VERSION ""

NS_ :

BS_:

BU_: HCM IPMA_ADAS PSCM ABS_ESC PCM ECM_HEV VDM CMR_DSMC SOBDMC_HPCM GWM _delete AWD_DLCM GENERIC TSTR

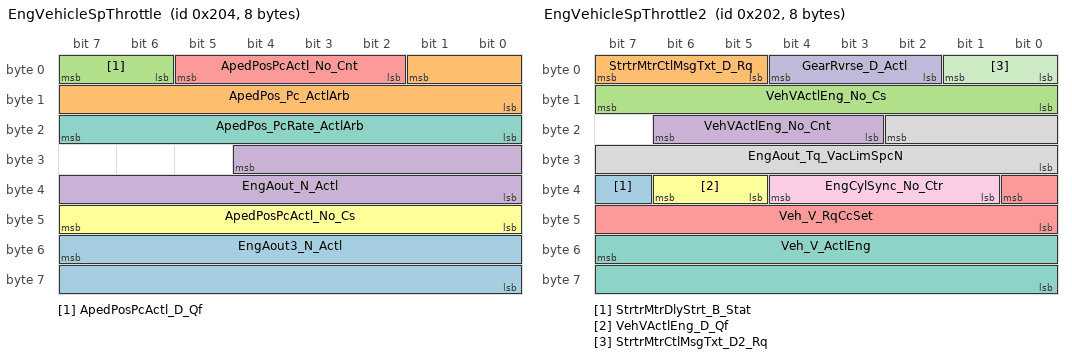
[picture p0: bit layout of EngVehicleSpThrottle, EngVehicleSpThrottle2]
BO_ 516 EngVehicleSpThrottle: 8 ECM_HEV
 SG_ EngAout3_N_Actl : 55|16@0+ (0.25,0) [0|16383.5] "RPM"  SOBDMC_HPCM,GWM
 SG_ ApedPos_Pc_ActlArb : 1|10@0+ (0.1,0) [0|102.3] "%"  CMR_DSMC,VDM,SOBDMC_HPCM,HCM,IPMA_ADAS,ABS_ESC,GWM,AWD_DLCM
 SG_ ApedPosPcActl_D_Qf : 7|2@0+ (1,0) [0|3] "SED"  CMR_DSMC,VDM,SOBDMC_HPCM,HCM,IPMA_ADAS,ABS_ESC,GWM,AWD_DLCM
 SG_ EngAout_N_Actl : 28|13@0+ (2,0) [0|16382] "rpm"  VDM,ABS_ESC,GWM,AWD_DLCM
 SG_ ApedPosPcActl_No_Cnt : 5|4@0+ (1,0) [0|15] "Unitless"  SOBDMC_HPCM,GWM
 SG_ ApedPosPcActl_No_Cs : 47|8@0+ (1,0) [0|255] "Unitless"  SOBDMC_HPCM,GWM
 SG_ ApedPos_PcRate_ActlArb : 23|8@0+ (0.04,-5) [-5|5.12] "%/ms"  SOBDMC_HPCM,AWD_DLCM,GWM

BO_ 514 EngVehicleSpThrottle2: 8 ECM_HEV
 SG_ StrtrMtrDlyStrt_B_Stat : 39|1@0+ (1,0) [0|1] "SED"  GWM
 SG_ StrtrMtrCtlMsgTxt_D_Rq : 7|3@0+ (1,0) [0|7] "SED"  GWM
 SG_ VehVActlEng_No_Cs : 15|8@0+ (1,0) [0|255] "Unitless"  PSCM,GWM
 SG_ VehVActlEng_No_Cnt : 22|4@0+ (1,0) [0|15] "Unitless"  PSCM,GWM
 SG_ Veh_V_RqCcSet : 32|9@0+ (0.5,0) [0|255.5] "kph"  SOBDMC_HPCM,IPMA_ADAS,GWM
 SG_ VehVActlEng_D_Qf : 38|2@0+ (1,0) [0|3] "SED"  HCM,IPMA_ADAS,PSCM,GWM,VDM,AWD_DLCM
 SG_ Veh_V_ActlEng : 55|16@0+ (0.01,0) [0|655.35] "kph"  SOBDMC_HPCM,HCM,IPMA_ADAS,PSCM,VDM,GWM,AWD_DLCM
 SG_ EngAout_Tq_VacLimSpcN : 18|11@0+ (1,-500) [-500|1547] "Nm"  SOBDMC_HPCM,GWM
 SG_ EngCylSync_No_Ctr : 36|4@0+ (1,0) [0|15] "unitless"  SOBDMC_HPCM,GWM
 SG_ GearRvrse_D_Actl : 4|3@0+ (1,0) [0|7] "SED"  IPMA_ADAS,CMR_DSMC,ABS_ESC,PSCM,GWM,HCM
 SG_ StrtrMtrCtlMsgTxt_D2_Rq : 1|2@0+ (1,0) [0|3] "SED"  GWM

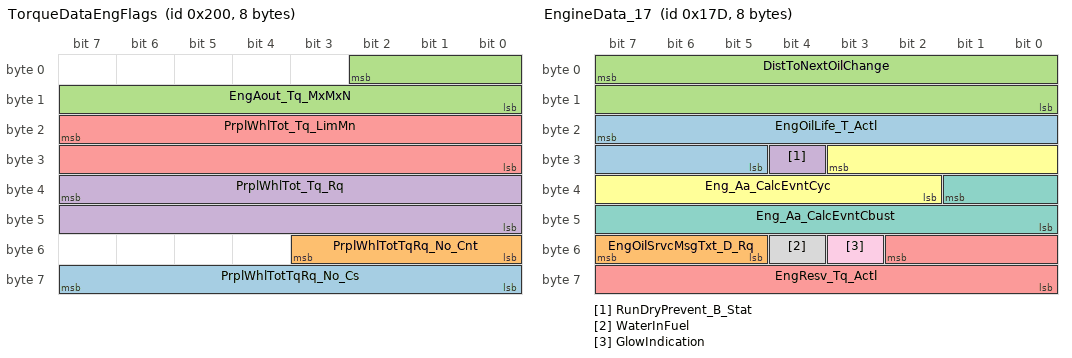
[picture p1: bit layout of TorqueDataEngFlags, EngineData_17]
BO_ 512 TorqueDataEngFlags: 8 ECM_HEV
 SG_ PrplWhlTotTqRq_No_Cs : 63|8@0+ (1,0) [0|255] "Unitless"  SOBDMC_HPCM,GWM
 SG_ PrplWhlTotTqRq_No_Cnt : 51|4@0+ (1,0) [0|15] "Unitless"  SOBDMC_HPCM,GWM
 SG_ EngAout_Tq_MxMxN : 2|11@0+ (1,-500) [-500|1547] "Nm"  SOBDMC_HPCM,GWM
 SG_ PrplWhlTot_Tq_Rq : 39|16@0+ (4,-131072) [-131072|131068] "Nm"  VDM,SOBDMC_HPCM,ABS_ESC,GWM,AWD_DLCM
 SG_ PrplWhlTot_Tq_LimMn : 23|16@0+ (4,-131072) [-131072|131068] "Nm"  GWM

BO_ 381 EngineData_17: 8 PCM
 SG_ EngOilLife_T_Actl : 23|11@0+ (1,0) [0|2047] "days"  GWM
 SG_ EngOilSrvcMsgTxt_D_Rq : 55|3@0+ (1,0) [0|7] "SED"  GWM
 SG_ DistToNextOilChange : 7|16@0+ (1,0) [0|65535] "unitless"  GWM
 SG_ RunDryPrevent_B_Stat : 28|1@0+ (1,0) [0|1] "SED"  GWM
 SG_ EngResv_Tq_Actl : 50|11@0+ (1,-500) [-500|1547] "Nm"  GWM
 SG_ Eng_Aa_CalcEvntCyc : 27|10@0+ (0.05,-25.6) [-25.6|25.55] "rpm/ms"  GWM
 SG_ Eng_Aa_CalcEvntCbust : 33|10@0+ (0.05,-25.6) [-25.6|25.55] "rpm/ms"  GWM
 SG_ WaterInFuel : 52|1@0+ (1,0) [0|1] "SED"  GWM
 SG_ GlowIndication : 51|1@0+ (1,0) [0|1] "SED"  GWM

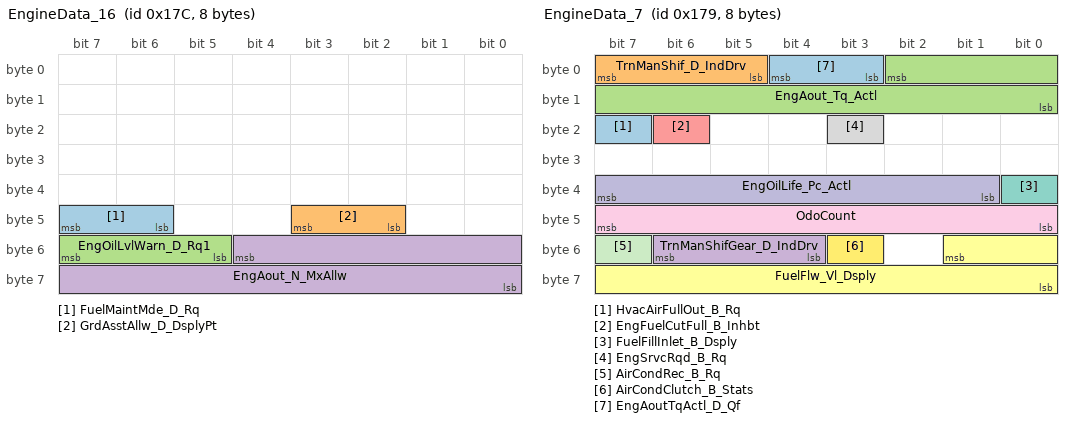
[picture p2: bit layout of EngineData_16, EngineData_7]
BO_ 380 EngineData_16: 8 PCM
 SG_ FuelMaintMde_D_Rq : 47|2@0+ (1,0) [0|3] "SED"  SOBDMC_HPCM,GWM
 SG_ GrdAsstAllw_D_DsplyPt : 43|2@0+ (1,0) [0|3] "SED"  SOBDMC_HPCM,GWM
 SG_ EngOilLvlWarn_D_Rq1 : 55|3@0+ (1,0) [0|7] "SED"  GWM
 SG_ EngAout_N_MxAllw : 52|13@0+ (2,0) [0|16382] "rpm"  SOBDMC_HPCM,GWM

BO_ 377 EngineData_7: 8 ECM_HEV
 SG_ HvacAirFullOut_B_Rq : 23|1@0+ (1,0) [0|1] "SED"  GWM
 SG_ TrnManShif_D_IndDrv : 7|3@0+ (1,0) [0|7] "Unitless"  GWM
 SG_ EngAout_Tq_Actl : 2|11@0+ (1,-500) [-500|1547] "Nm"  SOBDMC_HPCM,GWM
 SG_ TrnManShifGear_D_IndDrv : 54|3@0+ (1,0) [0|7] "SED"  GWM
 SG_ EngFuelCutFull_B_Inhbt : 22|1@0+ (1,0) [0|1] "SED"  SOBDMC_HPCM,GWM
 SG_ FuelFlw_Vl_Dsply : 49|10@0+ (25,0) [0|25575] "Micro_Liter"  SOBDMC_HPCM,GWM
 SG_ FuelFillInlet_B_Dsply : 32|1@0+ (1,0) [0|1] "SED"  GWM
 SG_ EngSrvcRqd_B_Rq : 19|1@0+ (1,0) [0|1] "SED"  GWM
 SG_ OdoCount : 47|8@0+ (0.2,0) [0|50.8] "Meters"  GWM
 SG_ EngOilLife_Pc_Actl : 39|7@0+ (1,0) [0|100] "Percent"  GWM
 SG_ AirCondRec_B_Rq : 55|1@0+ (1,0) [0|1] "SED"  GWM
 SG_ AirCondClutch_B_Stats : 51|1@0+ (1,0) [0|1] "SED"  GWM
 SG_ EngAoutTqActl_D_Qf : 4|2@0+ (1,0) [0|3] "SED"  SOBDMC_HPCM,GWM

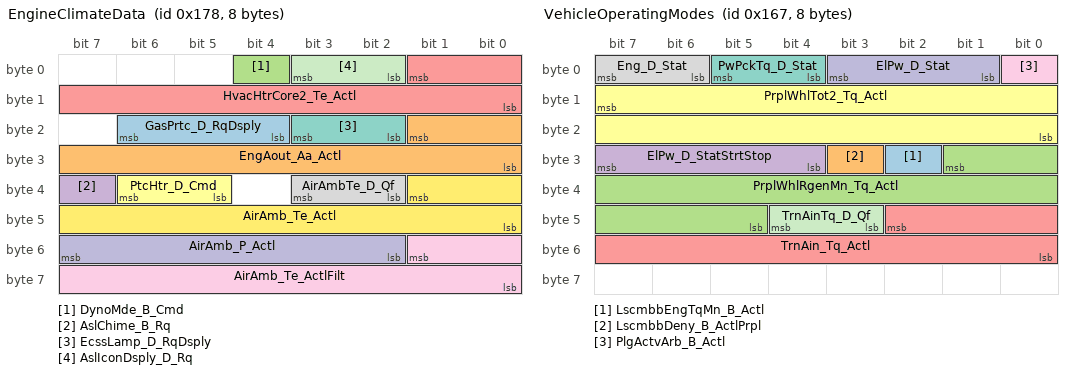
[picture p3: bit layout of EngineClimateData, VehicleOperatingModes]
BO_ 376 EngineClimateData: 8 ECM_HEV
 SG_ GasPrtc_D_RqDsply : 22|3@0+ (1,0) [0|7] "SED"  GWM
 SG_ EngAout_Aa_Actl : 17|10@0+ (0.05,-25.6) [-25.6|25.55] "rpm/ms"  ABS_ESC,GWM
 SG_ DynoMde_B_Cmd : 4|1@0+ (1,0) [0|1] "SED"  SOBDMC_HPCM,ABS_ESC,GWM
 SG_ AslChime_B_Rq : 39|1@0+ (1,0) [0|1] "SED"  GWM
 SG_ HvacHtrCore2_Te_Actl : 1|10@0+ (0.25,-50) [-50|205.5] "degC"  SOBDMC_HPCM,GWM
 SG_ PtcHtr_D_Cmd : 38|2@0+ (1,0) [0|3] "SED"  SOBDMC_HPCM,GWM
 SG_ EcssLamp_D_RqDsply : 19|2@0+ (1,0) [0|3] "SED"  GWM
 SG_ AirAmbTe_D_Qf : 35|2@0+ (1,0) [0|3] "SED"  SOBDMC_HPCM,IPMA_ADAS,ABS_ESC,GWM,AWD_DLCM
 SG_ AirAmb_Te_ActlFilt : 49|10@0+ (0.25,-128) [-128|127.75] "deg C"  SOBDMC_HPCM,IPMA_ADAS,GWM
 SG_ AirAmb_P_Actl : 55|6@0+ (10,500) [500|1110] "mbar"  GWM
 SG_ AslIconDsply_D_Rq : 3|2@0+ (1,0) [0|3] "SED"  GWM
 SG_ AirAmb_Te_Actl : 33|10@0+ (0.25,-128) [-128|127.75] "degC"  AWD_DLCM,ABS_ESC,GWM

BO_ 373 EngineData_11: 8 ECM_HEV
 SG_ EngFuelCutFull_B_Allw : 34|1@0+ (1,0) [0|1] "SED"  SOBDMC_HPCM,GWM
 SG_ EngAout_Tq_MxActlN : 2|11@0+ (1,-500) [-500|1547] "Nm"  GWM,GENERIC

BO_ 359 VehicleOperatingModes: 8 PCM
 SG_ LscmbbEngTqMn_B_Actl : 26|1@0+ (1,0) [0|1] "SED"  GWM
 SG_ LscmbbDeny_B_ActlPrpl : 27|1@0+ (1,0) [0|1] "SED"  GWM
 SG_ PrplWhlRgenMn_Tq_Actl : 25|13@0+ (4,-16380) [-16380|16380] "Nm"  ABS_ESC,GWM
 SG_ ElPw_D_StatStrtStop : 31|4@0+ (1,0) [0|15] "SED"  PSCM,GWM
 SG_ TrnAin_Tq_Actl : 42|11@0+ (1,-500) [-500|1547] "Nm"  GWM,AWD_DLCM
 SG_ PrplWhlTot2_Tq_Actl : 15|16@0+ (4,-131072) [-131072|131060] "Nm"  ABS_ESC,ECM_HEV,PSCM,GWM,AWD_DLCM
 SG_ PwPckTq_D_Stat : 5|2@0+ (1,0) [0|3] "SED"  VDM,HCM,IPMA_ADAS,ABS_ESC,ECM_HEV,PSCM,CMR_DSMC,GWM,AWD_DLCM
 SG_ Eng_D_Stat : 7|2@0+ (1,0) [0|3] "SED"  ABS_ESC,GWM,AWD_DLCM
 SG_ PlgActvArb_B_Actl : 0|1@0+ (1,0) [0|1] "SED"  GWM,ECM_HEV
 SG_ ElPw_D_Stat : 3|3@0+ (1,0) [0|7] "SED"  VDM,HCM,IPMA_ADAS,ABS_ESC,ECM_HEV,PSCM,GWM,CMR_DSMC,AWD_DLCM
 SG_ TrnAinTq_D_Qf : 44|2@0+ (1,0) [0|3] "SED"  GWM,AWD_DLCM

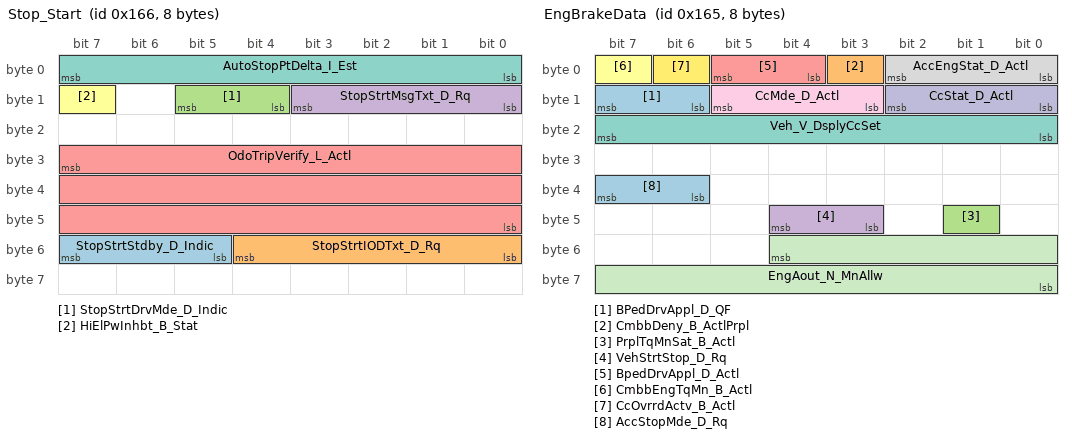
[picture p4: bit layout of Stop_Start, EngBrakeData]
BO_ 358 Stop_Start: 8 ECM_HEV
 SG_ StopStrtStdby_D_Indic : 55|3@0+ (1,0) [0|7] "SED"  GWM
 SG_ StopStrtIODTxt_D_Rq : 52|5@0+ (1,0) [0|31] "SED"  GWM
 SG_ StopStrtDrvMde_D_Indic : 13|2@0+ (1,0) [0|3] "SED"  GWM
 SG_ StopStrtMsgTxt_D_Rq : 11|4@0+ (1,0) [0|15] "SED"  GWM
 SG_ OdoTripVerify_L_Actl : 31|24@0+ (0.1,0) [0|1677721.4] "km"  GWM
 SG_ HiElPwInhbt_B_Stat : 15|1@0+ (1,0) [0|1] "SED"  GWM
 SG_ AutoStopPtDelta_I_Est : 7|8@0+ (1,-127) [-127|127] "Amps"  GWM

BO_ 357 EngBrakeData: 8 ECM_HEV
 SG_ BPedDrvAppl_D_QF : 15|2@0+ (1,0) [0|3] "SED"  SOBDMC_HPCM,IPMA_ADAS,ABS_ESC,GWM,CMR_DSMC,AWD_DLCM
 SG_ CmbbDeny_B_ActlPrpl : 3|1@0+ (1,0) [0|1] "SED"  IPMA_ADAS,GWM
 SG_ PrplTqMnSat_B_Actl : 41|1@0+ (1,0) [0|1] "SED"  IPMA_ADAS,GWM
 SG_ VehStrtStop_D_Rq : 44|2@0+ (1,0) [0|3] "SED"  SOBDMC_HPCM,GWM
 SG_ BpedDrvAppl_D_Actl : 5|2@0+ (1,0) [0|3] "SED"  SOBDMC_HPCM,IPMA_ADAS,ABS_ESC,GWM,CMR_DSMC,AWD_DLCM
 SG_ CmbbEngTqMn_B_Actl : 7|1@0+ (1,0) [0|1] "SED"  IPMA_ADAS,GWM
 SG_ Veh_V_DsplyCcSet : 23|8@0+ (1,0) [0|253] "Unitless"  GWM,IPMA_ADAS
 SG_ AccEngStat_D_Actl : 2|3@0+ (1,0) [0|7] "SED"  IPMA_ADAS,GWM
 SG_ CcMde_D_Actl : 13|3@0+ (1,0) [0|7] "SED"  GWM,VDM
 SG_ CcStat_D_Actl : 10|3@0+ (1,0) [0|7] "SED"  SOBDMC_HPCM,IPMA_ADAS,ABS_ESC,GWM,CMR_DSMC,AWD_DLCM
 SG_ EngAout_N_MnAllw : 52|13@0+ (2,0) [0|16382] "rpm"  SOBDMC_HPCM,GWM
 SG_ CcOvrrdActv_B_Actl : 6|1@0+ (1,0) [0|1] "SED"  IPMA_ADAS,ABS_ESC,GWM,VDM,AWD_DLCM
 SG_ AccStopMde_D_Rq : 39|2@0+ (1,0) [0|3] "SED"  IPMA_ADAS,ABS_ESC,GWM

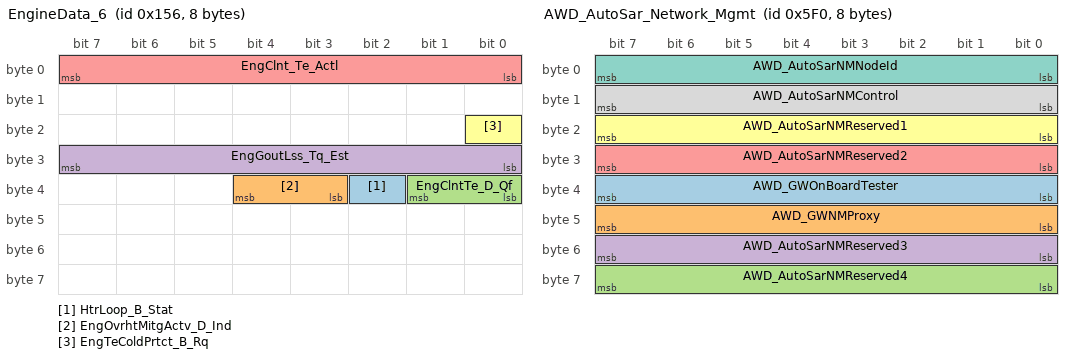
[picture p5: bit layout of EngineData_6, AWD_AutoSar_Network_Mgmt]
BO_ 342 EngineData_6: 8 ECM_HEV
 SG_ HtrLoop_B_Stat : 34|1@0+ (1,0) [0|1] "SED"  SOBDMC_HPCM,GWM
 SG_ EngOvrhtMitgActv_D_Ind : 36|2@0+ (1,0) [0|3] "SED"  GWM
 SG_ EngClntTe_D_Qf : 33|2@0+ (1,0) [0|3] "SED"  VDM,SOBDMC_HPCM,GWM,AWD_DLCM
 SG_ EngGoutLss_Tq_Est : 31|8@0+ (1,0) [0|255] "Nm"  SOBDMC_HPCM,GWM
 SG_ EngClnt_Te_Actl : 7|8@0+ (1,-60) [-60|195] "degC"  VDM,SOBDMC_HPCM,GWM,AWD_DLCM
 SG_ EngTeColdPrtct_B_Rq : 16|1@0+ (1,0) [0|1] "SED"  GWM

BO_ 1520 AWD_AutoSar_Network_Mgmt: 8 AWD_DLCM
 SG_ AWD_GWOnBoardTester : 39|8@0+ (1,0) [0|255] "unitless"  GENERIC
 SG_ AWD_GWNMProxy : 47|8@0+ (1,0) [0|255] "unitless"  GENERIC
 SG_ AWD_AutoSarNMReserved4 : 63|8@0+ (1,0) [0|255] "unitless"  GENERIC
 SG_ AWD_AutoSarNMReserved3 : 55|8@0+ (1,0) [0|255] "unitless"  GENERIC
 SG_ AWD_AutoSarNMReserved2 : 31|8@0+ (1,0) [0|255] "unitless"  GENERIC
 SG_ AWD_AutoSarNMReserved1 : 23|8@0+ (1,0) [0|255] "unitless"  GENERIC
 SG_ AWD_AutoSarNMNodeId : 7|8@0+ (1,0) [0|255] "unitless"  GENERIC
 SG_ AWD_AutoSarNMControl : 15|8@0+ (1,0) [0|255] "unitless"  GENERIC

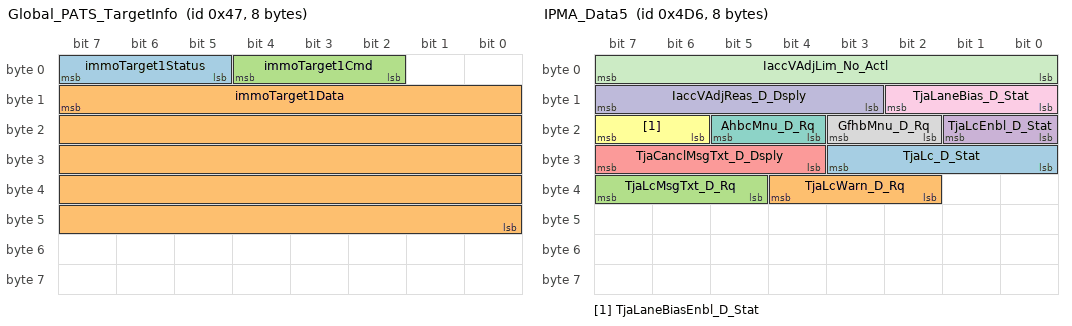
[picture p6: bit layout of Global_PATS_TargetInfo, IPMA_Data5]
BO_ 71 Global_PATS_TargetInfo: 8 SOBDMC_HPCM
 SG_ immoTarget1Status : 7|3@0+ (1,0) [0|7] "SED"  ECM_HEV,ABS_ESC,GWM
 SG_ immoTarget1Data : 15|40@0+ (1,0) [0|1099511627775] "Encrypted"  ABS_ESC,GWM
 SG_ immoTarget1Cmd : 4|3@0+ (1,0) [0|7] "SED"  ABS_ESC,GWM

BO_ 1229 IPMA_Data6: 8 IPMA_ADAS
 SG_ ExitNotClrRight_B_Stat : 6|1@0+ (1,0) [0|1] "SED"  GWM
 SG_ ExitNotClrLeft_B_Stat : 7|1@0+ (1,0) [0|1] "SED"  GWM

BO_ 1238 IPMA_Data5: 8 IPMA_ADAS
 SG_ TjaLc_D_Stat : 27|4@0+ (1,0) [0|15] "SED"  GWM
 SG_ TjaLcWarn_D_Rq : 36|3@0+ (1,0) [0|7] "SED"  GWM
 SG_ TjaLcMsgTxt_D_Rq : 39|3@0+ (1,0) [0|7] "SED"  GWM
 SG_ TjaLcEnbl_D_Stat : 17|2@0+ (1,0) [0|3] "SED"  GWM
 SG_ TjaCanclMsgTxt_D_Dsply : 31|4@0+ (1,0) [0|15] "SED"  GWM
 SG_ TjaLaneBiasEnbl_D_Stat : 23|2@0+ (1,0) [0|3] "SED"  GWM
 SG_ AhbcMnu_D_Rq : 21|2@0+ (1,0) [0|3] "SED"  GWM
 SG_ GfhbMnu_D_Rq : 19|2@0+ (1,0) [0|3] "SED"  GWM
 SG_ TjaLaneBias_D_Stat : 10|3@0+ (1,0) [0|7] "SED"  GWM
 SG_ IaccVAdjReas_D_Dsply : 15|5@0+ (1,0) [0|31] "SED"  GWM
 SG_ IaccVAdjLim_No_Actl : 7|8@0+ (1,0) [0|255] "unitless"  GWM

BO_ 2610126880 OTAPhysVDMtoGWM_ECG: 64 VDM
 SG_ OTAPhysVDMtoGWM_ECG : 7|29@0+ (1,0) [0|536870911] "unitless"  GWM

BO_ 2609938648 OTAPhysGWM_ECGtoVDM: 64 GWM
 SG_ OTAPhysGWM_ECGtoVDM : 7|29@0+ (1,0) [0|536870911] "unitless"  VDM

BO_ 2610987224 PARSEDPhysGWM_ECGtoVDM: 64 GWM
 SG_ PARSEDPhysGWM_ECGtoVDM : 7|29@0+ (1,0) [0|536870911] "unitless"  VDM

BO_ 2611175456 PARSEDPhysVDMtoGWM_ECG: 64 VDM
 SG_ PARSEDPhysVDMtoGWM_ECG : 7|29@0+ (1,0) [0|536870911] "unitless"  GWM

BO_ 2612035800 PARSEDPushFcGWM_ECGtoVDM: 8 GWM
 SG_ PARSEDPushFcGWM_ECGtoVDM : 7|29@0+ (1,0) [0|536870911] "unitless"  VDM

BO_ 2612224032 PARSEDPushVDMtoGWM_ECG: 8 VDM
 SG_ PARSEDPushVDMtoGWM_ECG : 7|29@0+ (1,0) [0|536870911] "unitless"  GWM

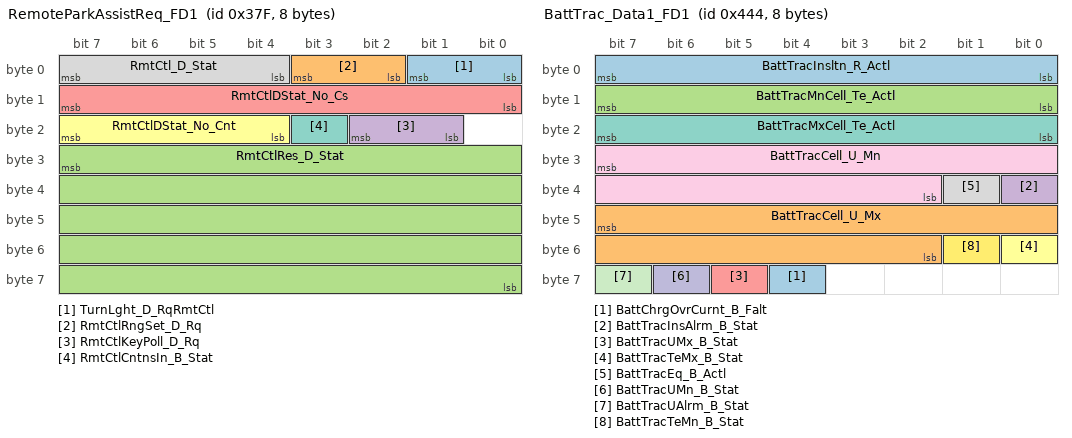
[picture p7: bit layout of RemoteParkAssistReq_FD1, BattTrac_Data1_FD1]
BO_ 895 RemoteParkAssistReq_FD1: 8 GWM
 SG_ TurnLght_D_RqRmtCtl : 1|2@0+ (1,0) [0|3] "SED"  GENERIC
 SG_ RmtCtlRngSet_D_Rq : 3|2@0+ (1,0) [0|3] "SED"  GENERIC
 SG_ RmtCtlRes_D_Stat : 31|40@0+ (1,0) [0|1099511627775] "unitless"  GENERIC
 SG_ RmtCtlKeyPoll_D_Rq : 18|2@0+ (1,0) [0|3] "SED"  GENERIC
 SG_ RmtCtlDStat_No_Cs : 15|8@0+ (1,0) [0|255] "Unitless"  SOBDMC_HPCM,ECM_HEV,ABS_ESC,IPMA_ADAS,PCM
 SG_ RmtCtlDStat_No_Cnt : 23|4@0+ (1,0) [0|15] "Unitless"  SOBDMC_HPCM,ECM_HEV,ABS_ESC,IPMA_ADAS,PCM
 SG_ RmtCtlCntnsIn_B_Stat : 19|1@0+ (1,0) [0|1] "SED"  GENERIC
 SG_ RmtCtl_D_Stat : 7|4@0+ (1,0) [0|15] "SED"  SOBDMC_HPCM,ECM_HEV,ABS_ESC,IPMA_ADAS,PCM

BO_ 1092 BattTrac_Data1_FD1: 8 GWM
 SG_ BattChrgOvrCurnt_B_Falt : 60|1@0+ (1,0) [0|1] "SED"  GENERIC
 SG_ BattTracCell_U_Mx : 47|14@0+ (0.001,0) [0|16.382] "volt" Vector__XXX
 SG_ BattTracMnCell_Te_Actl : 15|8@0+ (1,-40) [-40|213] "degC"  GENERIC
 SG_ BattTracInsAlrm_B_Stat : 32|1@0+ (1,0) [0|1] "SED"  GENERIC
 SG_ BattTracUMx_B_Stat : 61|1@0+ (1,0) [0|1] "SED"  GENERIC
 SG_ BattTracTeMx_B_Stat : 48|1@0+ (1,0) [0|1] "SED"  GENERIC
 SG_ BattTracMxCell_Te_Actl : 23|8@0+ (1,-40) [-40|213] "degC"  GENERIC
 SG_ BattTracEq_B_Actl : 33|1@0+ (1,0) [0|1] "SED"  GENERIC
 SG_ BattTracCell_U_Mn : 31|14@0+ (0.001,0) [0|16.382] "volt"  GENERIC
 SG_ BattTracUMn_B_Stat : 62|1@0+ (1,0) [0|1] "SED"  GENERIC
 SG_ BattTracUAlrm_B_Stat : 63|1@0+ (1,0) [0|1] "SED"  GENERIC
 SG_ BattTracTeMn_B_Stat : 49|1@0+ (1,0) [0|1] "SED"  GENERIC
 SG_ BattTracInsltn_R_Actl : 7|8@0+ (6000,0) [0|1524000] "ohm" Vector__XXX

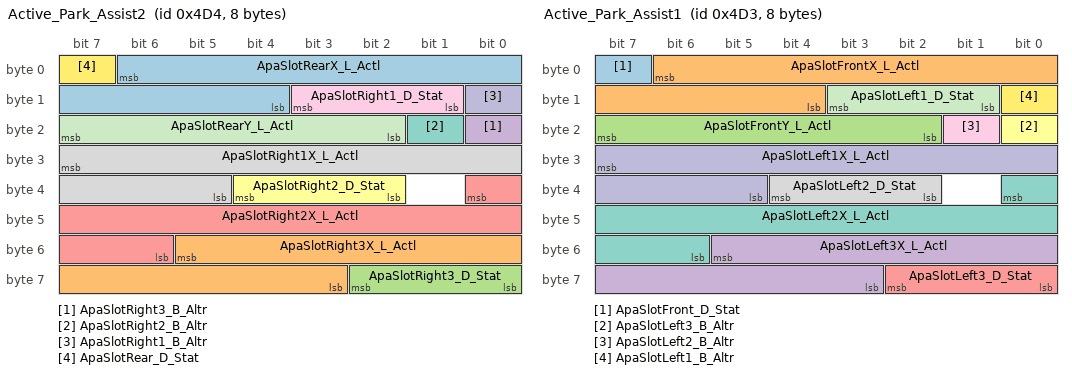
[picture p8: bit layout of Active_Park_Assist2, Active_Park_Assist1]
BO_ 1236 Active_Park_Assist2: 8 IPMA_ADAS
 SG_ ApaSlotRearX_L_Actl : 6|11@0+ (0.02,-20.96) [-20.96|19.98] "meter"  GWM
 SG_ ApaSlotRight3X_L_Actl : 53|11@0+ (0.02,-20.96) [-20.96|19.98] "meter"  GWM
 SG_ ApaSlotRight3_D_Stat : 58|3@0+ (1,0) [0|7] "SED"  GWM
 SG_ ApaSlotRight3_B_Altr : 16|1@0+ (1,0) [0|1] "SED"  GWM
 SG_ ApaSlotRight2X_L_Actl : 32|11@0+ (0.02,-20.96) [-20.96|19.98] "meter"  GWM
 SG_ ApaSlotRight2_D_Stat : 36|3@0+ (1,0) [0|7] "SED"  GWM
 SG_ ApaSlotRight2_B_Altr : 17|1@0+ (1,0) [0|1] "SED"  GWM
 SG_ ApaSlotRight1X_L_Actl : 31|11@0+ (0.02,-20.96) [-20.96|19.98] "meter"  GWM
 SG_ ApaSlotRight1_D_Stat : 11|3@0+ (1,0) [0|7] "SED"  GWM
 SG_ ApaSlotRight1_B_Altr : 8|1@0+ (1,0) [0|1] "SED"  GWM
 SG_ ApaSlotRearY_L_Actl : 23|6@0+ (0.2,-6.4) [-6.4|6.2] "meter"  GWM
 SG_ ApaSlotRear_D_Stat : 7|1@0+ (1,0) [0|1] "SED"  GWM

BO_ 1235 Active_Park_Assist1: 8 IPMA_ADAS
 SG_ ApaSlotFront_D_Stat : 7|1@0+ (1,0) [0|1] "SED"  GWM
 SG_ ApaSlotFrontX_L_Actl : 6|11@0+ (0.02,-20.96) [-20.96|19.98] "meter"  GWM
 SG_ ApaSlotFrontY_L_Actl : 23|6@0+ (0.2,-6.4) [-6.4|6.2] "meter"  GWM
 SG_ ApaSlotLeft3X_L_Actl : 53|11@0+ (0.02,-20.96) [-20.96|19.98] "meter"  GWM
 SG_ ApaSlotLeft3_D_Stat : 58|3@0+ (1,0) [0|7] "SED"  GWM
 SG_ ApaSlotLeft3_B_Altr : 16|1@0+ (1,0) [0|1] "SED"  GWM
 SG_ ApaSlotLeft2X_L_Actl : 32|11@0+ (0.02,-20.96) [-20.96|19.98] "meter"  GWM
 SG_ ApaSlotLeft2_D_Stat : 36|3@0+ (1,0) [0|7] "SED"  GWM
 SG_ ApaSlotLeft2_B_Altr : 17|1@0+ (1,0) [0|1] "SED"  GWM
 SG_ ApaSlotLeft1X_L_Actl : 31|11@0+ (0.02,-20.96) [-20.96|19.98] "meter"  GWM
 SG_ ApaSlotLeft1_D_Stat : 11|3@0+ (1,0) [0|7] "SED"  GWM
 SG_ ApaSlotLeft1_B_Altr : 8|1@0+ (1,0) [0|1] "SED"  GWM

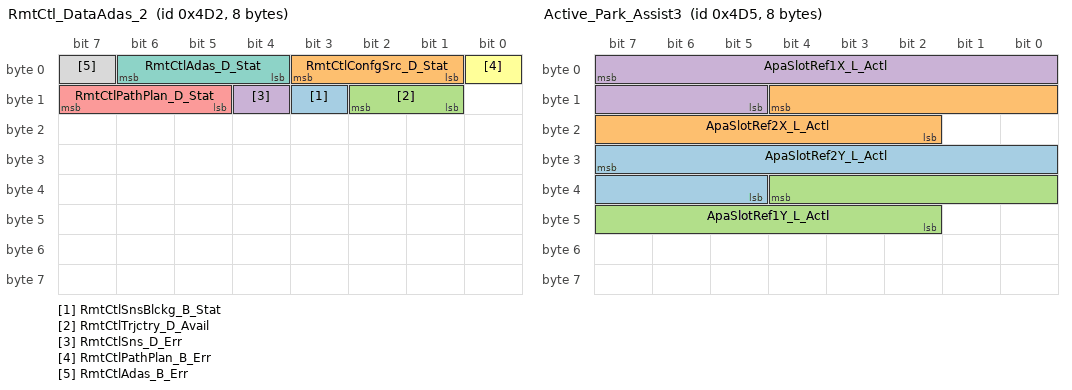
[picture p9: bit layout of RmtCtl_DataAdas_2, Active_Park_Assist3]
BO_ 1234 RmtCtl_DataAdas_2: 8 IPMA_ADAS
 SG_ RmtCtlSnsBlckg_B_Stat : 11|1@0+ (1,0) [0|1] "SED"  GWM
 SG_ RmtCtlConfgSrc_D_Stat : 3|3@0+ (1,0) [0|7] "SED"  GWM
 SG_ RmtCtlTrjctry_D_Avail : 10|2@0+ (1,0) [0|3] "SED"  GWM
 SG_ RmtCtlSns_D_Err : 12|1@0+ (1,0) [0|1] "SED"  GWM
 SG_ RmtCtlPathPlan_D_Stat : 15|3@0+ (1,0) [0|7] "SED"  GWM
 SG_ RmtCtlPathPlan_B_Err : 0|1@0+ (1,0) [0|1] "SED"  GWM
 SG_ RmtCtlAdas_D_Stat : 6|3@0+ (1,0) [0|7] "SED"  GWM
 SG_ RmtCtlAdas_B_Err : 7|1@0+ (1,0) [0|1] "SED"  GWM

BO_ 1233 RmtCtl_DataAdas_1: 8 IPMA_ADAS
 SG_ FreeDrvRear_D_Avail : 27|2@0+ (1,0) [0|3] "SED"  GWM
 SG_ FreeDrvFwd_D_Avail : 7|2@0+ (1,0) [0|3] "SED"  GWM
 SG_ RmtCtlTrgDist_D_Stat : 63|8@0+ (0.1,0) [0|25.5] "meter"  GWM
 SG_ RmtCtlSnsRrCrnr_D_Stat : 55|2@0+ (1,0) [0|3] "SED"  GWM
 SG_ RmtCtlSnsRlCrnr_D_Stat : 49|2@0+ (1,0) [0|3] "SED"  GWM
 SG_ RmtCtlSnsRear_D_Stat : 51|2@0+ (1,0) [0|3] "SED"  GWM
 SG_ RmtCtlSnsFront_D_Stat : 53|2@0+ (1,0) [0|3] "SED"  GWM
 SG_ RmtCtlSnsFrCrnr_D_Stat : 41|2@0+ (1,0) [0|3] "SED"  GWM
 SG_ RmtCtlSnsFlCrnr_D_Stat : 43|2@0+ (1,0) [0|3] "SED"  GWM
 SG_ RmtCtlSideSnsR4_D_Stat : 45|2@0+ (1,0) [0|3] "SED"  GWM
 SG_ RmtCtlSideSnsR3_D_Stat : 47|2@0+ (1,0) [0|3] "SED"  GWM
 SG_ RmtCtlSideSnsR2_D_Stat : 33|2@0+ (1,0) [0|3] "SED"  GWM
 SG_ RmtCtlSideSnsR1_D_Stat : 35|2@0+ (1,0) [0|3] "SED"  GWM
 SG_ RmtCtlSideSnsL4_D_Stat : 37|2@0+ (1,0) [0|3] "SED"  GWM
 SG_ RmtCtlSideSnsL3_D_Stat : 39|2@0+ (1,0) [0|3] "SED"  GWM
 SG_ RmtCtlSideSnsL2_D_Stat : 25|2@0+ (1,0) [0|3] "SED"  GWM
 SG_ RmtCtlSideSnsL1_D_Stat : 17|2@0+ (1,0) [0|3] "SED"  GWM
 SG_ RmtCtlRightOrnt_D_Avail : 20|3@0+ (1,0) [0|7] "SED"  GWM
 SG_ RmtCtlRight_D_Avail : 31|2@0+ (1,0) [0|3] "SED"  GWM
 SG_ RmtCtlRear_D_Avail : 29|2@0+ (1,0) [0|3] "SED"  GWM
 SG_ RmtCtlPrkMde_D_Stat : 9|2@0+ (1,0) [0|3] "SED"  GWM
 SG_ RmtCtlPrkInSlot_D_Stat : 23|3@0+ (1,0) [0|7] "SED"  GWM
 SG_ RmtCtlObstcl_B_Stat : 10|1@0+ (1,0) [0|1] "SED"  GWM
 SG_ RmtCtlNxtMoveDir_D_Stat : 12|2@0+ (1,0) [0|3] "SED"  GWM
 SG_ RmtCtlMoveDir_D_Stat : 1|2@0+ (1,0) [0|3] "SED"  GWM
 SG_ RmtCtlLeftOrnt_D_Avail : 15|3@0+ (1,0) [0|7] "SED"  GWM
 SG_ RmtCtlLeft_D_Avail : 3|2@0+ (1,0) [0|3] "SED"  GWM
 SG_ RmtCtlFront_D_Avail : 5|2@0+ (1,0) [0|3] "SED"  GWM

BO_ 1237 Active_Park_Assist3: 8 IPMA_ADAS
 SG_ ApaSlotRef2Y_L_Actl : 31|11@0+ (0.02,-20.96) [-20.96|19.98] "meter"  GWM
 SG_ ApaSlotRef2X_L_Actl : 12|11@0+ (0.02,-20.96) [-20.96|19.98] "meter"  GWM
 SG_ ApaSlotRef1Y_L_Actl : 36|11@0+ (0.02,-20.96) [-20.96|19.98] "meter"  GWM
 SG_ ApaSlotRef1X_L_Actl : 7|11@0+ (0.02,-20.96) [-20.96|19.98] "meter"  GWM

BO_ 1149 Battery_Traction_10_FD1: 8 GWM
 SG_ BattTracPerf_Pc_Dsply : 15|8@0+ (1,0) [0|253] "percent" Vector__XXX
 SG_ BattTracPerf_Pc_Actl : 7|8@0+ (1,0) [0|253] "percent" Vector__XXX

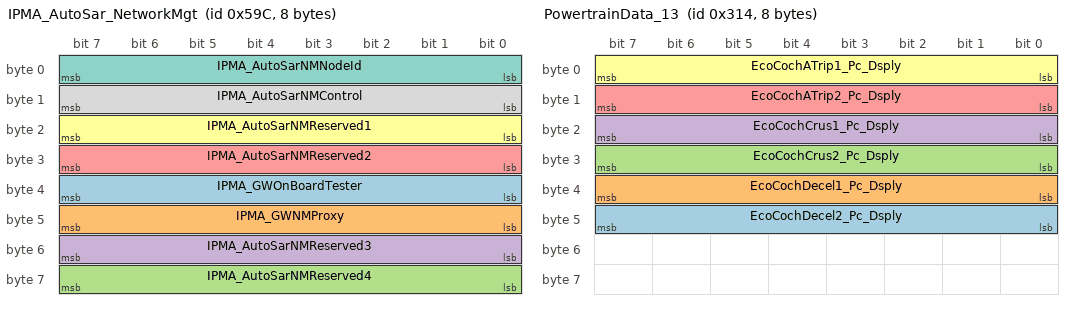
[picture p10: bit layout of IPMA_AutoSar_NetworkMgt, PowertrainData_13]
BO_ 1436 IPMA_AutoSar_NetworkMgt: 8 IPMA_ADAS
 SG_ IPMA_GWOnBoardTester : 39|8@0+ (1,0) [0|255] "unitless"  GWM,GENERIC
 SG_ IPMA_GWNMProxy : 47|8@0+ (1,0) [0|255] "unitless"  GWM,GENERIC
 SG_ IPMA_AutoSarNMReserved4 : 63|8@0+ (1,0) [0|255] "unitless"  GWM,GENERIC
 SG_ IPMA_AutoSarNMReserved3 : 55|8@0+ (1,0) [0|255] "unitless"  GWM,GENERIC
 SG_ IPMA_AutoSarNMReserved2 : 31|8@0+ (1,0) [0|255] "unitless"  GWM,GENERIC
 SG_ IPMA_AutoSarNMReserved1 : 23|8@0+ (1,0) [0|255] "unitless"  GWM,GENERIC
 SG_ IPMA_AutoSarNMNodeId : 7|8@0+ (1,0) [0|255] "unitless"  GWM,GENERIC
 SG_ IPMA_AutoSarNMControl : 15|8@0+ (1,0) [0|255] "unitless"  GWM,GENERIC

BO_ 788 PowertrainData_13: 8 PCM
 SG_ EcoCochDecel2_Pc_Dsply : 47|8@0+ (0.392157,0) [0|100.000035] "percent"  GWM
 SG_ EcoCochDecel1_Pc_Dsply : 39|8@0+ (0.392157,0) [0|100.000035] "percent"  GWM
 SG_ EcoCochCrus2_Pc_Dsply : 31|8@0+ (0.392157,0) [0|100.000035] "percent"  GWM
 SG_ EcoCochCrus1_Pc_Dsply : 23|8@0+ (0.392157,0) [0|100.000035] "percent"  GWM
 SG_ EcoCochATrip2_Pc_Dsply : 15|8@0+ (0.392157,0) [0|100.000035] "percent"  GWM
 SG_ EcoCochATrip1_Pc_Dsply : 7|8@0+ (0.392157,0) [0|100.000035] "percent"  GWM

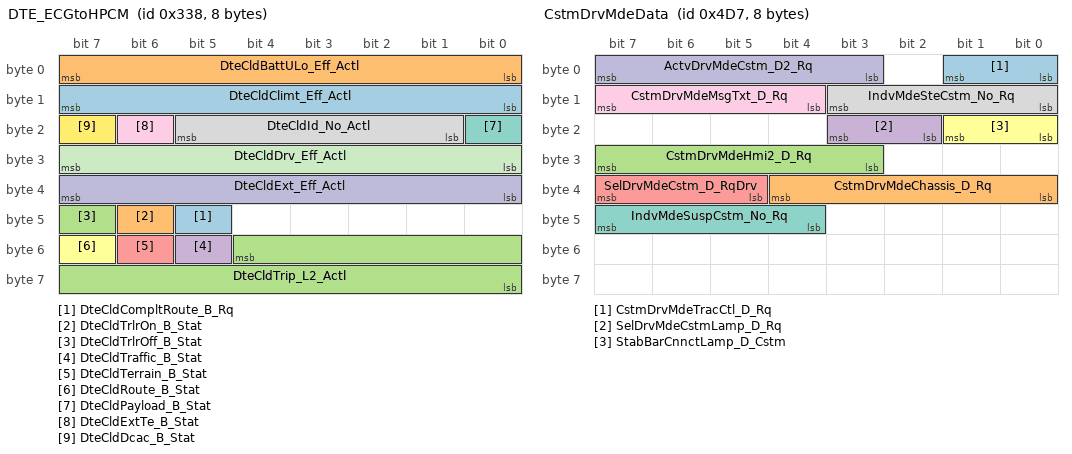
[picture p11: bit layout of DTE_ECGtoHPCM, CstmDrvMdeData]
BO_ 824 DTE_ECGtoHPCM: 8 GWM
 SG_ DteCldCompltRoute_B_Rq : 45|1@0+ (1,0) [0|1] "SED" Vector__XXX
 SG_ DteCldTrlrOn_B_Stat : 46|1@0+ (1,0) [0|1] "SED" Vector__XXX
 SG_ DteCldTrlrOff_B_Stat : 47|1@0+ (1,0) [0|1] "SED" Vector__XXX
 SG_ DteCldTraffic_B_Stat : 53|1@0+ (1,0) [0|1] "SED" Vector__XXX
 SG_ DteCldTerrain_B_Stat : 54|1@0+ (1,0) [0|1] "SED" Vector__XXX
 SG_ DteCldRoute_B_Stat : 55|1@0+ (1,0) [0|1] "SED" Vector__XXX
 SG_ DteCldPayload_B_Stat : 16|1@0+ (1,0) [0|1] "SED" Vector__XXX
 SG_ DteCldId_No_Actl : 21|5@0+ (1,0) [0|31] "unitless" Vector__XXX
 SG_ DteCldExtTe_B_Stat : 22|1@0+ (1,0) [0|1] "SED" Vector__XXX
 SG_ DteCldExt_Eff_Actl : 39|8@0+ (10,-1000) [-1000|1550] "watt*hour/km" Vector__XXX
 SG_ DteCldDrv_Eff_Actl : 31|8@0+ (10,-1000) [-1000|1550] "watt*hour/km" Vector__XXX
 SG_ DteCldDcac_B_Stat : 23|1@0+ (1,0) [0|1] "SED" Vector__XXX
 SG_ DteCldClimt_Eff_Actl : 15|8@0+ (10,-1000) [-1000|1550] "watt*hour/km" Vector__XXX
 SG_ DteCldBattULo_Eff_Actl : 7|8@0+ (10,-1000) [-1000|1550] "watt*hour/km" Vector__XXX
 SG_ DteCldTrip_L2_Actl : 52|13@0+ (0.1,0) [0|818.9] "kilometer" Vector__XXX

BO_ 811 APIM_Data_FD1: 8 GWM
 SG_ SpeedoMajorUnit_D_Confg : 59|2@0+ (1,0) [0|3] "SED"  SOBDMC_HPCM
 SG_ ScMnSoc_Pc_RqMnu : 55|7@0+ (1,0) [0|125] "percent"  SOBDMC_HPCM
 SG_ ScEnbl_D_RqMnu : 57|2@0+ (1,0) [0|3] "SED"  SOBDMC_HPCM
 SG_ OnePdlDrvButtn_B_Falt : 16|1@0+ (1,0) [0|1] "SED" Vector__XXX
 SG_ OnePdlDrvButtn_B_Stat : 48|1@0+ (1,0) [0|1] "SED" Vector__XXX
 SG_ DistToStopover_L_Actl : 31|16@0+ (0.1,0) [0|6553.4] "kilometer"  SOBDMC_HPCM
 SG_ StopoverType_D_Stat : 47|3@0+ (1,0) [0|0] "SED"  SOBDMC_HPCM
 SG_ ExtLghtDsply_D_Stat : 7|3@0+ (1,0) [0|7] "SED"  GENERIC
 SG_ ExtLghtRight_D_RqMnu : 11|3@0+ (1,0) [0|7] "SED"  GENERIC
 SG_ AutoLghtOvrrd_B_RqDrv : 8|1@0+ (1,0) [0|1] "SED"  GENERIC
 SG_ ExtLghtRear_D_RqMnu : 14|3@0+ (1,0) [0|7] "SED"  GENERIC
 SG_ LongTermReset_B_RqMnu : 17|1@0+ (1,0) [0|1] "SED"  SOBDMC_HPCM
 SG_ ExtLghtLeft_D_RqMnu : 1|3@0+ (1,0) [0|7] "SED"  GENERIC
 SG_ ExtLghtFront_D_RqMnu : 4|3@0+ (1,0) [0|7] "SED"  GENERIC
 SG_ GoTEditMnte_T_RqMnu : 63|4@0+ (1,0) [0|15] "SED"  SOBDMC_HPCM
 SG_ GoTEditHr_T_RqMnu : 44|5@0+ (1,0) [0|29] "SED"  SOBDMC_HPCM
 SG_ BecRleas_No_RqMnu : 23|3@0+ (1,0) [0|7] "unitless"  GENERIC
 SG_ TrnkFrontRleas_No_RqMnu : 20|3@0+ (1,0) [0|7] "unitless"  GENERIC

BO_ 942 ParkAid_Data_3: 8 IPMA_ADAS
 SG_ ApaOffOptnSel_B_Avail : 51|1@0+ (1,0) [0|1] "SED"  GWM
 SG_ PrkBrkElRleas_B_RqApa : 50|1@0+ (1,0) [0|1] "SED"  ABS_ESC,GWM
 SG_ ApaDrvRq2MsgTxt_D_Rq : 55|4@0+ (1,0) [0|15] "SED"  GWM
 SG_ ApaDrvRq1MsgTxt_D_Rq : 42|3@0+ (1,0) [0|7] "SED"  GWM
 SG_ ApaSys_D2_Stat : 35|4@0+ (1,0) [0|15] "SED"  GWM
 SG_ ApaSlotTrgt_D_Stat : 39|4@0+ (1,0) [0|15] "SED"  GWM
 SG_ ApaSlotOption_B_Avail : 43|1@0+ (1,0) [0|1] "SED"  GWM
 SG_ ApaSlotAlrtSet_B_Stat : 44|1@0+ (1,0) [0|1] "SED"  GWM
 SG_ ApaSlotAlrt_B_Rq : 45|1@0+ (1,0) [0|1] "SED"  GWM
 SG_ ApaRmtFeatSel_B_Avail : 46|1@0+ (1,0) [0|1] "SED"  GWM
 SG_ ApaParkOutSel_B_Avail : 47|1@0+ (1,0) [0|1] "SED"  GWM
 SG_ ApaParkInSel_B_Avail : 24|1@0+ (1,0) [0|1] "SED"  GWM
 SG_ ApaMsgTxt_D2_Stat : 28|4@0+ (1,0) [0|15] "SED"  GWM
 SG_ ApaDynmcSlot_B_Stat : 29|1@0+ (1,0) [0|1] "SED"  GWM
 SG_ ApaDisplayMode_D_Stat : 31|2@0+ (1,0) [0|3] "SED"  GWM
 SG_ ApaControlMode_D_Stat : 16|1@0+ (1,0) [0|1] "SED"  GWM
 SG_ PrkAidAcsyRear_D_Stat : 18|2@0+ (1,0) [0|3] "SED"  GWM
 SG_ PrkAidAcsyFront_D_Stat : 20|2@0+ (1,0) [0|3] "SED"  GWM
 SG_ PrkAidRdiusRight_L_Dsply : 15|8@0+ (1,0) [0|255] "unitless"  GWM
 SG_ PrkAidRdiusLeft_L_Dsply : 7|8@0+ (1,0) [0|255] "unitless"  GWM
 SG_ PrkAidDrvDir_D_Stat : 23|3@0+ (1,0) [0|7] "SED"  GWM

BO_ 123 Battery_Traction_2_FD1: 8 GWM
 SG_ BattTrac_U2_Actl : 21|12@0+ (0.5,0) [0|2046.5] "volt"  SOBDMC_HPCM,ECM_HEV
 SG_ BattTrac_I2_Actl : 7|18@0+ (0.05,-6553.52) [-6553.52|6553.53] "ampere"  SOBDMC_HPCM,ECM_HEV

BO_ 2612052184 PARSEDPushFcGWM_ECGtoPSCM: 8 GWM
 SG_ PARSEDPushFcGWM_ECGtoPSCM : 7|29@0+ (1,0) [0|536870911] "unitless"  PSCM

BO_ 2612224187 PARSEDPushCMRtoGWM_ECG: 8 CMR_DSMC
 SG_ PARSEDPushCMRtoGWM_ECG : 7|29@0+ (1,0) [0|536870911] "unitless"  GWM

BO_ 1239 CstmDrvMdeData: 8 GWM
 SG_ CstmDrvMdeTracCtl_D_Rq : 1|2@0+ (1,0) [0|3] "SED" Vector__XXX
 SG_ CstmDrvMdeChassis_D_Rq : 36|5@0+ (1,0) [0|31] "SED" Vector__XXX
 SG_ CstmDrvMdeHmi2_D_Rq : 31|5@0+ (1,0) [0|31] "SED" Vector__XXX
 SG_ SelDrvMdeCstmLamp_D_Rq : 19|2@0+ (1,0) [0|3] "SED"  GENERIC
 SG_ SelDrvMdeCstm_D_RqDrv : 39|3@0+ (1,0) [0|7] "SED" Vector__XXX
 SG_ StabBarCnnctLamp_D_Cstm : 17|2@0+ (1,0) [0|3] "SED" Vector__XXX
 SG_ IndvMdeSuspCstm_No_Rq : 47|4@0+ (1,0) [0|15] "unitless" Vector__XXX
 SG_ IndvMdeSteCstm_No_Rq : 11|4@0+ (1,0) [0|15] "unitless" Vector__XXX
 SG_ CstmDrvMdeMsgTxt_D_Rq : 15|4@0+ (1,0) [0|15] "SED"  GENERIC
 SG_ ActvDrvMdeCstm_D2_Rq : 7|5@0+ (1,0) [0|31] "SED" Vector__XXX

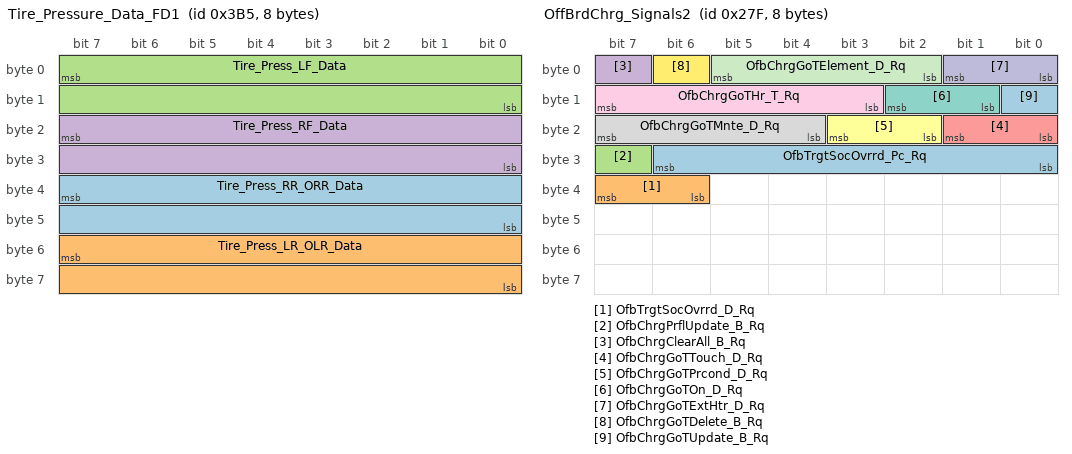
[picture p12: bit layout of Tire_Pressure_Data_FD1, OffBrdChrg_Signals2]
BO_ 949 Tire_Pressure_Data_FD1: 8 GWM
 SG_ Tire_Press_RR_ORR_Data : 39|16@0+ (1,0) [0|65533] "kilopascal"  VDM
 SG_ Tire_Press_LR_OLR_Data : 55|16@0+ (1,0) [0|65533] "kilopascal"  VDM
 SG_ Tire_Press_LF_Data : 7|16@0+ (1,0) [0|65533] "kilopascal"  VDM
 SG_ Tire_Press_RF_Data : 23|16@0+ (1,0) [0|65533] "kilopascal"  VDM

BO_ 2612074712 PARSEDPushFcGWMtoSODCMD: 8 GWM
 SG_ PARSEDPushFcGWMtoSODCMD : 7|29@0+ (1,0) [0|536870911] "unitless"  IPMA_ADAS

BO_ 2612024536 PARSEDPushFcGWM_ECGtoCCM: 8 GWM
 SG_ PARSEDPushFcGWM_ECGtoCCM : 7|29@0+ (1,0) [0|536870911] "unitless"  IPMA_ADAS

BO_ 2612036824 PARSEDPushFcGWM_ECGtoIPMA: 8 GWM
 SG_ PARSEDPushFcGWM_ECGtoIPMA : 7|29@0+ (1,0) [0|536870911] "unitless"  IPMA_ADAS

BO_ 2612103384 PARSEDPushFcGWMtoSODL: 8 GWM
 SG_ PARSEDPushFcGWM_ECGtoSODL : 7|29@0+ (1,0) [0|536870911] "unitless"  IPMA_ADAS

BO_ 639 OffBrdChrg_Signals2: 8 GWM
 SG_ OfbTrgtSocOvrrd_Pc_Rq : 30|7@0+ (1,0) [0|127] "percent"  SOBDMC_HPCM
 SG_ OfbTrgtSocOvrrd_D_Rq : 39|2@0+ (1,0) [0|3] "SED"  SOBDMC_HPCM
 SG_ OfbChrgPrflUpdate_B_Rq : 31|1@0+ (1,0) [0|1] "SED"  SOBDMC_HPCM
 SG_ OfbChrgClearAll_B_Rq : 7|1@0+ (1,0) [0|1] "SED"  SOBDMC_HPCM
 SG_ OfbChrgGoTTouch_D_Rq : 17|2@0+ (1,0) [0|3] "SED"  SOBDMC_HPCM
 SG_ OfbChrgGoTPrcond_D_Rq : 19|2@0+ (1,0) [0|3] "SED"  SOBDMC_HPCM
 SG_ OfbChrgGoTOn_D_Rq : 10|2@0+ (1,0) [0|3] "SED"  SOBDMC_HPCM
 SG_ OfbChrgGoTMnte_D_Rq : 23|4@0+ (1,0) [0|15] "minute"  SOBDMC_HPCM
 SG_ OfbChrgGoTHr_T_Rq : 15|5@0+ (1,0) [0|29] "hour"  SOBDMC_HPCM
 SG_ OfbChrgGoTExtHtr_D_Rq : 1|2@0+ (1,0) [0|3] "SED"  SOBDMC_HPCM
 SG_ OfbChrgGoTElement_D_Rq : 5|4@0+ (1,0) [0|15] "Unitless"  SOBDMC_HPCM
 SG_ OfbChrgGoTDelete_B_Rq : 6|1@0+ (1,0) [0|1] "SED"  SOBDMC_HPCM
 SG_ OfbChrgGoTUpdate_B_Rq : 8|1@0+ (1,0) [0|1] "SED"  SOBDMC_HPCM

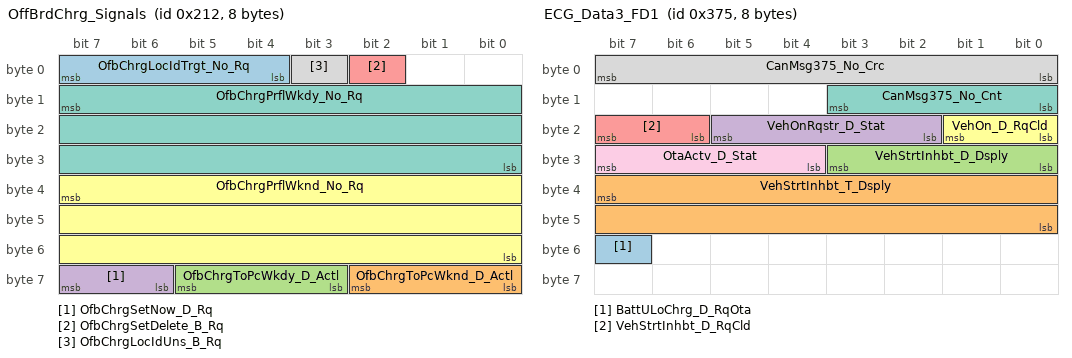
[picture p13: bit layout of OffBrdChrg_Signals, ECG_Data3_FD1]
BO_ 530 OffBrdChrg_Signals: 8 GWM
 SG_ OfbChrgLocIdTrgt_No_Rq : 7|4@0+ (1,0) [0|15] "Unitless"  SOBDMC_HPCM
 SG_ OfbChrgToPcWknd_D_Actl : 58|3@0+ (1,0) [0|7] "percent"  SOBDMC_HPCM
 SG_ OfbChrgToPcWkdy_D_Actl : 61|3@0+ (1,0) [0|7] "percent"  SOBDMC_HPCM
 SG_ OfbChrgSetNow_D_Rq : 63|2@0+ (1,0) [0|3] "SED"  SOBDMC_HPCM
 SG_ OfbChrgSetDelete_B_Rq : 2|1@0+ (1,0) [0|1] "SED"  SOBDMC_HPCM
 SG_ OfbChrgPrflWknd_No_Rq : 39|24@0+ (1,0) [0|16777215] "unitless"  SOBDMC_HPCM
 SG_ OfbChrgPrflWkdy_No_Rq : 15|24@0+ (1,0) [0|16777215] "unitless"  SOBDMC_HPCM
 SG_ OfbChrgLocIdUns_B_Rq : 3|1@0+ (1,0) [0|1] "SED"  SOBDMC_HPCM

BO_ 550 ECG_Data4_FD1: 8 GWM
 SG_ PtWakeupActv1_B_Rq : 7|1@0+ (1,0) [0|1] "SED"  SOBDMC_HPCM

BO_ 2612019416 PARSEDPushFcGWM_ECGtoPCM: 8 GWM
 SG_ PARSEDPushFcGWM_ECGtoPCM : 7|29@0+ (1,0) [0|536870911] "unitless"  ECM_HEV,PCM

BO_ 885 ECG_Data3_FD1: 8 GWM
 SG_ BattULoChrg_D_RqOta : 55|1@0+ (1,0) [0|1] "SED"  GENERIC
 SG_ VehStrtInhbt_T_Dsply : 39|16@0+ (1,0) [0|65535] "second"  GENERIC
 SG_ VehStrtInhbt_D_Dsply : 27|4@0+ (1,0) [0|15] "SED"  GENERIC
 SG_ VehOnRqstr_D_Stat : 21|4@0+ (1,0) [0|15] "SED"  GENERIC
 SG_ VehStrtInhbt_D_RqCld : 23|2@0+ (1,0) [0|3] "SED"  GENERIC
 SG_ VehOn_D_RqCld : 17|2@0+ (1,0) [0|3] "SED"  GENERIC
 SG_ CanMsg375_No_Cnt : 11|4@0+ (1,0) [0|15] "unitless"  GENERIC
 SG_ CanMsg375_No_Crc : 7|8@0+ (1,0) [0|255] "unitless"  GENERIC
 SG_ OtaActv_D_Stat : 31|4@0+ (1,0) [0|15] "SED"  SOBDMC_HPCM

BO_ 2612104408 PARSEDPushFcGWMtoSODR: 8 GWM
 SG_ PARSEDPushFcGWM_ECGtoSODR : 7|29@0+ (1,0) [0|536870911] "unitless"  IPMA_ADAS

BO_ 2612020440 PARSEDPushFcGWMtoSOBDMCFD1: 8 GWM
 SG_ PARSEDPushFcGWMtoSOBDMC : 7|29@0+ (1,0) [0|536870911] "unitless"  SOBDMC_HPCM

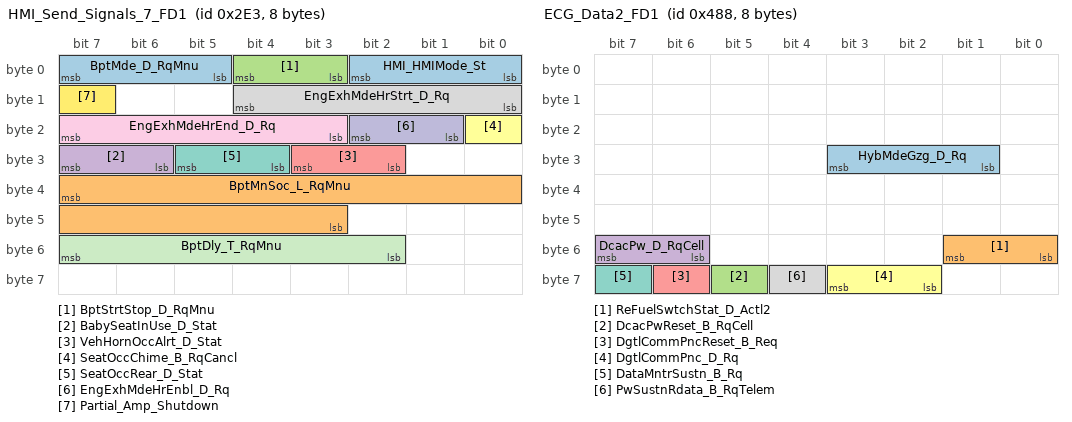
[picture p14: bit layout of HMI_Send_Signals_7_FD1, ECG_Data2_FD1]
BO_ 739 HMI_Send_Signals_7_FD1: 8 GWM
 SG_ BptMde_D_RqMnu : 7|3@0+ (1,0) [0|7] "SED" Vector__XXX
 SG_ BptMnSoc_L_RqMnu : 39|13@0+ (0.1,0) [0|818.9] "kilometer" Vector__XXX
 SG_ BptStrtStop_D_RqMnu : 4|2@0+ (1,0) [0|3] "SED" Vector__XXX
 SG_ BabySeatInUse_D_Stat : 31|2@0+ (1,0) [0|3] "SED"  GENERIC
 SG_ VehHornOccAlrt_D_Stat : 27|2@0+ (1,0) [0|3] "SED"  GENERIC
 SG_ SeatOccChime_B_RqCancl : 16|1@0+ (1,0) [0|1] "SED"  GENERIC
 SG_ SeatOccRear_D_Stat : 29|2@0+ (1,0) [0|3] "SED"  GENERIC
 SG_ EngExhMdeHrStrt_D_Rq : 12|5@0+ (1,0) [0|31] "SED" Vector__XXX
 SG_ EngExhMdeHrEnd_D_Rq : 23|5@0+ (1,0) [0|31] "SED" Vector__XXX
 SG_ EngExhMdeHrEnbl_D_Rq : 18|2@0+ (1,0) [0|3] "SED" Vector__XXX
 SG_ BptDly_T_RqMnu : 55|6@0+ (0.5,0) [0|30.5] "minute" Vector__XXX
 SG_ Partial_Amp_Shutdown : 15|1@0+ (1,0) [0|1] "SED"  GENERIC
 SG_ HMI_HMIMode_St : 2|3@0+ (1,0) [0|7] "SED"  ECM_HEV,PCM

BO_ 1160 ECG_Data2_FD1: 8 GWM
 SG_ HybMdeGzg_D_Rq : 27|3@0+ (1,0) [0|7] "SED"  SOBDMC_HPCM,PCM
 SG_ ReFuelSwtchStat_D_Actl2 : 49|2@0+ (1,0) [0|3] "SED"  ECM_HEV
 SG_ DcacPwReset_B_RqCell : 61|1@0+ (1,0) [0|1] "SED" Vector__XXX
 SG_ DcacPw_D_RqCell : 55|2@0+ (1,0) [0|3] "SED" Vector__XXX
 SG_ DgtlCommPncReset_B_Req : 62|1@0+ (1,0) [0|1] "SED"  GENERIC
 SG_ DgtlCommPnc_D_Rq : 59|2@0+ (1,0) [0|3] "SED"  GENERIC
 SG_ DataMntrSustn_B_Rq : 63|1@0+ (1,0) [0|1] "SED" Vector__XXX
 SG_ PwSustnRdata_B_RqTelem : 60|1@0+ (1,0) [0|1] "SED"  SOBDMC_HPCM,ECM_HEV

BO_ 1825 TesterPhysicalReqVDM_FD1: 64 TSTR
 SG_ TesterPhysicalReqVDM : 7|64@0+ (1,0) [0|1.84467E+019] "unitless"  VDM

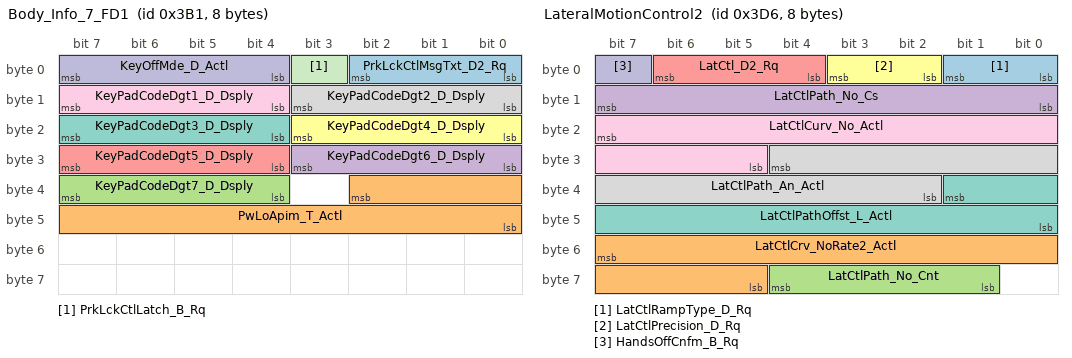
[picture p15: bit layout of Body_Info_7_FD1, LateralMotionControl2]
BO_ 945 Body_Info_7_FD1: 8 GWM
 SG_ PrkLckCtlMsgTxt_D2_Rq : 2|3@0+ (1,0) [0|7] "SED"  GENERIC
 SG_ PwLoApim_T_Actl : 34|11@0+ (1,0) [0|2047] "minute"  GENERIC
 SG_ KeyPadCodeDgt7_D_Dsply : 39|4@0+ (1,0) [0|15] "SED"  GENERIC
 SG_ KeyPadCodeDgt6_D_Dsply : 27|4@0+ (1,0) [0|15] "SED"  GENERIC
 SG_ KeyPadCodeDgt5_D_Dsply : 31|4@0+ (1,0) [0|15] "SED"  GENERIC
 SG_ KeyPadCodeDgt4_D_Dsply : 19|4@0+ (1,0) [0|15] "SED"  GENERIC
 SG_ KeyPadCodeDgt3_D_Dsply : 23|4@0+ (1,0) [0|15] "SED"  GENERIC
 SG_ KeyPadCodeDgt2_D_Dsply : 11|4@0+ (1,0) [0|15] "SED"  GENERIC
 SG_ KeyPadCodeDgt1_D_Dsply : 15|4@0+ (1,0) [0|15] "SED"  GENERIC
 SG_ KeyOffMde_D_Actl : 7|4@0+ (1,0) [0|15] "SED" Vector__XXX
 SG_ PrkLckCtlLatch_B_Rq : 3|1@0+ (1,0) [0|1] "SED"  GENERIC

BO_ 2612073688 PARSEDPushFcGWMtoSODCMC: 8 GWM
 SG_ PARSEDPushFcGWMtoSODCMC : 7|29@0+ (1,0) [0|536870911] "unitless"  IPMA_ADAS

BO_ 1833 TesterPhysicalResVDM: 64 VDM
 SG_ TesterPhysicalResVDM : 7|64@0+ (1,0) [0|1.84467E+019] "unitless"  TSTR

BO_ 395 HeadUpDisplayReq_FD1: 8 GWM
 SG_ SelDrvMdeCnfm_D_Stat : 35|2@0+ (1,0) [0|3] "SED"  AWD_DLCM,ABS_ESC
 SG_ HudShifPoint_N_Rq : 29|6@0+ (100,2000) [2000|8300] "rpm"  GENERIC
 SG_ HudMde_D_Rq : 38|3@0+ (1,0) [0|7] "SED"  GENERIC
 SG_ HudLedMde_D_Rq : 31|2@0+ (1,0) [0|3] "SED"  GENERIC
 SG_ HudLedIntns_Pc_Rq : 22|7@0+ (1,0) [0|127] "percent"  GENERIC
 SG_ HudLed9On_B_Rq : 15|1@0+ (1,0) [0|1] "SED"  GENERIC
 SG_ HudLed8On_B_Rq : 0|1@0+ (1,0) [0|1] "SED"  GENERIC
 SG_ HudLed7On_B_Rq : 1|1@0+ (1,0) [0|1] "SED"  GENERIC
 SG_ HudLed6On_B_Rq : 2|1@0+ (1,0) [0|1] "SED"  GENERIC
 SG_ HudLed5On_B_Rq : 3|1@0+ (1,0) [0|1] "SED"  GENERIC
 SG_ HudLed4On_B_Rq : 4|1@0+ (1,0) [0|1] "SED"  GENERIC
 SG_ HudLed3On_B_Rq : 5|1@0+ (1,0) [0|1] "SED"  GENERIC
 SG_ HudLed2On_B_Rq : 6|1@0+ (1,0) [0|1] "SED"  GENERIC
 SG_ HudLed1On_B_Rq : 7|1@0+ (1,0) [0|1] "SED"  GENERIC
 SG_ HudLed18On_B_Rq : 39|1@0+ (1,0) [0|1] "SED"  GENERIC
 SG_ HudLed17On_B_Rq : 23|1@0+ (1,0) [0|1] "SED"  GENERIC
 SG_ HudLed16On_B_Rq : 8|1@0+ (1,0) [0|1] "SED"  GENERIC
 SG_ HudLed15On_B_Rq : 9|1@0+ (1,0) [0|1] "SED"  GENERIC
 SG_ HudLed14On_B_Rq : 10|1@0+ (1,0) [0|1] "SED"  GENERIC
 SG_ HudLed13On_B_Rq : 11|1@0+ (1,0) [0|1] "SED"  GENERIC
 SG_ HudLed12On_B_Rq : 12|1@0+ (1,0) [0|1] "SED"  GENERIC
 SG_ HudLed11On_B_Rq : 13|1@0+ (1,0) [0|1] "SED"  GENERIC
 SG_ HudLed10On_B_Rq : 14|1@0+ (1,0) [0|1] "SED"  GENERIC

BO_ 542 LocationServices_3_FD1: 8 GWM
 SG_ LocationServices_3 : 7|64@0+ (1,0) [0|1.84467440737096E+019] "unitless"  IPMA_ADAS

BO_ 515 PowertrainData_12: 8 PCM
 SG_ PtIgnSwtch_D_Stat : 7|2@0+ (1,0) [0|3] "SED"  GWM

BO_ 982 LateralMotionControl2: 8 IPMA_ADAS
 SG_ LatCtlRampType_D_Rq : 1|2@0+ (1,0) [0|3] "SED"  PSCM
 SG_ LatCtlCrv_NoRate2_Actl : 55|11@0+ (1E-006,-0.001024) [-0.001024|0.001023] "meter^2"  PSCM
 SG_ LatCtlPath_No_Cnt : 60|4@0+ (1,0) [0|15] "Unitless"  PSCM
 SG_ LatCtlPath_No_Cs : 15|8@0+ (1,0) [0|255] "Unitless"  PSCM
 SG_ LatCtl_D2_Rq : 6|3@0+ (1,0) [0|7] "SED"  PSCM
 SG_ LatCtlPrecision_D_Rq : 3|2@0+ (1,0) [0|3] "SED"  PSCM
 SG_ LatCtlPathOffst_L_Actl : 33|10@0+ (0.01,-5.12) [-5.12|5.11] "meter"  PSCM
 SG_ LatCtlPath_An_Actl : 28|11@0+ (0.0005,-0.5) [-0.5|0.5235] "radians"  PSCM
 SG_ LatCtlCurv_No_Actl : 23|11@0+ (2E-005,-0.02) [-0.02|0.02094] "1/meter"  PSCM
 SG_ HandsOffCnfm_B_Rq : 7|1@0+ (1,0) [0|1] "SED"  PSCM

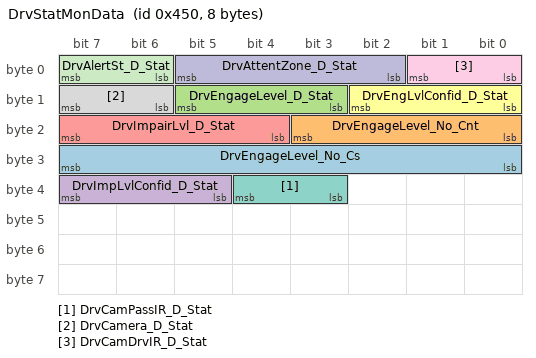
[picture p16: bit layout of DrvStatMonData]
BO_ 1104 DrvStatMonData: 8 CMR_DSMC
 SG_ DrvEngageLevel_No_Cs : 31|8@0+ (1,0) [0|255] "Unitless"  IPMA_ADAS
 SG_ DrvEngageLevel_No_Cnt : 19|4@0+ (1,0) [0|15] "Unitless"  IPMA_ADAS
 SG_ DrvEngageLevel_D_Stat : 13|3@0+ (1,0) [0|7] "SED"  IPMA_ADAS
 SG_ DrvImpLvlConfid_D_Stat : 39|3@0+ (1,0) [0|7] "SED"  IPMA_ADAS
 SG_ DrvImpairLvl_D_Stat : 23|4@0+ (1,0) [0|15] "SED"  IPMA_ADAS
 SG_ DrvEngLvlConfid_D_Stat : 10|3@0+ (1,0) [0|7] "SED"  IPMA_ADAS
 SG_ DrvCamPassIR_D_Stat : 36|2@0+ (1,0) [0|3] "SED"  IPMA_ADAS
 SG_ DrvCamera_D_Stat : 15|2@0+ (1,0) [0|3] "SED"  IPMA_ADAS
 SG_ DrvCamDrvIR_D_Stat : 1|2@0+ (1,0) [0|3] "SED"  IPMA_ADAS
 SG_ DrvAttentZone_D_Stat : 5|4@0+ (1,0) [0|15] "SED"  IPMA_ADAS
 SG_ DrvAlertSt_D_Stat : 7|2@0+ (1,0) [0|3] "SED"  IPMA_ADAS

BO_ 2610021592 OTAPhysGWM_ECGtoHCM: 64 GWM
 SG_ OTAPhysGWM_ECGtoHCM : 7|29@0+ (1,0) [0|536870911] "unitless"  GENERIC

BO_ 2610975960 PARSEDPhysGWM_ECGtoCCM: 64 GWM
 SG_ PARSEDPhysGWM_ECGtoCCM : 7|29@0+ (1,0) [0|536870911] "unitless"  IPMA_ADAS

BO_ 2611175445 PARSEDPhysCCMtoGWM_ECG: 64 IPMA_ADAS
 SG_ PARSEDPhysCCMtoGWM_ECG : 7|29@0+ (1,0) [0|536870911] "unitless"  GWM

BO_ 2612224021 PARSEDPushCCMtoGWM_ECG: 8 IPMA_ADAS
 SG_ PARSEDPushCCMtoGWM_ECG : 7|29@0+ (1,0) [0|536870911] "unitless"  GWM

BO_ 2611025112 PARSEDPhysGWM_ECGtoSODCMC: 64 GWM
 SG_ PARSEDPhysGWM_ECGtoSODCMC : 7|29@0+ (1,0) [0|536870911] "unitless"  IPMA_ADAS

BO_ 2611175493 PARSEDPhysSODCMCtoGWM_ECG: 64 IPMA_ADAS
 SG_ PARSEDPhysSODCMCtoGWM_ECG : 7|29@0+ (1,0) [0|536870911] "unitless"  GWM

BO_ 2612224069 PARSEDPushSODCMCtoGWM: 8 IPMA_ADAS
 SG_ PARSEDPushSODCMCtoGWM : 7|29@0+ (1,0) [0|536870911] "unitless"  GWM

BO_ 1787 TesterPhysicalResSODCMD: 64 IPMA_ADAS
 SG_ TesterPhysicalResSODCMD : 7|64@0+ (1,0) [0|1.84467E+019] "unitless"  TSTR

BO_ 1779 TesterPhysicalReqSODCMD: 64 TSTR
 SG_ TesterPhysicalReqSODCMD : 7|64@0+ (1,0) [0|1.84467E+019] "unitless"  IPMA_ADAS

BO_ 1786 TesterPhysicalResSODCMC: 64 IPMA_ADAS
 SG_ TesterPhysicalResSODCMC : 7|64@0+ (1,0) [0|1.84467E+019] "unitless"  TSTR

BO_TX_BU_ 516 : PCM,ECM_HEV;
BO_TX_BU_ 514 : PCM,ECM_HEV;
BO_TX_BU_ 512 : PCM,ECM_HEV;
BO_TX_BU_ 381 : ECM_HEV,PCM;
BO_TX_BU_ 380 : ECM_HEV,PCM;
BO_TX_BU_ 377 : PCM,ECM_HEV;
BO_TX_BU_ 376 : PCM,ECM_HEV;
BO_TX_BU_ 359 : SOBDMC_HPCM,PCM;
BO_TX_BU_ 358 : PCM,ECM_HEV;
BO_TX_BU_ 357 : PCM,ECM_HEV;
BO_TX_BU_ 342 : PCM,ECM_HEV;
BO_TX_BU_ 71 : PCM,SOBDMC_HPCM;
BO_TX_BU_ 788 : ECM_HEV,PCM;
BO_TX_BU_ 515 : SOBDMC_HPCM,PCM;
CM_ SG_ 516 EngAout3_N_Actl "Signal not transmitted on gas and diesel variants.";
CM_ SG_ 516 ApedPosPcActl_No_Cnt "Signal not transmitted on gas and diesel variants.";
CM_ SG_ 516 ApedPosPcActl_No_Cs "Signal not transmitted on gas and diesel variants.";
CM_ SG_ 514 EngAout_Tq_VacLimSpcN "Signal not transmitted on gas and diesel variances.";
CM_ SG_ 514 EngCylSync_No_Ctr "Signal not transmitted on gas and diesel variances.";
CM_ SG_ 514 GearRvrse_D_Actl "Do not implement GearRvrse_D_Actl  until eTracker 8804151 is approved, 11/24/09";
CM_ SG_ 512 PrplWhlTotTqRq_No_Cs "Signal not transmitted on gas variants.";
CM_ SG_ 512 PrplWhlTotTqRq_No_Cnt "Signal not transmitted on gas variants.";
CM_ SG_ 512 EngAout_Tq_MxMxN "Signal not transmitted on gas variants.";
CM_ SG_ 377 EngFuelCutFull_B_Inhbt "Signal not transmitted on diesel variants.";
CM_ SG_ 377 FuelFlw_Vl_Dsply "Signal not transmitted on diesel variants.";
CM_ SG_ 377 FuelFillInlet_B_Dsply "Signal not transmitted on diesel variants.";
CM_ SG_ 377 OdoCount "Signal not transmitted on diesel variants.";
CM_ SG_ 377 EngOilLife_Pc_Actl "Signal not transmitted on diesel variants.";
CM_ SG_ 377 AirCondRec_B_Rq "Signal not transmitted on diesel variants.";
CM_ SG_ 377 AirCondClutch_B_Stats "Signal not transmitted on diesel variants.";
CM_ SG_ 376 EngAout_Aa_Actl "Signal not transmitted on HEV variants.";
CM_ SG_ 373 EngFuelCutFull_B_Allw "Signal not transmitted on diesel variances.";
CM_ SG_ 373 EngAout_Tq_MxActlN "Signal not transmitted on diesel variances.";
CM_ SG_ 359 TrnAin_Tq_Actl "Signal not transmitted on HEV variances.";
CM_ SG_ 359 PlgActvArb_B_Actl "Only supported on PHEV programs.  PlgActvArb_B_Actl HPCM will Tx on Powersplit PHEV’s,  On MHT PHEVs the PCM_HEV will Tx and HPCM will Rx. 
";
CM_ SG_ 359 TrnAinTq_D_Qf "Signal not transmitted on HEV variances.";
CM_ SG_ 358 HiElPwInhbt_B_Stat "Signal not transmitted on HEV programs";
CM_ SG_ 358 AutoStopPtDelta_I_Est "Signal not transmitted on vehicles that do not have autostop/stop-start feature.";
CM_ SG_ 342 EngOvrhtMitgActv_D_Ind "Signal not transmitted on diesel.";
CM_ SG_ 342 EngGoutLss_Tq_Est "Signal not transmitted on gas and diesel variants.";
CM_ BO_ 71 "Provide target function info. to control function of PATS";
CM_ SG_ 942 PrkAidRdiusRight_L_Dsply "MSGDCR 679, set all signals to OnChange";
CM_ SG_ 942 PrkAidRdiusLeft_L_Dsply "MSGDCR 679, set all signals to OnChange";
CM_ SG_ 942 PrkAidDrvDir_D_Stat "MSGDCR 679, set all signals to OnChange";
CM_ BO_ 949 "For 2010MY and beyond, use for SCT (non-CGEA) and CGEA modules";
CM_ SG_ 550 PtWakeupActv1_B_Rq "ECG Application signal";
CM_ BO_ 885 "NOTE: START BITS 8-11 MUST BE OPEN SPEC REQUIREMENT";
CM_ BO_ 739 "FCDIM Tx";
CM_ SG_ 739 Partial_Amp_Shutdown "Method Partial_Amp_Shutdown";
CM_ SG_ 739 HMI_HMIMode_St "Object ACU System Master.HMIMode
OR
Object NAV System Master.HMIMode

Refer Method HMIAudioMode in the SPSS";
CM_ BO_ 1160 "some signals from HS4 0x22A TCU_EM in CGEA1.3";
CM_ SG_ 542 LocationServices_3 "Tx by HS3 APIM";
CM_ SG_ 982 LatCtlPath_No_Cnt "Signal not transmitted on gas variants.";
CM_ SG_ 982 LatCtlPath_No_Cs "Signal not transmitted on gas variants.";
CM_ SG_ 1104 DrvEngageLevel_No_Cs "Signal not transmitted on gas variants.";
CM_ SG_ 1104 DrvEngageLevel_No_Cnt "Signal not transmitted on gas variants.";
BA_DEF_ SG_  "U_CDX706_MY2023_Tx" ENUM  "No","Yes";
BA_DEF_ SG_  "U_CDX706_MY2023_Rx" ENUM  "No","Yes";
BA_DEF_ BO_  "AuthFreshnessCounterSyncAttempt" INT 0 2;
BA_DEF_ BO_  "VFrameFormat" ENUM  "StandardCAN","ExtendedCAN","reserved","reserved","reserved","reserved","reserved","reserved","reserved","reserved","reserved","reserved","reserved","reserved","StandardCAN_FD","ExtendedCAN_FD";
BA_DEF_ SG_  "GenSigSendType" ENUM  "Cyclic","OnWrite","vector_leerstring","OnChange","vector_leerstring","IfActive","vector_leerstring","NoSigSendType";
BA_DEF_ SG_  "GenSigInactiveValue" INT 0 100000;
BA_DEF_ SG_  "WakeupSignal" ENUM  "No","Yes";
BA_DEF_ SG_  "UsedOnPgmDBC" ENUM  "No","Yes";
BA_DEF_ SG_  "GenSigStartValueInteger" INT 0 1000000000;
BA_DEF_ SG_  "ContentDependant" ENUM  "No","Yes";
BA_DEF_ SG_  "MetaData" ENUM  "No","Yes";
BA_DEF_ SG_  "GenSigStartValue" HEX 0 268435455;
BA_DEF_ SG_  "U_CX727_MY2021_Rx" ENUM  "No","Yes";
BA_DEF_ SG_  "U_P702_MY2021_Rx" ENUM  "No","Yes";
BA_DEF_ SG_  "U_T6_MCA_MY2020_Rx" ENUM  "No","Yes";
BA_DEF_ SG_  "ECGUsedRxSignal" ENUM  "No","Yes";
BA_DEF_ SG_  "U_CD542_MY2021_Rx" ENUM  "No","Yes";
BA_DEF_ SG_  "U_U55X_MY2022_Rx" ENUM  "No","Yes";
BA_DEF_ SG_  "U_CD764_MY2022_Rx" ENUM  "No","Yes";
BA_DEF_ SG_  "U_CX727_MY2021_Tx" ENUM  "No","Yes";
BA_DEF_ SG_  "U_P702_MY2021_Tx" ENUM  "No","Yes";
BA_DEF_ SG_  "U_T6_MCA_MY2020_Tx" ENUM  "No","Yes";
BA_DEF_ SG_  "ECGUsedTxSignal" ENUM  "No","Yes";
BA_DEF_ SG_  "U_CD542_MY2021_Tx" ENUM  "No","Yes";
BA_DEF_ SG_  "U_U55X_MY2022_Tx" ENUM  "No","Yes";
BA_DEF_ SG_  "U_CD764_MY2022_Tx" ENUM  "No","Yes";
BA_DEF_ BO_  "GenMsgILSupport" ENUM  "No","Yes";
BA_DEF_ BO_  "DiagResponse" ENUM  "No","Yes";
BA_DEF_ BO_  "DiagRequest" ENUM  "No","Yes";
BA_DEF_ BO_  "TpTxIndex" INT 0 536870911;
BA_DEF_ BO_  "DiagState" ENUM  "No","Yes";
BA_DEF_ BO_  "TpApplType" STRING ;
BA_DEF_ BO_  "NmAsrMessage" ENUM  "No","Yes";
BA_DEF_ BO_  "SCP_AuthInfoTxLength" INT 0 512;
BA_DEF_ BO_  "SCP_FreshnessValueTxLength" INT 0 512;
BA_DEF_ BO_  "SCP_FreshnessValueLength" INT 0 512;
BA_DEF_ BO_  "OvtpPushApplication" ENUM  "FALSE","TRUE";
BA_DEF_ BO_  "GenMsgSendType" ENUM  "FixedPeriodic","Event","EnabledPeriodic","NotUsed","NotUsed","EventPeriodic","NotUsed","NotUsed","NoMsgSendType";
BA_DEF_ BO_  "GenMsgCycleTime" INT 0 100000;
BA_DEF_ BO_  "GenMsgDelayTime" INT 0 1000;
BA_DEF_ BO_  "GenMsgNrOfRepetition" INT 0 100;
BA_DEF_ BO_  "GenMsgStartDelayTime" INT 0 10000;
BA_DEF_ BO_  "EventRateOfChange" INT 10 10000;
BA_DEF_ BO_  "FrameGatewayId" HEX 0 1407;
BA_DEF_ BO_  "NetworkInitialization" ENUM  "No","Yes";
BA_DEF_ BO_  "FrameGatewayNetwork" STRING ;
BA_DEF_ BO_  "FrameRouting" STRING ;
BA_DEF_DEF_  "U_CDX706_MY2023_Tx" "No";
BA_DEF_DEF_  "U_CDX706_MY2023_Rx" "No";
BA_DEF_DEF_  "AuthFreshnessCounterSyncAttempt" 2;
BA_DEF_DEF_  "VFrameFormat" "ExtendedCAN_FD";
BA_DEF_DEF_  "GenSigSendType" "NoSigSendType";
BA_DEF_DEF_  "GenSigInactiveValue" 0;
BA_DEF_DEF_  "WakeupSignal" "No";
BA_DEF_DEF_  "UsedOnPgmDBC" "Yes";
BA_DEF_DEF_  "GenSigStartValueInteger" 0;
BA_DEF_DEF_  "ContentDependant" "No";
BA_DEF_DEF_  "MetaData" "No";
BA_DEF_DEF_  "GenSigStartValue" 0;
BA_DEF_DEF_  "U_CX727_MY2021_Rx" "No";
BA_DEF_DEF_  "U_P702_MY2021_Rx" "No";
BA_DEF_DEF_  "U_T6_MCA_MY2020_Rx" "No";
BA_DEF_DEF_  "ECGUsedRxSignal" "No";
BA_DEF_DEF_  "U_CD542_MY2021_Rx" "No";
BA_DEF_DEF_  "U_U55X_MY2022_Rx" "No";
BA_DEF_DEF_  "U_CD764_MY2022_Rx" "No";
BA_DEF_DEF_  "U_CX727_MY2021_Tx" "No";
BA_DEF_DEF_  "U_P702_MY2021_Tx" "No";
BA_DEF_DEF_  "U_T6_MCA_MY2020_Tx" "No";
BA_DEF_DEF_  "ECGUsedTxSignal" "No";
BA_DEF_DEF_  "U_CD542_MY2021_Tx" "No";
BA_DEF_DEF_  "U_U55X_MY2022_Tx" "No";
BA_DEF_DEF_  "U_CD764_MY2022_Tx" "No";
BA_DEF_DEF_  "GenMsgILSupport" "Yes";
BA_DEF_DEF_  "DiagResponse" "No";
BA_DEF_DEF_  "DiagRequest" "No";
BA_DEF_DEF_  "TpTxIndex" 0;
BA_DEF_DEF_  "DiagState" "No";
BA_DEF_DEF_  "TpApplType" "";
BA_DEF_DEF_  "NmAsrMessage" "No";
BA_DEF_DEF_  "SCP_AuthInfoTxLength" 53;
BA_DEF_DEF_  "SCP_FreshnessValueTxLength" 11;
BA_DEF_DEF_  "SCP_FreshnessValueLength" 64;
BA_DEF_DEF_  "OvtpPushApplication" "FALSE";
BA_DEF_DEF_  "GenMsgSendType" "NoMsgSendType";
BA_DEF_DEF_  "GenMsgCycleTime" 0;
BA_DEF_DEF_  "GenMsgDelayTime" 20;
BA_DEF_DEF_  "GenMsgNrOfRepetition" 1;
BA_DEF_DEF_  "GenMsgStartDelayTime" 0;
BA_DEF_DEF_  "EventRateOfChange" 10000;
BA_DEF_DEF_  "FrameGatewayId" 0;
BA_DEF_DEF_  "NetworkInitialization" "Yes";
BA_DEF_DEF_  "FrameGatewayNetwork" "NONE";
BA_DEF_DEF_  "FrameRouting" "";
BA_ "GenMsgSendType" BO_ 516 0;
BA_ "GenMsgCycleTime" BO_ 516 10;
BA_ "GenMsgDelayTime" BO_ 516 0;
BA_ "VFrameFormat" BO_ 516 14;
BA_ "GenMsgSendType" BO_ 514 0;
BA_ "GenMsgCycleTime" BO_ 514 20;
BA_ "GenMsgDelayTime" BO_ 514 10;
BA_ "VFrameFormat" BO_ 514 14;
BA_ "GenMsgSendType" BO_ 512 0;
BA_ "GenMsgCycleTime" BO_ 512 20;
BA_ "GenMsgDelayTime" BO_ 512 10;
BA_ "VFrameFormat" BO_ 512 14;
BA_ "GenMsgSendType" BO_ 381 0;
BA_ "GenMsgCycleTime" BO_ 381 100;
BA_ "VFrameFormat" BO_ 381 14;
BA_ "GenMsgSendType" BO_ 380 0;
BA_ "GenMsgCycleTime" BO_ 380 100;
BA_ "VFrameFormat" BO_ 380 14;
BA_ "GenMsgSendType" BO_ 377 0;
BA_ "GenMsgCycleTime" BO_ 377 100;
BA_ "VFrameFormat" BO_ 377 14;
BA_ "GenMsgSendType" BO_ 376 0;
BA_ "GenMsgCycleTime" BO_ 376 100;
BA_ "VFrameFormat" BO_ 376 14;
BA_ "GenMsgSendType" BO_ 373 0;
BA_ "GenMsgCycleTime" BO_ 373 20;
BA_ "GenMsgDelayTime" BO_ 373 10;
BA_ "VFrameFormat" BO_ 373 14;
BA_ "GenMsgSendType" BO_ 359 0;
BA_ "GenMsgCycleTime" BO_ 359 10;
BA_ "GenMsgDelayTime" BO_ 359 0;
BA_ "VFrameFormat" BO_ 359 14;
BA_ "GenMsgSendType" BO_ 358 0;
BA_ "GenMsgCycleTime" BO_ 358 100;
BA_ "VFrameFormat" BO_ 358 14;
BA_ "GenMsgSendType" BO_ 357 0;
BA_ "GenMsgCycleTime" BO_ 357 20;
BA_ "GenMsgDelayTime" BO_ 357 10;
BA_ "VFrameFormat" BO_ 357 14;
BA_ "GenMsgSendType" BO_ 342 0;
BA_ "GenMsgCycleTime" BO_ 342 100;
BA_ "VFrameFormat" BO_ 342 14;
BA_ "GenMsgILSupport" BO_ 1520 0;
BA_ "NmAsrMessage" BO_ 1520 1;
BA_ "GenMsgSendType" BO_ 1520 0;
BA_ "GenMsgCycleTime" BO_ 1520 1000;
BA_ "NetworkInitialization" BO_ 1520 0;
BA_ "VFrameFormat" BO_ 1520 14;
BA_ "GenMsgSendType" BO_ 71 0;
BA_ "GenMsgCycleTime" BO_ 71 20;
BA_ "GenMsgDelayTime" BO_ 71 10;
BA_ "VFrameFormat" BO_ 71 14;
BA_ "GenMsgSendType" BO_ 1229 5;
BA_ "GenMsgCycleTime" BO_ 1229 1000;
BA_ "VFrameFormat" BO_ 1229 14;
BA_ "GenMsgSendType" BO_ 1238 5;
BA_ "GenMsgCycleTime" BO_ 1238 1000;
BA_ "VFrameFormat" BO_ 1238 14;
BA_ "TpTxIndex" BO_ 2610126880 462455000;
BA_ "GenMsgSendType" BO_ 2610126880 1;
BA_ "GenMsgDelayTime" BO_ 2610126880 0;
BA_ "NetworkInitialization" BO_ 2610126880 0;
BA_ "TpTxIndex" BO_ 2609938648 462455000;
BA_ "GenMsgSendType" BO_ 2609938648 1;
BA_ "GenMsgDelayTime" BO_ 2609938648 0;
BA_ "NetworkInitialization" BO_ 2609938648 0;
BA_ "TpTxIndex" BO_ 2610987224 463503576;
BA_ "GenMsgSendType" BO_ 2610987224 1;
BA_ "GenMsgDelayTime" BO_ 2610987224 0;
BA_ "NetworkInitialization" BO_ 2610987224 0;
BA_ "TpTxIndex" BO_ 2611175456 463503576;
BA_ "GenMsgSendType" BO_ 2611175456 1;
BA_ "GenMsgDelayTime" BO_ 2611175456 0;
BA_ "NetworkInitialization" BO_ 2611175456 0;
BA_ "TpTxIndex" BO_ 2612035800 464552152;
BA_ "OvtpPushApplication" BO_ 2612035800 1;
BA_ "GenMsgSendType" BO_ 2612035800 1;
BA_ "GenMsgDelayTime" BO_ 2612035800 0;
BA_ "NetworkInitialization" BO_ 2612035800 0;
BA_ "TpTxIndex" BO_ 2612224032 464552152;
BA_ "OvtpPushApplication" BO_ 2612224032 1;
BA_ "GenMsgSendType" BO_ 2612224032 1;
BA_ "GenMsgDelayTime" BO_ 2612224032 0;
BA_ "NetworkInitialization" BO_ 2612224032 0;
BA_ "FrameGatewayId" BO_ 895 895;
BA_ "FrameGatewayNetwork" BO_ 895 "HS4_CAN";
BA_ "FrameRouting" BO_ 895 "HS4_CAN,0x37F;";
BA_ "VFrameFormat" BO_ 895 14;
BA_ "FrameGatewayId" BO_ 1092 1092;
BA_ "FrameGatewayNetwork" BO_ 1092 "HS5_CAN";
BA_ "FrameRouting" BO_ 1092 "HS5_CAN,0x444;";
BA_ "VFrameFormat" BO_ 1092 14;
BA_ "GenMsgSendType" BO_ 1236 5;
BA_ "GenMsgCycleTime" BO_ 1236 1000;
BA_ "VFrameFormat" BO_ 1236 14;
BA_ "GenMsgSendType" BO_ 1235 5;
BA_ "GenMsgCycleTime" BO_ 1235 1000;
BA_ "VFrameFormat" BO_ 1235 14;
BA_ "GenMsgSendType" BO_ 1234 5;
BA_ "GenMsgCycleTime" BO_ 1234 200;
BA_ "VFrameFormat" BO_ 1234 14;
BA_ "GenMsgSendType" BO_ 1233 5;
BA_ "GenMsgCycleTime" BO_ 1233 200;
BA_ "VFrameFormat" BO_ 1233 14;
BA_ "GenMsgSendType" BO_ 1237 5;
BA_ "GenMsgCycleTime" BO_ 1237 1000;
BA_ "VFrameFormat" BO_ 1237 14;
BA_ "FrameGatewayId" BO_ 1149 1149;
BA_ "FrameGatewayNetwork" BO_ 1149 "HS5_CAN";
BA_ "FrameRouting" BO_ 1149 "HS5_CAN,0x47D;";
BA_ "VFrameFormat" BO_ 1149 14;
BA_ "GenMsgILSupport" BO_ 1436 0;
BA_ "NmAsrMessage" BO_ 1436 1;
BA_ "GenMsgSendType" BO_ 1436 0;
BA_ "GenMsgCycleTime" BO_ 1436 1000;
BA_ "NetworkInitialization" BO_ 1436 0;
BA_ "VFrameFormat" BO_ 1436 14;
BA_ "GenMsgSendType" BO_ 788 0;
BA_ "GenMsgCycleTime" BO_ 788 500;
BA_ "VFrameFormat" BO_ 788 14;
BA_ "GenMsgSendType" BO_ 824 5;
BA_ "GenMsgCycleTime" BO_ 824 1000;
BA_ "VFrameFormat" BO_ 824 14;
BA_ "FrameGatewayId" BO_ 811 811;
BA_ "FrameGatewayNetwork" BO_ 811 "HS3_CAN";
BA_ "FrameRouting" BO_ 811 "HS3_CAN,0x32B;";
BA_ "VFrameFormat" BO_ 811 14;
BA_ "GenMsgSendType" BO_ 942 5;
BA_ "GenMsgCycleTime" BO_ 942 200;
BA_ "VFrameFormat" BO_ 942 14;
BA_ "FrameGatewayId" BO_ 123 123;
BA_ "FrameGatewayNetwork" BO_ 123 "HS5_CAN";
BA_ "FrameRouting" BO_ 123 "HS5_CAN,0x7B;";
BA_ "VFrameFormat" BO_ 123 14;
BA_ "TpTxIndex" BO_ 2612052184 464568536;
BA_ "OvtpPushApplication" BO_ 2612052184 1;
BA_ "GenMsgSendType" BO_ 2612052184 1;
BA_ "GenMsgDelayTime" BO_ 2612052184 0;
BA_ "NetworkInitialization" BO_ 2612052184 0;
BA_ "TpTxIndex" BO_ 2612224187 464710872;
BA_ "OvtpPushApplication" BO_ 2612224187 1;
BA_ "GenMsgSendType" BO_ 2612224187 1;
BA_ "GenMsgDelayTime" BO_ 2612224187 0;
BA_ "NetworkInitialization" BO_ 2612224187 0;
BA_ "GenMsgSendType" BO_ 1239 5;
BA_ "GenMsgCycleTime" BO_ 1239 1000;
BA_ "VFrameFormat" BO_ 1239 14;
BA_ "FrameGatewayId" BO_ 949 949;
BA_ "FrameGatewayNetwork" BO_ 949 "HS1_CAN";
BA_ "FrameRouting" BO_ 949 "HS1_CAN,0x3B5;";
BA_ "VFrameFormat" BO_ 949 14;
BA_ "TpTxIndex" BO_ 2612074712 464591064;
BA_ "OvtpPushApplication" BO_ 2612074712 1;
BA_ "GenMsgSendType" BO_ 2612074712 1;
BA_ "GenMsgDelayTime" BO_ 2612074712 0;
BA_ "NetworkInitialization" BO_ 2612074712 0;
BA_ "TpTxIndex" BO_ 2612024536 464540888;
BA_ "OvtpPushApplication" BO_ 2612024536 1;
BA_ "GenMsgSendType" BO_ 2612024536 1;
BA_ "GenMsgDelayTime" BO_ 2612024536 0;
BA_ "NetworkInitialization" BO_ 2612024536 0;
BA_ "TpTxIndex" BO_ 2612036824 464553176;
BA_ "OvtpPushApplication" BO_ 2612036824 1;
BA_ "GenMsgSendType" BO_ 2612036824 1;
BA_ "GenMsgDelayTime" BO_ 2612036824 0;
BA_ "NetworkInitialization" BO_ 2612036824 0;
BA_ "TpTxIndex" BO_ 2612103384 464619736;
BA_ "OvtpPushApplication" BO_ 2612103384 1;
BA_ "GenMsgSendType" BO_ 2612103384 1;
BA_ "GenMsgDelayTime" BO_ 2612103384 0;
BA_ "NetworkInitialization" BO_ 2612103384 0;
BA_ "GenMsgSendType" BO_ 639 5;
BA_ "GenMsgCycleTime" BO_ 639 1000;
BA_ "VFrameFormat" BO_ 639 14;
BA_ "GenMsgSendType" BO_ 530 5;
BA_ "GenMsgCycleTime" BO_ 530 1000;
BA_ "VFrameFormat" BO_ 530 14;
BA_ "GenMsgSendType" BO_ 550 5;
BA_ "GenMsgCycleTime" BO_ 550 1000;
BA_ "VFrameFormat" BO_ 550 14;
BA_ "TpTxIndex" BO_ 2612019416 464535768;
BA_ "OvtpPushApplication" BO_ 2612019416 1;
BA_ "GenMsgSendType" BO_ 2612019416 1;
BA_ "GenMsgDelayTime" BO_ 2612019416 0;
BA_ "NetworkInitialization" BO_ 2612019416 0;
BA_ "GenMsgSendType" BO_ 885 0;
BA_ "GenMsgCycleTime" BO_ 885 200;
BA_ "VFrameFormat" BO_ 885 14;
BA_ "TpTxIndex" BO_ 2612104408 464620760;
BA_ "OvtpPushApplication" BO_ 2612104408 1;
BA_ "GenMsgSendType" BO_ 2612104408 1;
BA_ "GenMsgDelayTime" BO_ 2612104408 0;
BA_ "NetworkInitialization" BO_ 2612104408 0;
BA_ "TpTxIndex" BO_ 2612020440 464536792;
BA_ "OvtpPushApplication" BO_ 2612020440 1;
BA_ "GenMsgSendType" BO_ 2612020440 1;
BA_ "GenMsgDelayTime" BO_ 2612020440 0;
BA_ "NetworkInitialization" BO_ 2612020440 0;
BA_ "FrameGatewayId" BO_ 739 739;
BA_ "FrameGatewayNetwork" BO_ 739 "HS3_CAN";
BA_ "FrameRouting" BO_ 739 "HS3_CAN,0x2E3;";
BA_ "VFrameFormat" BO_ 739 14;
BA_ "GenMsgSendType" BO_ 1160 5;
BA_ "GenMsgCycleTime" BO_ 1160 1000;
BA_ "VFrameFormat" BO_ 1160 14;
BA_ "GenMsgILSupport" BO_ 1825 0;
BA_ "DiagRequest" BO_ 1825 1;
BA_ "GenMsgSendType" BO_ 1825 1;
BA_ "GenMsgDelayTime" BO_ 1825 0;
BA_ "NetworkInitialization" BO_ 1825 0;
BA_ "VFrameFormat" BO_ 1825 14;
BA_ "FrameGatewayId" BO_ 945 945;
BA_ "FrameGatewayNetwork" BO_ 945 "HS1_CAN";
BA_ "FrameRouting" BO_ 945 "HS1_CAN,0x3B1;";
BA_ "VFrameFormat" BO_ 945 14;
BA_ "TpTxIndex" BO_ 2612073688 464590040;
BA_ "OvtpPushApplication" BO_ 2612073688 1;
BA_ "GenMsgSendType" BO_ 2612073688 1;
BA_ "GenMsgDelayTime" BO_ 2612073688 0;
BA_ "NetworkInitialization" BO_ 2612073688 0;
BA_ "GenMsgILSupport" BO_ 1833 0;
BA_ "DiagResponse" BO_ 1833 1;
BA_ "GenMsgSendType" BO_ 1833 1;
BA_ "GenMsgDelayTime" BO_ 1833 0;
BA_ "NetworkInitialization" BO_ 1833 0;
BA_ "VFrameFormat" BO_ 1833 14;
BA_ "FrameGatewayId" BO_ 395 395;
BA_ "FrameGatewayNetwork" BO_ 395 "HS3_CAN";
BA_ "FrameRouting" BO_ 395 "HS3_CAN,0x18B;";
BA_ "VFrameFormat" BO_ 395 14;
BA_ "FrameGatewayId" BO_ 542 542;
BA_ "FrameGatewayNetwork" BO_ 542 "HS4_CAN";
BA_ "FrameRouting" BO_ 542 "HS4_CAN,0x21E;";
BA_ "VFrameFormat" BO_ 542 14;
BA_ "GenMsgSendType" BO_ 515 5;
BA_ "GenMsgCycleTime" BO_ 515 100;
BA_ "VFrameFormat" BO_ 515 14;
BA_ "GenMsgSendType" BO_ 982 0;
BA_ "GenMsgCycleTime" BO_ 982 50;
BA_ "VFrameFormat" BO_ 982 14;
BA_ "GenMsgSendType" BO_ 1104 0;
BA_ "GenMsgCycleTime" BO_ 1104 200;
BA_ "VFrameFormat" BO_ 1104 14;
BA_ "TpTxIndex" BO_ 2610021592 462537944;
BA_ "GenMsgSendType" BO_ 2610021592 1;
BA_ "GenMsgDelayTime" BO_ 2610021592 0;
BA_ "NetworkInitialization" BO_ 2610021592 0;
BA_ "TpTxIndex" BO_ 2610975960 463492312;
BA_ "GenMsgSendType" BO_ 2610975960 1;
BA_ "GenMsgDelayTime" BO_ 2610975960 0;
BA_ "NetworkInitialization" BO_ 2610975960 0;
BA_ "TpTxIndex" BO_ 2611175445 463492312;
BA_ "GenMsgSendType" BO_ 2611175445 1;
BA_ "GenMsgDelayTime" BO_ 2611175445 0;
BA_ "NetworkInitialization" BO_ 2611175445 0;
BA_ "TpTxIndex" BO_ 2612224021 464540888;
BA_ "OvtpPushApplication" BO_ 2612224021 1;
BA_ "GenMsgSendType" BO_ 2612224021 1;
BA_ "GenMsgDelayTime" BO_ 2612224021 0;
BA_ "NetworkInitialization" BO_ 2612224021 0;
BA_ "TpTxIndex" BO_ 2611025112 463541464;
BA_ "GenMsgSendType" BO_ 2611025112 1;
BA_ "GenMsgDelayTime" BO_ 2611025112 0;
BA_ "NetworkInitialization" BO_ 2611025112 0;
BA_ "TpTxIndex" BO_ 2611175493 463541464;
BA_ "GenMsgSendType" BO_ 2611175493 1;
BA_ "GenMsgDelayTime" BO_ 2611175493 0;
BA_ "NetworkInitialization" BO_ 2611175493 0;
BA_ "TpTxIndex" BO_ 2612224069 464590040;
BA_ "OvtpPushApplication" BO_ 2612224069 1;
BA_ "GenMsgSendType" BO_ 2612224069 1;
BA_ "GenMsgDelayTime" BO_ 2612224069 0;
BA_ "NetworkInitialization" BO_ 2612224069 0;
BA_ "GenMsgILSupport" BO_ 1787 0;
BA_ "DiagResponse" BO_ 1787 1;
BA_ "GenMsgSendType" BO_ 1787 1;
BA_ "GenMsgDelayTime" BO_ 1787 0;
BA_ "NetworkInitialization" BO_ 1787 0;
BA_ "VFrameFormat" BO_ 1787 14;
BA_ "GenMsgILSupport" BO_ 1779 0;
BA_ "DiagRequest" BO_ 1779 1;
BA_ "GenMsgSendType" BO_ 1779 1;
BA_ "GenMsgDelayTime" BO_ 1779 0;
BA_ "NetworkInitialization" BO_ 1779 0;
BA_ "VFrameFormat" BO_ 1779 14;
BA_ "GenMsgILSupport" BO_ 1786 0;
BA_ "DiagResponse" BO_ 1786 1;
BA_ "GenMsgSendType" BO_ 1786 1;
BA_ "GenMsgDelayTime" BO_ 1786 0;
BA_ "NetworkInitialization" BO_ 1786 0;
BA_ "VFrameFormat" BO_ 1786 14;
BA_ "ContentDependant" SG_ 516 EngAout3_N_Actl 1;
BA_ "U_CX727_MY2021_Rx" SG_ 516 EngAout3_N_Actl 1;
BA_ "U_P702_MY2021_Rx" SG_ 516 EngAout3_N_Actl 1;
BA_ "U_CD542_MY2021_Rx" SG_ 516 EngAout3_N_Actl 1;
BA_ "U_P702_MY2021_Tx" SG_ 516 EngAout3_N_Actl 1;
BA_ "U_CD542_MY2021_Tx" SG_ 516 EngAout3_N_Actl 1;
BA_ "U_CX727_MY2021_Rx" SG_ 516 ApedPos_Pc_ActlArb 1;
BA_ "U_P702_MY2021_Rx" SG_ 516 ApedPos_Pc_ActlArb 1;
BA_ "U_T6_MCA_MY2020_Rx" SG_ 516 ApedPos_Pc_ActlArb 1;
BA_ "ECGUsedRxSignal" SG_ 516 ApedPos_Pc_ActlArb 1;
BA_ "U_CD542_MY2021_Rx" SG_ 516 ApedPos_Pc_ActlArb 1;
BA_ "U_U55X_MY2022_Rx" SG_ 516 ApedPos_Pc_ActlArb 1;
BA_ "U_CD764_MY2022_Rx" SG_ 516 ApedPos_Pc_ActlArb 1;
BA_ "U_CX727_MY2021_Tx" SG_ 516 ApedPos_Pc_ActlArb 1;
BA_ "U_P702_MY2021_Tx" SG_ 516 ApedPos_Pc_ActlArb 1;
BA_ "U_T6_MCA_MY2020_Tx" SG_ 516 ApedPos_Pc_ActlArb 1;
BA_ "U_CD542_MY2021_Tx" SG_ 516 ApedPos_Pc_ActlArb 1;
BA_ "U_U55X_MY2022_Tx" SG_ 516 ApedPos_Pc_ActlArb 1;
BA_ "U_CD764_MY2022_Tx" SG_ 516 ApedPos_Pc_ActlArb 1;
BA_ "GenSigStartValueInteger" SG_ 516 ApedPosPcActl_D_Qf 1;
BA_ "MetaData" SG_ 516 ApedPosPcActl_D_Qf 1;
BA_ "GenSigStartValue" SG_ 516 ApedPosPcActl_D_Qf 1;
BA_ "U_CX727_MY2021_Rx" SG_ 516 ApedPosPcActl_D_Qf 1;
BA_ "U_P702_MY2021_Rx" SG_ 516 ApedPosPcActl_D_Qf 1;
BA_ "U_T6_MCA_MY2020_Rx" SG_ 516 ApedPosPcActl_D_Qf 1;
BA_ "U_CD542_MY2021_Rx" SG_ 516 ApedPosPcActl_D_Qf 1;
BA_ "U_U55X_MY2022_Rx" SG_ 516 ApedPosPcActl_D_Qf 1;
BA_ "U_CD764_MY2022_Rx" SG_ 516 ApedPosPcActl_D_Qf 1;
BA_ "U_CX727_MY2021_Tx" SG_ 516 ApedPosPcActl_D_Qf 1;
BA_ "U_P702_MY2021_Tx" SG_ 516 ApedPosPcActl_D_Qf 1;
BA_ "U_T6_MCA_MY2020_Tx" SG_ 516 ApedPosPcActl_D_Qf 1;
BA_ "U_CD542_MY2021_Tx" SG_ 516 ApedPosPcActl_D_Qf 1;
BA_ "U_U55X_MY2022_Tx" SG_ 516 ApedPosPcActl_D_Qf 1;
BA_ "U_CD764_MY2022_Tx" SG_ 516 ApedPosPcActl_D_Qf 1;
BA_ "U_CX727_MY2021_Rx" SG_ 516 EngAout_N_Actl 1;
BA_ "U_P702_MY2021_Rx" SG_ 516 EngAout_N_Actl 1;
BA_ "U_T6_MCA_MY2020_Rx" SG_ 516 EngAout_N_Actl 1;
BA_ "ECGUsedRxSignal" SG_ 516 EngAout_N_Actl 1;
BA_ "U_CD542_MY2021_Rx" SG_ 516 EngAout_N_Actl 1;
BA_ "U_U55X_MY2022_Rx" SG_ 516 EngAout_N_Actl 1;
BA_ "U_CD764_MY2022_Rx" SG_ 516 EngAout_N_Actl 1;
BA_ "U_CX727_MY2021_Tx" SG_ 516 EngAout_N_Actl 1;
BA_ "U_P702_MY2021_Tx" SG_ 516 EngAout_N_Actl 1;
BA_ "U_T6_MCA_MY2020_Tx" SG_ 516 EngAout_N_Actl 1;
BA_ "U_CD542_MY2021_Tx" SG_ 516 EngAout_N_Actl 1;
BA_ "U_U55X_MY2022_Tx" SG_ 516 EngAout_N_Actl 1;
BA_ "U_CD764_MY2022_Tx" SG_ 516 EngAout_N_Actl 1;
BA_ "ContentDependant" SG_ 516 ApedPosPcActl_No_Cnt 1;
BA_ "MetaData" SG_ 516 ApedPosPcActl_No_Cnt 1;
BA_ "U_CX727_MY2021_Rx" SG_ 516 ApedPosPcActl_No_Cnt 1;
BA_ "U_P702_MY2021_Rx" SG_ 516 ApedPosPcActl_No_Cnt 1;
BA_ "U_CD542_MY2021_Rx" SG_ 516 ApedPosPcActl_No_Cnt 1;
BA_ "U_U55X_MY2022_Rx" SG_ 516 ApedPosPcActl_No_Cnt 1;
BA_ "U_CD764_MY2022_Rx" SG_ 516 ApedPosPcActl_No_Cnt 1;
BA_ "U_CX727_MY2021_Tx" SG_ 516 ApedPosPcActl_No_Cnt 1;
BA_ "U_P702_MY2021_Tx" SG_ 516 ApedPosPcActl_No_Cnt 1;
BA_ "U_T6_MCA_MY2020_Tx" SG_ 516 ApedPosPcActl_No_Cnt 1;
BA_ "U_CD542_MY2021_Tx" SG_ 516 ApedPosPcActl_No_Cnt 1;
BA_ "ContentDependant" SG_ 516 ApedPosPcActl_No_Cs 1;
BA_ "MetaData" SG_ 516 ApedPosPcActl_No_Cs 1;
BA_ "U_CX727_MY2021_Rx" SG_ 516 ApedPosPcActl_No_Cs 1;
BA_ "U_P702_MY2021_Rx" SG_ 516 ApedPosPcActl_No_Cs 1;
BA_ "U_CD542_MY2021_Rx" SG_ 516 ApedPosPcActl_No_Cs 1;
BA_ "U_U55X_MY2022_Rx" SG_ 516 ApedPosPcActl_No_Cs 1;
BA_ "U_CD764_MY2022_Rx" SG_ 516 ApedPosPcActl_No_Cs 1;
BA_ "U_CX727_MY2021_Tx" SG_ 516 ApedPosPcActl_No_Cs 1;
BA_ "U_P702_MY2021_Tx" SG_ 516 ApedPosPcActl_No_Cs 1;
BA_ "U_T6_MCA_MY2020_Tx" SG_ 516 ApedPosPcActl_No_Cs 1;
BA_ "U_CD542_MY2021_Tx" SG_ 516 ApedPosPcActl_No_Cs 1;
BA_ "U_P702_MY2021_Rx" SG_ 516 ApedPos_PcRate_ActlArb 1;
BA_ "U_T6_MCA_MY2020_Rx" SG_ 516 ApedPos_PcRate_ActlArb 1;
BA_ "U_CX727_MY2021_Tx" SG_ 516 ApedPos_PcRate_ActlArb 1;
BA_ "U_P702_MY2021_Tx" SG_ 516 ApedPos_PcRate_ActlArb 1;
BA_ "U_T6_MCA_MY2020_Tx" SG_ 516 ApedPos_PcRate_ActlArb 1;
BA_ "U_CD542_MY2021_Tx" SG_ 516 ApedPos_PcRate_ActlArb 1;
BA_ "U_U55X_MY2022_Tx" SG_ 516 ApedPos_PcRate_ActlArb 1;
BA_ "U_CD764_MY2022_Tx" SG_ 516 ApedPos_PcRate_ActlArb 1;
BA_ "U_CX727_MY2021_Tx" SG_ 514 StrtrMtrDlyStrt_B_Stat 1;
BA_ "U_P702_MY2021_Tx" SG_ 514 StrtrMtrDlyStrt_B_Stat 1;
BA_ "U_T6_MCA_MY2020_Tx" SG_ 514 StrtrMtrDlyStrt_B_Stat 1;
BA_ "U_CD542_MY2021_Tx" SG_ 514 StrtrMtrDlyStrt_B_Stat 1;
BA_ "U_U55X_MY2022_Tx" SG_ 514 StrtrMtrDlyStrt_B_Stat 1;
BA_ "U_CD764_MY2022_Tx" SG_ 514 StrtrMtrDlyStrt_B_Stat 1;
BA_ "U_CX727_MY2021_Tx" SG_ 514 StrtrMtrCtlMsgTxt_D_Rq 1;
BA_ "U_P702_MY2021_Tx" SG_ 514 StrtrMtrCtlMsgTxt_D_Rq 1;
BA_ "U_T6_MCA_MY2020_Tx" SG_ 514 StrtrMtrCtlMsgTxt_D_Rq 1;
BA_ "U_CD542_MY2021_Tx" SG_ 514 StrtrMtrCtlMsgTxt_D_Rq 1;
BA_ "U_U55X_MY2022_Tx" SG_ 514 StrtrMtrCtlMsgTxt_D_Rq 1;
BA_ "U_CD764_MY2022_Tx" SG_ 514 StrtrMtrCtlMsgTxt_D_Rq 1;
BA_ "MetaData" SG_ 514 VehVActlEng_No_Cs 1;
BA_ "U_CX727_MY2021_Rx" SG_ 514 VehVActlEng_No_Cs 1;
BA_ "U_P702_MY2021_Rx" SG_ 514 VehVActlEng_No_Cs 1;
BA_ "U_T6_MCA_MY2020_Rx" SG_ 514 VehVActlEng_No_Cs 1;
BA_ "U_CD542_MY2021_Rx" SG_ 514 VehVActlEng_No_Cs 1;
BA_ "U_U55X_MY2022_Rx" SG_ 514 VehVActlEng_No_Cs 1;
BA_ "U_CD764_MY2022_Rx" SG_ 514 VehVActlEng_No_Cs 1;
BA_ "U_CX727_MY2021_Tx" SG_ 514 VehVActlEng_No_Cs 1;
BA_ "U_P702_MY2021_Tx" SG_ 514 VehVActlEng_No_Cs 1;
BA_ "U_T6_MCA_MY2020_Tx" SG_ 514 VehVActlEng_No_Cs 1;
BA_ "U_CD542_MY2021_Tx" SG_ 514 VehVActlEng_No_Cs 1;
BA_ "U_U55X_MY2022_Tx" SG_ 514 VehVActlEng_No_Cs 1;
BA_ "U_CD764_MY2022_Tx" SG_ 514 VehVActlEng_No_Cs 1;
BA_ "MetaData" SG_ 514 VehVActlEng_No_Cnt 1;
BA_ "U_CX727_MY2021_Rx" SG_ 514 VehVActlEng_No_Cnt 1;
BA_ "U_P702_MY2021_Rx" SG_ 514 VehVActlEng_No_Cnt 1;
BA_ "U_T6_MCA_MY2020_Rx" SG_ 514 VehVActlEng_No_Cnt 1;
BA_ "U_CD542_MY2021_Rx" SG_ 514 VehVActlEng_No_Cnt 1;
BA_ "U_U55X_MY2022_Rx" SG_ 514 VehVActlEng_No_Cnt 1;
BA_ "U_CD764_MY2022_Rx" SG_ 514 VehVActlEng_No_Cnt 1;
BA_ "U_CX727_MY2021_Tx" SG_ 514 VehVActlEng_No_Cnt 1;
BA_ "U_P702_MY2021_Tx" SG_ 514 VehVActlEng_No_Cnt 1;
BA_ "U_T6_MCA_MY2020_Tx" SG_ 514 VehVActlEng_No_Cnt 1;
BA_ "U_CD542_MY2021_Tx" SG_ 514 VehVActlEng_No_Cnt 1;
BA_ "U_U55X_MY2022_Tx" SG_ 514 VehVActlEng_No_Cnt 1;
BA_ "U_CD764_MY2022_Tx" SG_ 514 VehVActlEng_No_Cnt 1;
BA_ "U_CX727_MY2021_Rx" SG_ 514 Veh_V_RqCcSet 1;
BA_ "U_P702_MY2021_Rx" SG_ 514 Veh_V_RqCcSet 1;
BA_ "U_T6_MCA_MY2020_Rx" SG_ 514 Veh_V_RqCcSet 1;
BA_ "U_CD542_MY2021_Rx" SG_ 514 Veh_V_RqCcSet 1;
BA_ "U_U55X_MY2022_Rx" SG_ 514 Veh_V_RqCcSet 1;
BA_ "U_CD764_MY2022_Rx" SG_ 514 Veh_V_RqCcSet 1;
BA_ "U_CX727_MY2021_Tx" SG_ 514 Veh_V_RqCcSet 1;
BA_ "U_P702_MY2021_Tx" SG_ 514 Veh_V_RqCcSet 1;
BA_ "U_T6_MCA_MY2020_Tx" SG_ 514 Veh_V_RqCcSet 1;
BA_ "U_CD542_MY2021_Tx" SG_ 514 Veh_V_RqCcSet 1;
BA_ "U_U55X_MY2022_Tx" SG_ 514 Veh_V_RqCcSet 1;
BA_ "U_CD764_MY2022_Tx" SG_ 514 Veh_V_RqCcSet 1;
BA_ "MetaData" SG_ 514 VehVActlEng_D_Qf 1;
BA_ "U_CX727_MY2021_Rx" SG_ 514 VehVActlEng_D_Qf 1;
BA_ "U_P702_MY2021_Rx" SG_ 514 VehVActlEng_D_Qf 1;
BA_ "U_T6_MCA_MY2020_Rx" SG_ 514 VehVActlEng_D_Qf 1;
BA_ "U_CD542_MY2021_Rx" SG_ 514 VehVActlEng_D_Qf 1;
BA_ "U_U55X_MY2022_Rx" SG_ 514 VehVActlEng_D_Qf 1;
BA_ "U_CD764_MY2022_Rx" SG_ 514 VehVActlEng_D_Qf 1;
BA_ "U_CX727_MY2021_Tx" SG_ 514 VehVActlEng_D_Qf 1;
BA_ "U_P702_MY2021_Tx" SG_ 514 VehVActlEng_D_Qf 1;
BA_ "U_T6_MCA_MY2020_Tx" SG_ 514 VehVActlEng_D_Qf 1;
BA_ "U_CD542_MY2021_Tx" SG_ 514 VehVActlEng_D_Qf 1;
BA_ "U_U55X_MY2022_Tx" SG_ 514 VehVActlEng_D_Qf 1;
BA_ "U_CD764_MY2022_Tx" SG_ 514 VehVActlEng_D_Qf 1;
BA_ "U_CX727_MY2021_Rx" SG_ 514 Veh_V_ActlEng 1;
BA_ "U_P702_MY2021_Rx" SG_ 514 Veh_V_ActlEng 1;
BA_ "U_T6_MCA_MY2020_Rx" SG_ 514 Veh_V_ActlEng 1;
BA_ "ECGUsedRxSignal" SG_ 514 Veh_V_ActlEng 1;
BA_ "U_CD542_MY2021_Rx" SG_ 514 Veh_V_ActlEng 1;
BA_ "U_U55X_MY2022_Rx" SG_ 514 Veh_V_ActlEng 1;
BA_ "U_CD764_MY2022_Rx" SG_ 514 Veh_V_ActlEng 1;
BA_ "U_CX727_MY2021_Tx" SG_ 514 Veh_V_ActlEng 1;
BA_ "U_P702_MY2021_Tx" SG_ 514 Veh_V_ActlEng 1;
BA_ "U_T6_MCA_MY2020_Tx" SG_ 514 Veh_V_ActlEng 1;
BA_ "U_CD542_MY2021_Tx" SG_ 514 Veh_V_ActlEng 1;
BA_ "U_U55X_MY2022_Tx" SG_ 514 Veh_V_ActlEng 1;
BA_ "U_CD764_MY2022_Tx" SG_ 514 Veh_V_ActlEng 1;
BA_ "ContentDependant" SG_ 514 EngAout_Tq_VacLimSpcN 1;
BA_ "U_CX727_MY2021_Rx" SG_ 514 EngAout_Tq_VacLimSpcN 1;
BA_ "U_CD542_MY2021_Rx" SG_ 514 EngAout_Tq_VacLimSpcN 1;
BA_ "U_CX727_MY2021_Tx" SG_ 514 EngAout_Tq_VacLimSpcN 1;
BA_ "U_CD542_MY2021_Tx" SG_ 514 EngAout_Tq_VacLimSpcN 1;
BA_ "ContentDependant" SG_ 514 EngCylSync_No_Ctr 1;
BA_ "U_CX727_MY2021_Rx" SG_ 514 EngCylSync_No_Ctr 1;
BA_ "U_CD542_MY2021_Rx" SG_ 514 EngCylSync_No_Ctr 1;
BA_ "U_CX727_MY2021_Tx" SG_ 514 EngCylSync_No_Ctr 1;
BA_ "U_CD542_MY2021_Tx" SG_ 514 EngCylSync_No_Ctr 1;
BA_ "GenSigStartValueInteger" SG_ 514 GearRvrse_D_Actl 7;
BA_ "GenSigStartValue" SG_ 514 GearRvrse_D_Actl 7;
BA_ "U_CX727_MY2021_Rx" SG_ 514 GearRvrse_D_Actl 1;
BA_ "U_P702_MY2021_Rx" SG_ 514 GearRvrse_D_Actl 1;
BA_ "U_T6_MCA_MY2020_Rx" SG_ 514 GearRvrse_D_Actl 1;
BA_ "ECGUsedRxSignal" SG_ 514 GearRvrse_D_Actl 1;
BA_ "U_CD542_MY2021_Rx" SG_ 514 GearRvrse_D_Actl 1;
BA_ "U_U55X_MY2022_Rx" SG_ 514 GearRvrse_D_Actl 1;
BA_ "U_CD764_MY2022_Rx" SG_ 514 GearRvrse_D_Actl 1;
BA_ "U_CX727_MY2021_Tx" SG_ 514 GearRvrse_D_Actl 1;
BA_ "U_P702_MY2021_Tx" SG_ 514 GearRvrse_D_Actl 1;
BA_ "U_T6_MCA_MY2020_Tx" SG_ 514 GearRvrse_D_Actl 1;
BA_ "U_CD542_MY2021_Tx" SG_ 514 GearRvrse_D_Actl 1;
BA_ "U_U55X_MY2022_Tx" SG_ 514 GearRvrse_D_Actl 1;
BA_ "U_CD764_MY2022_Tx" SG_ 514 GearRvrse_D_Actl 1;
BA_ "U_P702_MY2021_Tx" SG_ 514 StrtrMtrCtlMsgTxt_D2_Rq 1;
BA_ "U_T6_MCA_MY2020_Tx" SG_ 514 StrtrMtrCtlMsgTxt_D2_Rq 1;
BA_ "U_CD542_MY2021_Tx" SG_ 514 StrtrMtrCtlMsgTxt_D2_Rq 1;
BA_ "U_U55X_MY2022_Tx" SG_ 514 StrtrMtrCtlMsgTxt_D2_Rq 1;
BA_ "U_CD764_MY2022_Tx" SG_ 514 StrtrMtrCtlMsgTxt_D2_Rq 1;
BA_ "ContentDependant" SG_ 512 PrplWhlTotTqRq_No_Cs 1;
BA_ "MetaData" SG_ 512 PrplWhlTotTqRq_No_Cs 1;
BA_ "U_CX727_MY2021_Rx" SG_ 512 PrplWhlTotTqRq_No_Cs 1;
BA_ "U_P702_MY2021_Rx" SG_ 512 PrplWhlTotTqRq_No_Cs 1;
BA_ "U_CD542_MY2021_Rx" SG_ 512 PrplWhlTotTqRq_No_Cs 1;
BA_ "U_U55X_MY2022_Rx" SG_ 512 PrplWhlTotTqRq_No_Cs 1;
BA_ "U_CD764_MY2022_Rx" SG_ 512 PrplWhlTotTqRq_No_Cs 1;
BA_ "U_CX727_MY2021_Tx" SG_ 512 PrplWhlTotTqRq_No_Cs 1;
BA_ "U_P702_MY2021_Tx" SG_ 512 PrplWhlTotTqRq_No_Cs 1;
BA_ "U_CD542_MY2021_Tx" SG_ 512 PrplWhlTotTqRq_No_Cs 1;
BA_ "ContentDependant" SG_ 512 PrplWhlTotTqRq_No_Cnt 1;
BA_ "MetaData" SG_ 512 PrplWhlTotTqRq_No_Cnt 1;
BA_ "U_CX727_MY2021_Rx" SG_ 512 PrplWhlTotTqRq_No_Cnt 1;
BA_ "U_P702_MY2021_Rx" SG_ 512 PrplWhlTotTqRq_No_Cnt 1;
BA_ "U_CD542_MY2021_Rx" SG_ 512 PrplWhlTotTqRq_No_Cnt 1;
BA_ "U_U55X_MY2022_Rx" SG_ 512 PrplWhlTotTqRq_No_Cnt 1;
BA_ "U_CD764_MY2022_Rx" SG_ 512 PrplWhlTotTqRq_No_Cnt 1;
BA_ "U_CX727_MY2021_Tx" SG_ 512 PrplWhlTotTqRq_No_Cnt 1;
BA_ "U_P702_MY2021_Tx" SG_ 512 PrplWhlTotTqRq_No_Cnt 1;
BA_ "U_CD542_MY2021_Tx" SG_ 512 PrplWhlTotTqRq_No_Cnt 1;
BA_ "ContentDependant" SG_ 512 EngAout_Tq_MxMxN 1;
BA_ "U_CX727_MY2021_Rx" SG_ 512 EngAout_Tq_MxMxN 1;
BA_ "U_CD542_MY2021_Rx" SG_ 512 EngAout_Tq_MxMxN 1;
BA_ "U_CX727_MY2021_Tx" SG_ 512 EngAout_Tq_MxMxN 1;
BA_ "U_CD542_MY2021_Tx" SG_ 512 EngAout_Tq_MxMxN 1;
BA_ "U_CX727_MY2021_Rx" SG_ 512 PrplWhlTot_Tq_Rq 1;
BA_ "U_P702_MY2021_Rx" SG_ 512 PrplWhlTot_Tq_Rq 1;
BA_ "U_T6_MCA_MY2020_Rx" SG_ 512 PrplWhlTot_Tq_Rq 1;
BA_ "U_CD542_MY2021_Rx" SG_ 512 PrplWhlTot_Tq_Rq 1;
BA_ "U_U55X_MY2022_Rx" SG_ 512 PrplWhlTot_Tq_Rq 1;
BA_ "U_CD764_MY2022_Rx" SG_ 512 PrplWhlTot_Tq_Rq 1;
BA_ "U_CX727_MY2021_Tx" SG_ 512 PrplWhlTot_Tq_Rq 1;
BA_ "U_P702_MY2021_Tx" SG_ 512 PrplWhlTot_Tq_Rq 1;
BA_ "U_T6_MCA_MY2020_Tx" SG_ 512 PrplWhlTot_Tq_Rq 1;
BA_ "U_CD542_MY2021_Tx" SG_ 512 PrplWhlTot_Tq_Rq 1;
BA_ "U_U55X_MY2022_Tx" SG_ 512 PrplWhlTot_Tq_Rq 1;
BA_ "U_CD764_MY2022_Tx" SG_ 512 PrplWhlTot_Tq_Rq 1;
BA_ "U_CX727_MY2021_Rx" SG_ 512 PrplWhlTot_Tq_LimMn 1;
BA_ "U_P702_MY2021_Rx" SG_ 512 PrplWhlTot_Tq_LimMn 1;
BA_ "U_T6_MCA_MY2020_Rx" SG_ 512 PrplWhlTot_Tq_LimMn 1;
BA_ "U_CD542_MY2021_Rx" SG_ 512 PrplWhlTot_Tq_LimMn 1;
BA_ "U_U55X_MY2022_Rx" SG_ 512 PrplWhlTot_Tq_LimMn 1;
BA_ "U_CD764_MY2022_Rx" SG_ 512 PrplWhlTot_Tq_LimMn 1;
BA_ "U_CX727_MY2021_Tx" SG_ 512 PrplWhlTot_Tq_LimMn 1;
BA_ "U_P702_MY2021_Tx" SG_ 512 PrplWhlTot_Tq_LimMn 1;
BA_ "U_T6_MCA_MY2020_Tx" SG_ 512 PrplWhlTot_Tq_LimMn 1;
BA_ "U_CD542_MY2021_Tx" SG_ 512 PrplWhlTot_Tq_LimMn 1;
BA_ "U_U55X_MY2022_Tx" SG_ 512 PrplWhlTot_Tq_LimMn 1;
BA_ "U_CD764_MY2022_Tx" SG_ 512 PrplWhlTot_Tq_LimMn 1;
BA_ "U_P702_MY2021_Tx" SG_ 381 EngOilLife_T_Actl 1;
BA_ "U_T6_MCA_MY2020_Tx" SG_ 381 EngOilLife_T_Actl 1;
BA_ "U_T6_MCA_MY2020_Rx" SG_ 381 EngOilSrvcMsgTxt_D_Rq 1;
BA_ "ECGUsedRxSignal" SG_ 381 EngOilSrvcMsgTxt_D_Rq 1;
BA_ "U_CD542_MY2021_Rx" SG_ 381 EngOilSrvcMsgTxt_D_Rq 1;
BA_ "U_U55X_MY2022_Rx" SG_ 381 EngOilSrvcMsgTxt_D_Rq 1;
BA_ "U_CD764_MY2022_Rx" SG_ 381 EngOilSrvcMsgTxt_D_Rq 1;
BA_ "U_P702_MY2021_Tx" SG_ 381 EngOilSrvcMsgTxt_D_Rq 1;
BA_ "U_T6_MCA_MY2020_Tx" SG_ 381 EngOilSrvcMsgTxt_D_Rq 1;
BA_ "U_P702_MY2021_Tx" SG_ 381 DistToNextOilChange 1;
BA_ "U_T6_MCA_MY2020_Tx" SG_ 381 DistToNextOilChange 1;
BA_ "U_P702_MY2021_Tx" SG_ 381 RunDryPrevent_B_Stat 1;
BA_ "U_T6_MCA_MY2020_Tx" SG_ 381 RunDryPrevent_B_Stat 1;
BA_ "U_T6_MCA_MY2020_Rx" SG_ 381 WaterInFuel 1;
BA_ "ECGUsedRxSignal" SG_ 381 WaterInFuel 1;
BA_ "U_CD542_MY2021_Rx" SG_ 381 WaterInFuel 1;
BA_ "U_U55X_MY2022_Rx" SG_ 381 WaterInFuel 1;
BA_ "U_CD764_MY2022_Rx" SG_ 381 WaterInFuel 1;
BA_ "U_P702_MY2021_Tx" SG_ 381 WaterInFuel 1;
BA_ "U_T6_MCA_MY2020_Tx" SG_ 381 WaterInFuel 1;
BA_ "U_P702_MY2021_Tx" SG_ 381 GlowIndication 1;
BA_ "U_T6_MCA_MY2020_Tx" SG_ 381 GlowIndication 1;
BA_ "U_CX727_MY2021_Rx" SG_ 380 FuelMaintMde_D_Rq 1;
BA_ "U_CD542_MY2021_Rx" SG_ 380 FuelMaintMde_D_Rq 1;
BA_ "U_CX727_MY2021_Tx" SG_ 380 FuelMaintMde_D_Rq 1;
BA_ "U_CD542_MY2021_Tx" SG_ 380 FuelMaintMde_D_Rq 1;
BA_ "GenSigStartValueInteger" SG_ 380 GrdAsstAllw_D_DsplyPt 1;
BA_ "GenSigStartValue" SG_ 380 GrdAsstAllw_D_DsplyPt 1;
BA_ "U_CX727_MY2021_Rx" SG_ 380 GrdAsstAllw_D_DsplyPt 1;
BA_ "U_CD542_MY2021_Rx" SG_ 380 GrdAsstAllw_D_DsplyPt 1;
BA_ "U_CX727_MY2021_Tx" SG_ 380 GrdAsstAllw_D_DsplyPt 1;
BA_ "U_CD542_MY2021_Tx" SG_ 380 GrdAsstAllw_D_DsplyPt 1;
BA_ "WakeupSignal" SG_ 380 EngOilLvlWarn_D_Rq1 1;
BA_ "U_CX727_MY2021_Tx" SG_ 380 EngOilLvlWarn_D_Rq1 1;
BA_ "U_P702_MY2021_Tx" SG_ 380 EngOilLvlWarn_D_Rq1 1;
BA_ "U_T6_MCA_MY2020_Tx" SG_ 380 EngOilLvlWarn_D_Rq1 1;
BA_ "U_CD542_MY2021_Tx" SG_ 380 EngOilLvlWarn_D_Rq1 1;
BA_ "U_U55X_MY2022_Tx" SG_ 380 EngOilLvlWarn_D_Rq1 1;
BA_ "U_CD764_MY2022_Tx" SG_ 380 EngOilLvlWarn_D_Rq1 1;
BA_ "U_CX727_MY2021_Rx" SG_ 380 EngAout_N_MxAllw 1;
BA_ "U_P702_MY2021_Rx" SG_ 380 EngAout_N_MxAllw 1;
BA_ "U_CD542_MY2021_Rx" SG_ 380 EngAout_N_MxAllw 1;
BA_ "U_CX727_MY2021_Tx" SG_ 380 EngAout_N_MxAllw 1;
BA_ "U_P702_MY2021_Tx" SG_ 380 EngAout_N_MxAllw 1;
BA_ "U_T6_MCA_MY2020_Tx" SG_ 380 EngAout_N_MxAllw 1;
BA_ "U_CD542_MY2021_Tx" SG_ 380 EngAout_N_MxAllw 1;
BA_ "U_CX727_MY2021_Tx" SG_ 377 HvacAirFullOut_B_Rq 1;
BA_ "U_P702_MY2021_Tx" SG_ 377 HvacAirFullOut_B_Rq 1;
BA_ "U_T6_MCA_MY2020_Tx" SG_ 377 HvacAirFullOut_B_Rq 1;
BA_ "U_CD542_MY2021_Tx" SG_ 377 HvacAirFullOut_B_Rq 1;
BA_ "U_U55X_MY2022_Tx" SG_ 377 HvacAirFullOut_B_Rq 1;
BA_ "U_CD764_MY2022_Tx" SG_ 377 HvacAirFullOut_B_Rq 1;
BA_ "U_CX727_MY2021_Tx" SG_ 377 TrnManShif_D_IndDrv 1;
BA_ "U_T6_MCA_MY2020_Tx" SG_ 377 TrnManShif_D_IndDrv 1;
BA_ "U_CD542_MY2021_Tx" SG_ 377 TrnManShif_D_IndDrv 1;
BA_ "U_CX727_MY2021_Rx" SG_ 377 EngAout_Tq_Actl 1;
BA_ "U_CD542_MY2021_Rx" SG_ 377 EngAout_Tq_Actl 1;
BA_ "U_CX727_MY2021_Tx" SG_ 377 EngAout_Tq_Actl 1;
BA_ "U_CD542_MY2021_Tx" SG_ 377 EngAout_Tq_Actl 1;
BA_ "U_CX727_MY2021_Tx" SG_ 377 TrnManShifGear_D_IndDrv 1;
BA_ "U_T6_MCA_MY2020_Tx" SG_ 377 TrnManShifGear_D_IndDrv 1;
BA_ "U_CD542_MY2021_Tx" SG_ 377 TrnManShifGear_D_IndDrv 1;
BA_ "ContentDependant" SG_ 377 EngFuelCutFull_B_Inhbt 1;
BA_ "U_CX727_MY2021_Rx" SG_ 377 EngFuelCutFull_B_Inhbt 1;
BA_ "U_CD542_MY2021_Rx" SG_ 377 EngFuelCutFull_B_Inhbt 1;
BA_ "U_CX727_MY2021_Tx" SG_ 377 EngFuelCutFull_B_Inhbt 1;
BA_ "U_CD542_MY2021_Tx" SG_ 377 EngFuelCutFull_B_Inhbt 1;
BA_ "ContentDependant" SG_ 377 FuelFlw_Vl_Dsply 1;
BA_ "U_CX727_MY2021_Rx" SG_ 377 FuelFlw_Vl_Dsply 1;
BA_ "U_T6_MCA_MY2020_Rx" SG_ 377 FuelFlw_Vl_Dsply 1;
BA_ "ECGUsedRxSignal" SG_ 377 FuelFlw_Vl_Dsply 1;
BA_ "U_CD542_MY2021_Rx" SG_ 377 FuelFlw_Vl_Dsply 1;
BA_ "U_U55X_MY2022_Rx" SG_ 377 FuelFlw_Vl_Dsply 1;
BA_ "U_CD764_MY2022_Rx" SG_ 377 FuelFlw_Vl_Dsply 1;
BA_ "U_CX727_MY2021_Tx" SG_ 377 FuelFlw_Vl_Dsply 1;
BA_ "U_P702_MY2021_Tx" SG_ 377 FuelFlw_Vl_Dsply 1;
BA_ "U_T6_MCA_MY2020_Tx" SG_ 377 FuelFlw_Vl_Dsply 1;
BA_ "U_CD542_MY2021_Tx" SG_ 377 FuelFlw_Vl_Dsply 1;
BA_ "U_U55X_MY2022_Tx" SG_ 377 FuelFlw_Vl_Dsply 1;
BA_ "U_CD764_MY2022_Tx" SG_ 377 FuelFlw_Vl_Dsply 1;
BA_ "ContentDependant" SG_ 377 FuelFillInlet_B_Dsply 1;
BA_ "U_P702_MY2021_Tx" SG_ 377 FuelFillInlet_B_Dsply 1;
BA_ "U_T6_MCA_MY2020_Tx" SG_ 377 FuelFillInlet_B_Dsply 1;
BA_ "U_CD542_MY2021_Tx" SG_ 377 FuelFillInlet_B_Dsply 1;
BA_ "U_U55X_MY2022_Tx" SG_ 377 FuelFillInlet_B_Dsply 1;
BA_ "U_CD764_MY2022_Tx" SG_ 377 FuelFillInlet_B_Dsply 1;
BA_ "U_T6_MCA_MY2020_Rx" SG_ 377 EngSrvcRqd_B_Rq 1;
BA_ "ECGUsedRxSignal" SG_ 377 EngSrvcRqd_B_Rq 1;
BA_ "U_CD542_MY2021_Rx" SG_ 377 EngSrvcRqd_B_Rq 1;
BA_ "U_U55X_MY2022_Rx" SG_ 377 EngSrvcRqd_B_Rq 1;
BA_ "U_CD764_MY2022_Rx" SG_ 377 EngSrvcRqd_B_Rq 1;
BA_ "U_CX727_MY2021_Tx" SG_ 377 EngSrvcRqd_B_Rq 1;
BA_ "U_P702_MY2021_Tx" SG_ 377 EngSrvcRqd_B_Rq 1;
BA_ "U_T6_MCA_MY2020_Tx" SG_ 377 EngSrvcRqd_B_Rq 1;
BA_ "U_CD542_MY2021_Tx" SG_ 377 EngSrvcRqd_B_Rq 1;
BA_ "U_U55X_MY2022_Tx" SG_ 377 EngSrvcRqd_B_Rq 1;
BA_ "U_CD764_MY2022_Tx" SG_ 377 EngSrvcRqd_B_Rq 1;
BA_ "ContentDependant" SG_ 377 OdoCount 1;
BA_ "U_CX727_MY2021_Tx" SG_ 377 OdoCount 1;
BA_ "U_P702_MY2021_Tx" SG_ 377 OdoCount 1;
BA_ "U_T6_MCA_MY2020_Tx" SG_ 377 OdoCount 1;
BA_ "U_CD542_MY2021_Tx" SG_ 377 OdoCount 1;
BA_ "U_U55X_MY2022_Tx" SG_ 377 OdoCount 1;
BA_ "U_CD764_MY2022_Tx" SG_ 377 OdoCount 1;
BA_ "ContentDependant" SG_ 377 EngOilLife_Pc_Actl 1;
BA_ "U_T6_MCA_MY2020_Rx" SG_ 377 EngOilLife_Pc_Actl 1;
BA_ "ECGUsedRxSignal" SG_ 377 EngOilLife_Pc_Actl 1;
BA_ "U_CD542_MY2021_Rx" SG_ 377 EngOilLife_Pc_Actl 1;
BA_ "U_U55X_MY2022_Rx" SG_ 377 EngOilLife_Pc_Actl 1;
BA_ "U_CD764_MY2022_Rx" SG_ 377 EngOilLife_Pc_Actl 1;
BA_ "U_CX727_MY2021_Tx" SG_ 377 EngOilLife_Pc_Actl 1;
BA_ "U_P702_MY2021_Tx" SG_ 377 EngOilLife_Pc_Actl 1;
BA_ "U_T6_MCA_MY2020_Tx" SG_ 377 EngOilLife_Pc_Actl 1;
BA_ "U_CD542_MY2021_Tx" SG_ 377 EngOilLife_Pc_Actl 1;
BA_ "U_U55X_MY2022_Tx" SG_ 377 EngOilLife_Pc_Actl 1;
BA_ "U_CD764_MY2022_Tx" SG_ 377 EngOilLife_Pc_Actl 1;
BA_ "ContentDependant" SG_ 377 AirCondRec_B_Rq 1;
BA_ "U_CX727_MY2021_Tx" SG_ 377 AirCondRec_B_Rq 1;
BA_ "U_P702_MY2021_Tx" SG_ 377 AirCondRec_B_Rq 1;
BA_ "U_T6_MCA_MY2020_Tx" SG_ 377 AirCondRec_B_Rq 1;
BA_ "U_CD542_MY2021_Tx" SG_ 377 AirCondRec_B_Rq 1;
BA_ "U_U55X_MY2022_Tx" SG_ 377 AirCondRec_B_Rq 1;
BA_ "U_CD764_MY2022_Tx" SG_ 377 AirCondRec_B_Rq 1;
BA_ "ContentDependant" SG_ 377 AirCondClutch_B_Stats 1;
BA_ "U_CX727_MY2021_Tx" SG_ 377 AirCondClutch_B_Stats 1;
BA_ "U_P702_MY2021_Tx" SG_ 377 AirCondClutch_B_Stats 1;
BA_ "U_T6_MCA_MY2020_Tx" SG_ 377 AirCondClutch_B_Stats 1;
BA_ "U_CD542_MY2021_Tx" SG_ 377 AirCondClutch_B_Stats 1;
BA_ "U_U55X_MY2022_Tx" SG_ 377 AirCondClutch_B_Stats 1;
BA_ "U_CD764_MY2022_Tx" SG_ 377 AirCondClutch_B_Stats 1;
BA_ "MetaData" SG_ 377 EngAoutTqActl_D_Qf 1;
BA_ "U_CX727_MY2021_Rx" SG_ 377 EngAoutTqActl_D_Qf 1;
BA_ "U_CD542_MY2021_Rx" SG_ 377 EngAoutTqActl_D_Qf 1;
BA_ "U_CX727_MY2021_Tx" SG_ 377 EngAoutTqActl_D_Qf 1;
BA_ "U_CD542_MY2021_Tx" SG_ 377 EngAoutTqActl_D_Qf 1;
BA_ "U_CX727_MY2021_Tx" SG_ 376 GasPrtc_D_RqDsply 1;
BA_ "U_P702_MY2021_Tx" SG_ 376 GasPrtc_D_RqDsply 1;
BA_ "U_T6_MCA_MY2020_Tx" SG_ 376 GasPrtc_D_RqDsply 1;
BA_ "U_CD542_MY2021_Tx" SG_ 376 GasPrtc_D_RqDsply 1;
BA_ "U_U55X_MY2022_Tx" SG_ 376 GasPrtc_D_RqDsply 1;
BA_ "U_CD764_MY2022_Tx" SG_ 376 GasPrtc_D_RqDsply 1;
BA_ "ContentDependant" SG_ 376 EngAout_Aa_Actl 1;
BA_ "U_CX727_MY2021_Rx" SG_ 376 EngAout_Aa_Actl 1;
BA_ "U_P702_MY2021_Rx" SG_ 376 EngAout_Aa_Actl 1;
BA_ "U_T6_MCA_MY2020_Rx" SG_ 376 EngAout_Aa_Actl 1;
BA_ "U_CD542_MY2021_Rx" SG_ 376 EngAout_Aa_Actl 1;
BA_ "U_U55X_MY2022_Rx" SG_ 376 EngAout_Aa_Actl 1;
BA_ "U_CD764_MY2022_Rx" SG_ 376 EngAout_Aa_Actl 1;
BA_ "U_CX727_MY2021_Tx" SG_ 376 EngAout_Aa_Actl 1;
BA_ "U_P702_MY2021_Tx" SG_ 376 EngAout_Aa_Actl 1;
BA_ "U_T6_MCA_MY2020_Tx" SG_ 376 EngAout_Aa_Actl 1;
BA_ "U_CD542_MY2021_Tx" SG_ 376 EngAout_Aa_Actl 1;
BA_ "U_U55X_MY2022_Tx" SG_ 376 EngAout_Aa_Actl 1;
BA_ "U_CD764_MY2022_Tx" SG_ 376 EngAout_Aa_Actl 1;
BA_ "U_CX727_MY2021_Rx" SG_ 376 DynoMde_B_Cmd 1;
BA_ "U_P702_MY2021_Rx" SG_ 376 DynoMde_B_Cmd 1;
BA_ "U_T6_MCA_MY2020_Rx" SG_ 376 DynoMde_B_Cmd 1;
BA_ "U_CD542_MY2021_Rx" SG_ 376 DynoMde_B_Cmd 1;
BA_ "U_U55X_MY2022_Rx" SG_ 376 DynoMde_B_Cmd 1;
BA_ "U_CD764_MY2022_Rx" SG_ 376 DynoMde_B_Cmd 1;
BA_ "U_CX727_MY2021_Tx" SG_ 376 DynoMde_B_Cmd 1;
BA_ "U_P702_MY2021_Tx" SG_ 376 DynoMde_B_Cmd 1;
BA_ "U_T6_MCA_MY2020_Tx" SG_ 376 DynoMde_B_Cmd 1;
BA_ "U_CD542_MY2021_Tx" SG_ 376 DynoMde_B_Cmd 1;
BA_ "U_U55X_MY2022_Tx" SG_ 376 DynoMde_B_Cmd 1;
BA_ "U_CD764_MY2022_Tx" SG_ 376 DynoMde_B_Cmd 1;
BA_ "U_CX727_MY2021_Tx" SG_ 376 AslChime_B_Rq 1;
BA_ "U_P702_MY2021_Tx" SG_ 376 AslChime_B_Rq 1;
BA_ "U_T6_MCA_MY2020_Tx" SG_ 376 AslChime_B_Rq 1;
BA_ "U_CD542_MY2021_Tx" SG_ 376 AslChime_B_Rq 1;
BA_ "U_CD764_MY2022_Tx" SG_ 376 AslChime_B_Rq 1;
BA_ "GenSigStartValueInteger" SG_ 376 HvacHtrCore2_Te_Actl 200;
BA_ "U_CX727_MY2021_Rx" SG_ 376 HvacHtrCore2_Te_Actl 1;
BA_ "U_P702_MY2021_Rx" SG_ 376 HvacHtrCore2_Te_Actl 1;
BA_ "U_CD542_MY2021_Rx" SG_ 376 HvacHtrCore2_Te_Actl 1;
BA_ "U_CX727_MY2021_Tx" SG_ 376 HvacHtrCore2_Te_Actl 1;
BA_ "U_P702_MY2021_Tx" SG_ 376 HvacHtrCore2_Te_Actl 1;
BA_ "U_CD542_MY2021_Tx" SG_ 376 HvacHtrCore2_Te_Actl 1;
BA_ "U_CX727_MY2021_Rx" SG_ 376 PtcHtr_D_Cmd 1;
BA_ "U_CD542_MY2021_Rx" SG_ 376 PtcHtr_D_Cmd 1;
BA_ "U_CX727_MY2021_Tx" SG_ 376 PtcHtr_D_Cmd 1;
BA_ "U_CD542_MY2021_Tx" SG_ 376 PtcHtr_D_Cmd 1;
BA_ "U_P702_MY2021_Tx" SG_ 376 EcssLamp_D_RqDsply 1;
BA_ "U_T6_MCA_MY2020_Tx" SG_ 376 EcssLamp_D_RqDsply 1;
BA_ "GenSigStartValueInteger" SG_ 376 AirAmbTe_D_Qf 1;
BA_ "MetaData" SG_ 376 AirAmbTe_D_Qf 1;
BA_ "GenSigStartValue" SG_ 376 AirAmbTe_D_Qf 1;
BA_ "U_CX727_MY2021_Rx" SG_ 376 AirAmbTe_D_Qf 1;
BA_ "U_P702_MY2021_Rx" SG_ 376 AirAmbTe_D_Qf 1;
BA_ "U_T6_MCA_MY2020_Rx" SG_ 376 AirAmbTe_D_Qf 1;
BA_ "U_CD542_MY2021_Rx" SG_ 376 AirAmbTe_D_Qf 1;
BA_ "U_U55X_MY2022_Rx" SG_ 376 AirAmbTe_D_Qf 1;
BA_ "U_CD764_MY2022_Rx" SG_ 376 AirAmbTe_D_Qf 1;
BA_ "U_CX727_MY2021_Tx" SG_ 376 AirAmbTe_D_Qf 1;
BA_ "U_P702_MY2021_Tx" SG_ 376 AirAmbTe_D_Qf 1;
BA_ "U_T6_MCA_MY2020_Tx" SG_ 376 AirAmbTe_D_Qf 1;
BA_ "U_CD542_MY2021_Tx" SG_ 376 AirAmbTe_D_Qf 1;
BA_ "U_U55X_MY2022_Tx" SG_ 376 AirAmbTe_D_Qf 1;
BA_ "U_CD764_MY2022_Tx" SG_ 376 AirAmbTe_D_Qf 1;
BA_ "GenSigStartValueInteger" SG_ 376 AirAmb_Te_ActlFilt 512;
BA_ "U_CX727_MY2021_Rx" SG_ 376 AirAmb_Te_ActlFilt 1;
BA_ "U_P702_MY2021_Rx" SG_ 376 AirAmb_Te_ActlFilt 1;
BA_ "U_T6_MCA_MY2020_Rx" SG_ 376 AirAmb_Te_ActlFilt 1;
BA_ "ECGUsedRxSignal" SG_ 376 AirAmb_Te_ActlFilt 1;
BA_ "U_CD542_MY2021_Rx" SG_ 376 AirAmb_Te_ActlFilt 1;
BA_ "U_U55X_MY2022_Rx" SG_ 376 AirAmb_Te_ActlFilt 1;
BA_ "U_CD764_MY2022_Rx" SG_ 376 AirAmb_Te_ActlFilt 1;
BA_ "U_CX727_MY2021_Tx" SG_ 376 AirAmb_Te_ActlFilt 1;
BA_ "U_P702_MY2021_Tx" SG_ 376 AirAmb_Te_ActlFilt 1;
BA_ "U_T6_MCA_MY2020_Tx" SG_ 376 AirAmb_Te_ActlFilt 1;
BA_ "U_CD542_MY2021_Tx" SG_ 376 AirAmb_Te_ActlFilt 1;
BA_ "U_U55X_MY2022_Tx" SG_ 376 AirAmb_Te_ActlFilt 1;
BA_ "U_CD764_MY2022_Tx" SG_ 376 AirAmb_Te_ActlFilt 1;
BA_ "U_CX727_MY2021_Rx" SG_ 376 AirAmb_P_Actl 1;
BA_ "U_P702_MY2021_Rx" SG_ 376 AirAmb_P_Actl 1;
BA_ "U_T6_MCA_MY2020_Rx" SG_ 376 AirAmb_P_Actl 1;
BA_ "U_CD542_MY2021_Rx" SG_ 376 AirAmb_P_Actl 1;
BA_ "U_U55X_MY2022_Rx" SG_ 376 AirAmb_P_Actl 1;
BA_ "U_CD764_MY2022_Rx" SG_ 376 AirAmb_P_Actl 1;
BA_ "U_CX727_MY2021_Tx" SG_ 376 AirAmb_P_Actl 1;
BA_ "U_P702_MY2021_Tx" SG_ 376 AirAmb_P_Actl 1;
BA_ "U_T6_MCA_MY2020_Tx" SG_ 376 AirAmb_P_Actl 1;
BA_ "U_CD542_MY2021_Tx" SG_ 376 AirAmb_P_Actl 1;
BA_ "U_U55X_MY2022_Tx" SG_ 376 AirAmb_P_Actl 1;
BA_ "U_CD764_MY2022_Tx" SG_ 376 AirAmb_P_Actl 1;
BA_ "U_CX727_MY2021_Tx" SG_ 376 AslIconDsply_D_Rq 1;
BA_ "U_P702_MY2021_Tx" SG_ 376 AslIconDsply_D_Rq 1;
BA_ "U_T6_MCA_MY2020_Tx" SG_ 376 AslIconDsply_D_Rq 1;
BA_ "U_CD542_MY2021_Tx" SG_ 376 AslIconDsply_D_Rq 1;
BA_ "U_CD764_MY2022_Tx" SG_ 376 AslIconDsply_D_Rq 1;
BA_ "GenSigStartValueInteger" SG_ 376 AirAmb_Te_Actl 512;
BA_ "U_CX727_MY2021_Rx" SG_ 376 AirAmb_Te_Actl 1;
BA_ "U_P702_MY2021_Rx" SG_ 376 AirAmb_Te_Actl 1;
BA_ "U_T6_MCA_MY2020_Rx" SG_ 376 AirAmb_Te_Actl 1;
BA_ "U_CD542_MY2021_Rx" SG_ 376 AirAmb_Te_Actl 1;
BA_ "U_U55X_MY2022_Rx" SG_ 376 AirAmb_Te_Actl 1;
BA_ "U_CD764_MY2022_Rx" SG_ 376 AirAmb_Te_Actl 1;
BA_ "U_CX727_MY2021_Tx" SG_ 376 AirAmb_Te_Actl 1;
BA_ "U_P702_MY2021_Tx" SG_ 376 AirAmb_Te_Actl 1;
BA_ "U_T6_MCA_MY2020_Tx" SG_ 376 AirAmb_Te_Actl 1;
BA_ "U_CD542_MY2021_Tx" SG_ 376 AirAmb_Te_Actl 1;
BA_ "U_U55X_MY2022_Tx" SG_ 376 AirAmb_Te_Actl 1;
BA_ "U_CD764_MY2022_Tx" SG_ 376 AirAmb_Te_Actl 1;
BA_ "ContentDependant" SG_ 373 EngFuelCutFull_B_Allw 1;
BA_ "U_CX727_MY2021_Rx" SG_ 373 EngFuelCutFull_B_Allw 1;
BA_ "U_CD542_MY2021_Rx" SG_ 373 EngFuelCutFull_B_Allw 1;
BA_ "U_CX727_MY2021_Tx" SG_ 373 EngFuelCutFull_B_Allw 1;
BA_ "U_CD542_MY2021_Tx" SG_ 373 EngFuelCutFull_B_Allw 1;
BA_ "ContentDependant" SG_ 373 EngAout_Tq_MxActlN 1;
BA_ "U_CD542_MY2021_Tx" SG_ 373 EngAout_Tq_MxActlN 1;
BA_ "U_CX727_MY2021_Tx" SG_ 359 LscmbbEngTqMn_B_Actl 1;
BA_ "U_CD542_MY2021_Tx" SG_ 359 LscmbbEngTqMn_B_Actl 1;
BA_ "U_CX727_MY2021_Tx" SG_ 359 LscmbbDeny_B_ActlPrpl 1;
BA_ "U_CD542_MY2021_Tx" SG_ 359 LscmbbDeny_B_ActlPrpl 1;
BA_ "GenSigStartValueInteger" SG_ 359 PrplWhlRgenMn_Tq_Actl 4095;
BA_ "U_CX727_MY2021_Rx" SG_ 359 PrplWhlRgenMn_Tq_Actl 1;
BA_ "U_P702_MY2021_Rx" SG_ 359 PrplWhlRgenMn_Tq_Actl 1;
BA_ "U_CD542_MY2021_Rx" SG_ 359 PrplWhlRgenMn_Tq_Actl 1;
BA_ "U_CD764_MY2022_Rx" SG_ 359 PrplWhlRgenMn_Tq_Actl 1;
BA_ "U_CX727_MY2021_Tx" SG_ 359 PrplWhlRgenMn_Tq_Actl 1;
BA_ "U_P702_MY2021_Tx" SG_ 359 PrplWhlRgenMn_Tq_Actl 1;
BA_ "U_CD542_MY2021_Tx" SG_ 359 PrplWhlRgenMn_Tq_Actl 1;
BA_ "U_P702_MY2021_Rx" SG_ 359 ElPw_D_StatStrtStop 1;
BA_ "U_T6_MCA_MY2020_Rx" SG_ 359 ElPw_D_StatStrtStop 1;
BA_ "U_CD542_MY2021_Rx" SG_ 359 ElPw_D_StatStrtStop 1;
BA_ "U_U55X_MY2022_Rx" SG_ 359 ElPw_D_StatStrtStop 1;
BA_ "U_CD764_MY2022_Rx" SG_ 359 ElPw_D_StatStrtStop 1;
BA_ "U_CX727_MY2021_Tx" SG_ 359 ElPw_D_StatStrtStop 1;
BA_ "U_P702_MY2021_Tx" SG_ 359 ElPw_D_StatStrtStop 1;
BA_ "U_T6_MCA_MY2020_Tx" SG_ 359 ElPw_D_StatStrtStop 1;
BA_ "U_CD542_MY2021_Tx" SG_ 359 ElPw_D_StatStrtStop 1;
BA_ "U_U55X_MY2022_Tx" SG_ 359 ElPw_D_StatStrtStop 1;
BA_ "U_CD764_MY2022_Tx" SG_ 359 ElPw_D_StatStrtStop 1;
BA_ "ContentDependant" SG_ 359 TrnAin_Tq_Actl 1;
BA_ "U_CX727_MY2021_Rx" SG_ 359 TrnAin_Tq_Actl 1;
BA_ "U_P702_MY2021_Rx" SG_ 359 TrnAin_Tq_Actl 1;
BA_ "U_T6_MCA_MY2020_Rx" SG_ 359 TrnAin_Tq_Actl 1;
BA_ "U_CD542_MY2021_Rx" SG_ 359 TrnAin_Tq_Actl 1;
BA_ "U_U55X_MY2022_Rx" SG_ 359 TrnAin_Tq_Actl 1;
BA_ "U_CD764_MY2022_Rx" SG_ 359 TrnAin_Tq_Actl 1;
BA_ "U_CX727_MY2021_Tx" SG_ 359 TrnAin_Tq_Actl 1;
BA_ "U_P702_MY2021_Tx" SG_ 359 TrnAin_Tq_Actl 1;
BA_ "U_T6_MCA_MY2020_Tx" SG_ 359 TrnAin_Tq_Actl 1;
BA_ "U_CD542_MY2021_Tx" SG_ 359 TrnAin_Tq_Actl 1;
BA_ "U_U55X_MY2022_Tx" SG_ 359 TrnAin_Tq_Actl 1;
BA_ "U_CD764_MY2022_Tx" SG_ 359 TrnAin_Tq_Actl 1;
BA_ "U_CX727_MY2021_Rx" SG_ 359 PrplWhlTot2_Tq_Actl 1;
BA_ "U_P702_MY2021_Rx" SG_ 359 PrplWhlTot2_Tq_Actl 1;
BA_ "U_T6_MCA_MY2020_Rx" SG_ 359 PrplWhlTot2_Tq_Actl 1;
BA_ "ECGUsedRxSignal" SG_ 359 PrplWhlTot2_Tq_Actl 1;
BA_ "U_CD542_MY2021_Rx" SG_ 359 PrplWhlTot2_Tq_Actl 1;
BA_ "U_U55X_MY2022_Rx" SG_ 359 PrplWhlTot2_Tq_Actl 1;
BA_ "U_CD764_MY2022_Rx" SG_ 359 PrplWhlTot2_Tq_Actl 1;
BA_ "U_CX727_MY2021_Tx" SG_ 359 PrplWhlTot2_Tq_Actl 1;
BA_ "U_P702_MY2021_Tx" SG_ 359 PrplWhlTot2_Tq_Actl 1;
BA_ "U_T6_MCA_MY2020_Tx" SG_ 359 PrplWhlTot2_Tq_Actl 1;
BA_ "U_CD542_MY2021_Tx" SG_ 359 PrplWhlTot2_Tq_Actl 1;
BA_ "U_U55X_MY2022_Tx" SG_ 359 PrplWhlTot2_Tq_Actl 1;
BA_ "U_CD764_MY2022_Tx" SG_ 359 PrplWhlTot2_Tq_Actl 1;
BA_ "U_CX727_MY2021_Rx" SG_ 359 PwPckTq_D_Stat 1;
BA_ "U_P702_MY2021_Rx" SG_ 359 PwPckTq_D_Stat 1;
BA_ "U_T6_MCA_MY2020_Rx" SG_ 359 PwPckTq_D_Stat 1;
BA_ "ECGUsedRxSignal" SG_ 359 PwPckTq_D_Stat 1;
BA_ "U_CD542_MY2021_Rx" SG_ 359 PwPckTq_D_Stat 1;
BA_ "U_U55X_MY2022_Rx" SG_ 359 PwPckTq_D_Stat 1;
BA_ "U_CD764_MY2022_Rx" SG_ 359 PwPckTq_D_Stat 1;
BA_ "U_CX727_MY2021_Tx" SG_ 359 PwPckTq_D_Stat 1;
BA_ "U_P702_MY2021_Tx" SG_ 359 PwPckTq_D_Stat 1;
BA_ "U_T6_MCA_MY2020_Tx" SG_ 359 PwPckTq_D_Stat 1;
BA_ "U_CD542_MY2021_Tx" SG_ 359 PwPckTq_D_Stat 1;
BA_ "U_U55X_MY2022_Tx" SG_ 359 PwPckTq_D_Stat 1;
BA_ "U_CD764_MY2022_Tx" SG_ 359 PwPckTq_D_Stat 1;
BA_ "U_CX727_MY2021_Rx" SG_ 359 Eng_D_Stat 1;
BA_ "U_P702_MY2021_Rx" SG_ 359 Eng_D_Stat 1;
BA_ "U_T6_MCA_MY2020_Rx" SG_ 359 Eng_D_Stat 1;
BA_ "ECGUsedRxSignal" SG_ 359 Eng_D_Stat 1;
BA_ "U_CD542_MY2021_Rx" SG_ 359 Eng_D_Stat 1;
BA_ "U_U55X_MY2022_Rx" SG_ 359 Eng_D_Stat 1;
BA_ "U_CD764_MY2022_Rx" SG_ 359 Eng_D_Stat 1;
BA_ "U_CX727_MY2021_Tx" SG_ 359 Eng_D_Stat 1;
BA_ "U_P702_MY2021_Tx" SG_ 359 Eng_D_Stat 1;
BA_ "U_T6_MCA_MY2020_Tx" SG_ 359 Eng_D_Stat 1;
BA_ "U_CD542_MY2021_Tx" SG_ 359 Eng_D_Stat 1;
BA_ "U_U55X_MY2022_Tx" SG_ 359 Eng_D_Stat 1;
BA_ "U_CD764_MY2022_Tx" SG_ 359 Eng_D_Stat 1;
BA_ "GenSigStartValueInteger" SG_ 359 PlgActvArb_B_Actl 1;
BA_ "ContentDependant" SG_ 359 PlgActvArb_B_Actl 1;
BA_ "GenSigStartValue" SG_ 359 PlgActvArb_B_Actl 1;
BA_ "ECGUsedRxSignal" SG_ 359 PlgActvArb_B_Actl 1;
BA_ "U_CD542_MY2021_Rx" SG_ 359 PlgActvArb_B_Actl 1;
BA_ "U_U55X_MY2022_Rx" SG_ 359 PlgActvArb_B_Actl 1;
BA_ "U_CD764_MY2022_Rx" SG_ 359 PlgActvArb_B_Actl 1;
BA_ "U_CX727_MY2021_Tx" SG_ 359 PlgActvArb_B_Actl 1;
BA_ "U_CD542_MY2021_Tx" SG_ 359 PlgActvArb_B_Actl 1;
BA_ "U_CX727_MY2021_Rx" SG_ 359 ElPw_D_Stat 1;
BA_ "U_P702_MY2021_Rx" SG_ 359 ElPw_D_Stat 1;
BA_ "U_T6_MCA_MY2020_Rx" SG_ 359 ElPw_D_Stat 1;
BA_ "U_CD542_MY2021_Rx" SG_ 359 ElPw_D_Stat 1;
BA_ "U_U55X_MY2022_Rx" SG_ 359 ElPw_D_Stat 1;
BA_ "U_CD764_MY2022_Rx" SG_ 359 ElPw_D_Stat 1;
BA_ "U_CX727_MY2021_Tx" SG_ 359 ElPw_D_Stat 1;
BA_ "U_P702_MY2021_Tx" SG_ 359 ElPw_D_Stat 1;
BA_ "U_T6_MCA_MY2020_Tx" SG_ 359 ElPw_D_Stat 1;
BA_ "U_CD542_MY2021_Tx" SG_ 359 ElPw_D_Stat 1;
BA_ "U_U55X_MY2022_Tx" SG_ 359 ElPw_D_Stat 1;
BA_ "U_CD764_MY2022_Tx" SG_ 359 ElPw_D_Stat 1;
BA_ "ContentDependant" SG_ 359 TrnAinTq_D_Qf 1;
BA_ "MetaData" SG_ 359 TrnAinTq_D_Qf 1;
BA_ "U_CX727_MY2021_Rx" SG_ 359 TrnAinTq_D_Qf 1;
BA_ "U_P702_MY2021_Rx" SG_ 359 TrnAinTq_D_Qf 1;
BA_ "U_T6_MCA_MY2020_Rx" SG_ 359 TrnAinTq_D_Qf 1;
BA_ "U_CD542_MY2021_Rx" SG_ 359 TrnAinTq_D_Qf 1;
BA_ "U_U55X_MY2022_Rx" SG_ 359 TrnAinTq_D_Qf 1;
BA_ "U_CD764_MY2022_Rx" SG_ 359 TrnAinTq_D_Qf 1;
BA_ "U_CX727_MY2021_Tx" SG_ 359 TrnAinTq_D_Qf 1;
BA_ "U_P702_MY2021_Tx" SG_ 359 TrnAinTq_D_Qf 1;
BA_ "U_T6_MCA_MY2020_Tx" SG_ 359 TrnAinTq_D_Qf 1;
BA_ "U_CD542_MY2021_Tx" SG_ 359 TrnAinTq_D_Qf 1;
BA_ "U_U55X_MY2022_Tx" SG_ 359 TrnAinTq_D_Qf 1;
BA_ "U_CD764_MY2022_Tx" SG_ 359 TrnAinTq_D_Qf 1;
BA_ "U_P702_MY2021_Tx" SG_ 358 StopStrtStdby_D_Indic 1;
BA_ "U_T6_MCA_MY2020_Tx" SG_ 358 StopStrtStdby_D_Indic 1;
BA_ "U_CD542_MY2021_Tx" SG_ 358 StopStrtStdby_D_Indic 1;
BA_ "U_U55X_MY2022_Tx" SG_ 358 StopStrtStdby_D_Indic 1;
BA_ "U_CD764_MY2022_Tx" SG_ 358 StopStrtStdby_D_Indic 1;
BA_ "U_P702_MY2021_Tx" SG_ 358 StopStrtIODTxt_D_Rq 1;
BA_ "U_T6_MCA_MY2020_Tx" SG_ 358 StopStrtIODTxt_D_Rq 1;
BA_ "U_CD542_MY2021_Tx" SG_ 358 StopStrtIODTxt_D_Rq 1;
BA_ "U_U55X_MY2022_Tx" SG_ 358 StopStrtIODTxt_D_Rq 1;
BA_ "U_CD764_MY2022_Tx" SG_ 358 StopStrtIODTxt_D_Rq 1;
BA_ "U_P702_MY2021_Tx" SG_ 358 StopStrtDrvMde_D_Indic 1;
BA_ "U_T6_MCA_MY2020_Tx" SG_ 358 StopStrtDrvMde_D_Indic 1;
BA_ "U_CD542_MY2021_Tx" SG_ 358 StopStrtDrvMde_D_Indic 1;
BA_ "U_U55X_MY2022_Tx" SG_ 358 StopStrtDrvMde_D_Indic 1;
BA_ "U_CD764_MY2022_Tx" SG_ 358 StopStrtDrvMde_D_Indic 1;
BA_ "U_P702_MY2021_Tx" SG_ 358 StopStrtMsgTxt_D_Rq 1;
BA_ "U_T6_MCA_MY2020_Tx" SG_ 358 StopStrtMsgTxt_D_Rq 1;
BA_ "U_CD542_MY2021_Tx" SG_ 358 StopStrtMsgTxt_D_Rq 1;
BA_ "U_U55X_MY2022_Tx" SG_ 358 StopStrtMsgTxt_D_Rq 1;
BA_ "U_CD764_MY2022_Tx" SG_ 358 StopStrtMsgTxt_D_Rq 1;
BA_ "U_CX727_MY2021_Tx" SG_ 358 OdoTripVerify_L_Actl 1;
BA_ "U_P702_MY2021_Tx" SG_ 358 OdoTripVerify_L_Actl 1;
BA_ "U_T6_MCA_MY2020_Tx" SG_ 358 OdoTripVerify_L_Actl 1;
BA_ "U_CD542_MY2021_Tx" SG_ 358 OdoTripVerify_L_Actl 1;
BA_ "U_U55X_MY2022_Tx" SG_ 358 OdoTripVerify_L_Actl 1;
BA_ "U_CD764_MY2022_Tx" SG_ 358 OdoTripVerify_L_Actl 1;
BA_ "ContentDependant" SG_ 358 HiElPwInhbt_B_Stat 1;
BA_ "U_P702_MY2021_Tx" SG_ 358 HiElPwInhbt_B_Stat 1;
BA_ "U_T6_MCA_MY2020_Tx" SG_ 358 HiElPwInhbt_B_Stat 1;
BA_ "U_CD542_MY2021_Tx" SG_ 358 HiElPwInhbt_B_Stat 1;
BA_ "U_U55X_MY2022_Tx" SG_ 358 HiElPwInhbt_B_Stat 1;
BA_ "U_CD764_MY2022_Tx" SG_ 358 HiElPwInhbt_B_Stat 1;
BA_ "GenSigStartValueInteger" SG_ 358 AutoStopPtDelta_I_Est 127;
BA_ "ContentDependant" SG_ 358 AutoStopPtDelta_I_Est 1;
BA_ "U_P702_MY2021_Tx" SG_ 358 AutoStopPtDelta_I_Est 1;
BA_ "U_T6_MCA_MY2020_Tx" SG_ 358 AutoStopPtDelta_I_Est 1;
BA_ "U_CD542_MY2021_Tx" SG_ 358 AutoStopPtDelta_I_Est 1;
BA_ "U_U55X_MY2022_Tx" SG_ 358 AutoStopPtDelta_I_Est 1;
BA_ "U_CD764_MY2022_Tx" SG_ 358 AutoStopPtDelta_I_Est 1;
BA_ "GenSigStartValueInteger" SG_ 357 BPedDrvAppl_D_QF 1;
BA_ "MetaData" SG_ 357 BPedDrvAppl_D_QF 1;
BA_ "GenSigStartValue" SG_ 357 BPedDrvAppl_D_QF 1;
BA_ "U_CX727_MY2021_Rx" SG_ 357 BPedDrvAppl_D_QF 1;
BA_ "U_P702_MY2021_Rx" SG_ 357 BPedDrvAppl_D_QF 1;
BA_ "U_T6_MCA_MY2020_Rx" SG_ 357 BPedDrvAppl_D_QF 1;
BA_ "U_CD542_MY2021_Rx" SG_ 357 BPedDrvAppl_D_QF 1;
BA_ "U_U55X_MY2022_Rx" SG_ 357 BPedDrvAppl_D_QF 1;
BA_ "U_CD764_MY2022_Rx" SG_ 357 BPedDrvAppl_D_QF 1;
BA_ "U_CX727_MY2021_Tx" SG_ 357 BPedDrvAppl_D_QF 1;
BA_ "U_P702_MY2021_Tx" SG_ 357 BPedDrvAppl_D_QF 1;
BA_ "U_T6_MCA_MY2020_Tx" SG_ 357 BPedDrvAppl_D_QF 1;
BA_ "U_CD542_MY2021_Tx" SG_ 357 BPedDrvAppl_D_QF 1;
BA_ "U_U55X_MY2022_Tx" SG_ 357 BPedDrvAppl_D_QF 1;
BA_ "U_CD764_MY2022_Tx" SG_ 357 BPedDrvAppl_D_QF 1;
BA_ "U_T6_MCA_MY2020_Rx" SG_ 357 CmbbDeny_B_ActlPrpl 1;
BA_ "U_CD542_MY2021_Rx" SG_ 357 CmbbDeny_B_ActlPrpl 1;
BA_ "U_U55X_MY2022_Rx" SG_ 357 CmbbDeny_B_ActlPrpl 1;
BA_ "U_CD764_MY2022_Rx" SG_ 357 CmbbDeny_B_ActlPrpl 1;
BA_ "U_CX727_MY2021_Tx" SG_ 357 CmbbDeny_B_ActlPrpl 1;
BA_ "U_P702_MY2021_Tx" SG_ 357 CmbbDeny_B_ActlPrpl 1;
BA_ "U_T6_MCA_MY2020_Tx" SG_ 357 CmbbDeny_B_ActlPrpl 1;
BA_ "U_CD542_MY2021_Tx" SG_ 357 CmbbDeny_B_ActlPrpl 1;
BA_ "U_U55X_MY2022_Tx" SG_ 357 CmbbDeny_B_ActlPrpl 1;
BA_ "U_CD764_MY2022_Tx" SG_ 357 CmbbDeny_B_ActlPrpl 1;
BA_ "U_T6_MCA_MY2020_Rx" SG_ 357 PrplTqMnSat_B_Actl 1;
BA_ "U_CD542_MY2021_Rx" SG_ 357 PrplTqMnSat_B_Actl 1;
BA_ "U_U55X_MY2022_Rx" SG_ 357 PrplTqMnSat_B_Actl 1;
BA_ "U_CD764_MY2022_Rx" SG_ 357 PrplTqMnSat_B_Actl 1;
BA_ "U_CX727_MY2021_Tx" SG_ 357 PrplTqMnSat_B_Actl 1;
BA_ "U_P702_MY2021_Tx" SG_ 357 PrplTqMnSat_B_Actl 1;
BA_ "U_T6_MCA_MY2020_Tx" SG_ 357 PrplTqMnSat_B_Actl 1;
BA_ "U_CD542_MY2021_Tx" SG_ 357 PrplTqMnSat_B_Actl 1;
BA_ "U_U55X_MY2022_Tx" SG_ 357 PrplTqMnSat_B_Actl 1;
BA_ "U_CD764_MY2022_Tx" SG_ 357 PrplTqMnSat_B_Actl 1;
BA_ "U_CX727_MY2021_Rx" SG_ 357 VehStrtStop_D_Rq 1;
BA_ "U_CD542_MY2021_Rx" SG_ 357 VehStrtStop_D_Rq 1;
BA_ "U_CX727_MY2021_Tx" SG_ 357 VehStrtStop_D_Rq 1;
BA_ "U_CD542_MY2021_Tx" SG_ 357 VehStrtStop_D_Rq 1;
BA_ "GenSigStartValueInteger" SG_ 357 BpedDrvAppl_D_Actl 1;
BA_ "GenSigStartValue" SG_ 357 BpedDrvAppl_D_Actl 1;
BA_ "U_CX727_MY2021_Rx" SG_ 357 BpedDrvAppl_D_Actl 1;
BA_ "U_P702_MY2021_Rx" SG_ 357 BpedDrvAppl_D_Actl 1;
BA_ "U_T6_MCA_MY2020_Rx" SG_ 357 BpedDrvAppl_D_Actl 1;
BA_ "ECGUsedRxSignal" SG_ 357 BpedDrvAppl_D_Actl 1;
BA_ "U_CD542_MY2021_Rx" SG_ 357 BpedDrvAppl_D_Actl 1;
BA_ "U_U55X_MY2022_Rx" SG_ 357 BpedDrvAppl_D_Actl 1;
BA_ "U_CD764_MY2022_Rx" SG_ 357 BpedDrvAppl_D_Actl 1;
BA_ "U_CX727_MY2021_Tx" SG_ 357 BpedDrvAppl_D_Actl 1;
BA_ "U_P702_MY2021_Tx" SG_ 357 BpedDrvAppl_D_Actl 1;
BA_ "U_T6_MCA_MY2020_Tx" SG_ 357 BpedDrvAppl_D_Actl 1;
BA_ "U_CD542_MY2021_Tx" SG_ 357 BpedDrvAppl_D_Actl 1;
BA_ "U_U55X_MY2022_Tx" SG_ 357 BpedDrvAppl_D_Actl 1;
BA_ "U_CD764_MY2022_Tx" SG_ 357 BpedDrvAppl_D_Actl 1;
BA_ "U_T6_MCA_MY2020_Rx" SG_ 357 CmbbEngTqMn_B_Actl 1;
BA_ "U_CD542_MY2021_Rx" SG_ 357 CmbbEngTqMn_B_Actl 1;
BA_ "U_U55X_MY2022_Rx" SG_ 357 CmbbEngTqMn_B_Actl 1;
BA_ "U_CD764_MY2022_Rx" SG_ 357 CmbbEngTqMn_B_Actl 1;
BA_ "U_CX727_MY2021_Tx" SG_ 357 CmbbEngTqMn_B_Actl 1;
BA_ "U_P702_MY2021_Tx" SG_ 357 CmbbEngTqMn_B_Actl 1;
BA_ "U_T6_MCA_MY2020_Tx" SG_ 357 CmbbEngTqMn_B_Actl 1;
BA_ "U_CD542_MY2021_Tx" SG_ 357 CmbbEngTqMn_B_Actl 1;
BA_ "U_U55X_MY2022_Tx" SG_ 357 CmbbEngTqMn_B_Actl 1;
BA_ "U_CD764_MY2022_Tx" SG_ 357 CmbbEngTqMn_B_Actl 1;
BA_ "U_T6_MCA_MY2020_Rx" SG_ 357 Veh_V_DsplyCcSet 1;
BA_ "U_CD542_MY2021_Rx" SG_ 357 Veh_V_DsplyCcSet 1;
BA_ "U_U55X_MY2022_Rx" SG_ 357 Veh_V_DsplyCcSet 1;
BA_ "U_CD764_MY2022_Rx" SG_ 357 Veh_V_DsplyCcSet 1;
BA_ "U_CX727_MY2021_Tx" SG_ 357 Veh_V_DsplyCcSet 1;
BA_ "U_P702_MY2021_Tx" SG_ 357 Veh_V_DsplyCcSet 1;
BA_ "U_T6_MCA_MY2020_Tx" SG_ 357 Veh_V_DsplyCcSet 1;
BA_ "U_CD542_MY2021_Tx" SG_ 357 Veh_V_DsplyCcSet 1;
BA_ "U_U55X_MY2022_Tx" SG_ 357 Veh_V_DsplyCcSet 1;
BA_ "U_CD764_MY2022_Tx" SG_ 357 Veh_V_DsplyCcSet 1;
BA_ "U_T6_MCA_MY2020_Rx" SG_ 357 AccEngStat_D_Actl 1;
BA_ "U_CD542_MY2021_Rx" SG_ 357 AccEngStat_D_Actl 1;
BA_ "U_U55X_MY2022_Rx" SG_ 357 AccEngStat_D_Actl 1;
BA_ "U_CD764_MY2022_Rx" SG_ 357 AccEngStat_D_Actl 1;
BA_ "U_CX727_MY2021_Tx" SG_ 357 AccEngStat_D_Actl 1;
BA_ "U_P702_MY2021_Tx" SG_ 357 AccEngStat_D_Actl 1;
BA_ "U_T6_MCA_MY2020_Tx" SG_ 357 AccEngStat_D_Actl 1;
BA_ "U_CD542_MY2021_Tx" SG_ 357 AccEngStat_D_Actl 1;
BA_ "U_U55X_MY2022_Tx" SG_ 357 AccEngStat_D_Actl 1;
BA_ "U_CD764_MY2022_Tx" SG_ 357 AccEngStat_D_Actl 1;
BA_ "U_CX727_MY2021_Rx" SG_ 357 CcMde_D_Actl 1;
BA_ "U_P702_MY2021_Rx" SG_ 357 CcMde_D_Actl 1;
BA_ "U_T6_MCA_MY2020_Rx" SG_ 357 CcMde_D_Actl 1;
BA_ "U_U55X_MY2022_Rx" SG_ 357 CcMde_D_Actl 1;
BA_ "U_CX727_MY2021_Tx" SG_ 357 CcMde_D_Actl 1;
BA_ "U_P702_MY2021_Tx" SG_ 357 CcMde_D_Actl 1;
BA_ "U_T6_MCA_MY2020_Tx" SG_ 357 CcMde_D_Actl 1;
BA_ "U_CD542_MY2021_Tx" SG_ 357 CcMde_D_Actl 1;
BA_ "U_U55X_MY2022_Tx" SG_ 357 CcMde_D_Actl 1;
BA_ "U_CD764_MY2022_Tx" SG_ 357 CcMde_D_Actl 1;
BA_ "U_CX727_MY2021_Rx" SG_ 357 CcStat_D_Actl 1;
BA_ "U_P702_MY2021_Rx" SG_ 357 CcStat_D_Actl 1;
BA_ "U_T6_MCA_MY2020_Rx" SG_ 357 CcStat_D_Actl 1;
BA_ "U_CD542_MY2021_Rx" SG_ 357 CcStat_D_Actl 1;
BA_ "U_U55X_MY2022_Rx" SG_ 357 CcStat_D_Actl 1;
BA_ "U_CD764_MY2022_Rx" SG_ 357 CcStat_D_Actl 1;
BA_ "U_CX727_MY2021_Tx" SG_ 357 CcStat_D_Actl 1;
BA_ "U_P702_MY2021_Tx" SG_ 357 CcStat_D_Actl 1;
BA_ "U_T6_MCA_MY2020_Tx" SG_ 357 CcStat_D_Actl 1;
BA_ "U_CD542_MY2021_Tx" SG_ 357 CcStat_D_Actl 1;
BA_ "U_U55X_MY2022_Tx" SG_ 357 CcStat_D_Actl 1;
BA_ "U_CD764_MY2022_Tx" SG_ 357 CcStat_D_Actl 1;
BA_ "U_CX727_MY2021_Rx" SG_ 357 EngAout_N_MnAllw 1;
BA_ "U_P702_MY2021_Rx" SG_ 357 EngAout_N_MnAllw 1;
BA_ "U_CD542_MY2021_Rx" SG_ 357 EngAout_N_MnAllw 1;
BA_ "U_CX727_MY2021_Tx" SG_ 357 EngAout_N_MnAllw 1;
BA_ "U_P702_MY2021_Tx" SG_ 357 EngAout_N_MnAllw 1;
BA_ "U_CD542_MY2021_Tx" SG_ 357 EngAout_N_MnAllw 1;
BA_ "U_CX727_MY2021_Rx" SG_ 357 CcOvrrdActv_B_Actl 1;
BA_ "U_P702_MY2021_Rx" SG_ 357 CcOvrrdActv_B_Actl 1;
BA_ "U_T6_MCA_MY2020_Rx" SG_ 357 CcOvrrdActv_B_Actl 1;
BA_ "U_CD542_MY2021_Rx" SG_ 357 CcOvrrdActv_B_Actl 1;
BA_ "U_U55X_MY2022_Rx" SG_ 357 CcOvrrdActv_B_Actl 1;
BA_ "U_CD764_MY2022_Rx" SG_ 357 CcOvrrdActv_B_Actl 1;
BA_ "U_CX727_MY2021_Tx" SG_ 357 CcOvrrdActv_B_Actl 1;
BA_ "U_P702_MY2021_Tx" SG_ 357 CcOvrrdActv_B_Actl 1;
BA_ "U_T6_MCA_MY2020_Tx" SG_ 357 CcOvrrdActv_B_Actl 1;
BA_ "U_CD542_MY2021_Tx" SG_ 357 CcOvrrdActv_B_Actl 1;
BA_ "U_U55X_MY2022_Tx" SG_ 357 CcOvrrdActv_B_Actl 1;
BA_ "U_CD764_MY2022_Tx" SG_ 357 CcOvrrdActv_B_Actl 1;
BA_ "U_CX727_MY2021_Rx" SG_ 357 AccStopMde_D_Rq 1;
BA_ "U_P702_MY2021_Rx" SG_ 357 AccStopMde_D_Rq 1;
BA_ "U_T6_MCA_MY2020_Rx" SG_ 357 AccStopMde_D_Rq 1;
BA_ "U_CD542_MY2021_Rx" SG_ 357 AccStopMde_D_Rq 1;
BA_ "U_U55X_MY2022_Rx" SG_ 357 AccStopMde_D_Rq 1;
BA_ "U_CD764_MY2022_Rx" SG_ 357 AccStopMde_D_Rq 1;
BA_ "U_CX727_MY2021_Tx" SG_ 357 AccStopMde_D_Rq 1;
BA_ "U_P702_MY2021_Tx" SG_ 357 AccStopMde_D_Rq 1;
BA_ "U_T6_MCA_MY2020_Tx" SG_ 357 AccStopMde_D_Rq 1;
BA_ "U_CD542_MY2021_Tx" SG_ 357 AccStopMde_D_Rq 1;
BA_ "U_U55X_MY2022_Tx" SG_ 357 AccStopMde_D_Rq 1;
BA_ "U_CD764_MY2022_Tx" SG_ 357 AccStopMde_D_Rq 1;
BA_ "U_CX727_MY2021_Rx" SG_ 342 HtrLoop_B_Stat 1;
BA_ "U_CD542_MY2021_Rx" SG_ 342 HtrLoop_B_Stat 1;
BA_ "U_CX727_MY2021_Tx" SG_ 342 HtrLoop_B_Stat 1;
BA_ "U_CD542_MY2021_Tx" SG_ 342 HtrLoop_B_Stat 1;
BA_ "ContentDependant" SG_ 342 EngOvrhtMitgActv_D_Ind 1;
BA_ "U_CX727_MY2021_Tx" SG_ 342 EngOvrhtMitgActv_D_Ind 1;
BA_ "U_P702_MY2021_Tx" SG_ 342 EngOvrhtMitgActv_D_Ind 1;
BA_ "U_T6_MCA_MY2020_Tx" SG_ 342 EngOvrhtMitgActv_D_Ind 1;
BA_ "U_CD542_MY2021_Tx" SG_ 342 EngOvrhtMitgActv_D_Ind 1;
BA_ "U_U55X_MY2022_Tx" SG_ 342 EngOvrhtMitgActv_D_Ind 1;
BA_ "U_CD764_MY2022_Tx" SG_ 342 EngOvrhtMitgActv_D_Ind 1;
BA_ "MetaData" SG_ 342 EngClntTe_D_Qf 1;
BA_ "U_CX727_MY2021_Rx" SG_ 342 EngClntTe_D_Qf 1;
BA_ "U_P702_MY2021_Rx" SG_ 342 EngClntTe_D_Qf 1;
BA_ "U_T6_MCA_MY2020_Rx" SG_ 342 EngClntTe_D_Qf 1;
BA_ "U_CD542_MY2021_Rx" SG_ 342 EngClntTe_D_Qf 1;
BA_ "U_U55X_MY2022_Rx" SG_ 342 EngClntTe_D_Qf 1;
BA_ "U_CX727_MY2021_Tx" SG_ 342 EngClntTe_D_Qf 1;
BA_ "U_P702_MY2021_Tx" SG_ 342 EngClntTe_D_Qf 1;
BA_ "U_T6_MCA_MY2020_Tx" SG_ 342 EngClntTe_D_Qf 1;
BA_ "U_CD542_MY2021_Tx" SG_ 342 EngClntTe_D_Qf 1;
BA_ "U_U55X_MY2022_Tx" SG_ 342 EngClntTe_D_Qf 1;
BA_ "U_CD764_MY2022_Tx" SG_ 342 EngClntTe_D_Qf 1;
BA_ "ContentDependant" SG_ 342 EngGoutLss_Tq_Est 1;
BA_ "U_CX727_MY2021_Rx" SG_ 342 EngGoutLss_Tq_Est 1;
BA_ "U_P702_MY2021_Rx" SG_ 342 EngGoutLss_Tq_Est 1;
BA_ "U_CD542_MY2021_Rx" SG_ 342 EngGoutLss_Tq_Est 1;
BA_ "U_CX727_MY2021_Tx" SG_ 342 EngGoutLss_Tq_Est 1;
BA_ "U_P702_MY2021_Tx" SG_ 342 EngGoutLss_Tq_Est 1;
BA_ "U_CD542_MY2021_Tx" SG_ 342 EngGoutLss_Tq_Est 1;
BA_ "U_CX727_MY2021_Rx" SG_ 342 EngClnt_Te_Actl 1;
BA_ "U_P702_MY2021_Rx" SG_ 342 EngClnt_Te_Actl 1;
BA_ "U_T6_MCA_MY2020_Rx" SG_ 342 EngClnt_Te_Actl 1;
BA_ "ECGUsedRxSignal" SG_ 342 EngClnt_Te_Actl 1;
BA_ "U_CD542_MY2021_Rx" SG_ 342 EngClnt_Te_Actl 1;
BA_ "U_U55X_MY2022_Rx" SG_ 342 EngClnt_Te_Actl 1;
BA_ "U_CD764_MY2022_Rx" SG_ 342 EngClnt_Te_Actl 1;
BA_ "U_CX727_MY2021_Tx" SG_ 342 EngClnt_Te_Actl 1;
BA_ "U_P702_MY2021_Tx" SG_ 342 EngClnt_Te_Actl 1;
BA_ "U_T6_MCA_MY2020_Tx" SG_ 342 EngClnt_Te_Actl 1;
BA_ "U_CD542_MY2021_Tx" SG_ 342 EngClnt_Te_Actl 1;
BA_ "U_U55X_MY2022_Tx" SG_ 342 EngClnt_Te_Actl 1;
BA_ "U_CD764_MY2022_Tx" SG_ 342 EngClnt_Te_Actl 1;
BA_ "GenSigStartValueInteger" SG_ 1520 AWD_GWOnBoardTester 255;
BA_ "ContentDependant" SG_ 1520 AWD_GWOnBoardTester 1;
BA_ "GenSigStartValue" SG_ 1520 AWD_GWOnBoardTester 255;
BA_ "U_T6_MCA_MY2020_Tx" SG_ 1520 AWD_GWOnBoardTester 1;
BA_ "GenSigStartValueInteger" SG_ 1520 AWD_GWNMProxy 255;
BA_ "ContentDependant" SG_ 1520 AWD_GWNMProxy 1;
BA_ "GenSigStartValue" SG_ 1520 AWD_GWNMProxy 255;
BA_ "U_T6_MCA_MY2020_Tx" SG_ 1520 AWD_GWNMProxy 1;
BA_ "GenSigStartValueInteger" SG_ 1520 AWD_AutoSarNMReserved4 255;
BA_ "ContentDependant" SG_ 1520 AWD_AutoSarNMReserved4 1;
BA_ "GenSigStartValue" SG_ 1520 AWD_AutoSarNMReserved4 255;
BA_ "U_T6_MCA_MY2020_Tx" SG_ 1520 AWD_AutoSarNMReserved4 1;
BA_ "GenSigStartValueInteger" SG_ 1520 AWD_AutoSarNMReserved3 255;
BA_ "ContentDependant" SG_ 1520 AWD_AutoSarNMReserved3 1;
BA_ "GenSigStartValue" SG_ 1520 AWD_AutoSarNMReserved3 255;
BA_ "U_T6_MCA_MY2020_Tx" SG_ 1520 AWD_AutoSarNMReserved3 1;
BA_ "GenSigStartValueInteger" SG_ 1520 AWD_AutoSarNMReserved2 255;
BA_ "ContentDependant" SG_ 1520 AWD_AutoSarNMReserved2 1;
BA_ "GenSigStartValue" SG_ 1520 AWD_AutoSarNMReserved2 255;
BA_ "U_T6_MCA_MY2020_Tx" SG_ 1520 AWD_AutoSarNMReserved2 1;
BA_ "GenSigStartValueInteger" SG_ 1520 AWD_AutoSarNMReserved1 255;
BA_ "ContentDependant" SG_ 1520 AWD_AutoSarNMReserved1 1;
BA_ "GenSigStartValue" SG_ 1520 AWD_AutoSarNMReserved1 255;
BA_ "U_T6_MCA_MY2020_Tx" SG_ 1520 AWD_AutoSarNMReserved1 1;
BA_ "GenSigStartValueInteger" SG_ 1520 AWD_AutoSarNMNodeId 240;
BA_ "ContentDependant" SG_ 1520 AWD_AutoSarNMNodeId 1;
BA_ "GenSigStartValue" SG_ 1520 AWD_AutoSarNMNodeId 240;
BA_ "U_T6_MCA_MY2020_Tx" SG_ 1520 AWD_AutoSarNMNodeId 1;
BA_ "ContentDependant" SG_ 1520 AWD_AutoSarNMControl 1;
BA_ "U_T6_MCA_MY2020_Tx" SG_ 1520 AWD_AutoSarNMControl 1;
BA_ "U_CX727_MY2021_Rx" SG_ 71 immoTarget1Status 1;
BA_ "U_P702_MY2021_Rx" SG_ 71 immoTarget1Status 1;
BA_ "U_T6_MCA_MY2020_Rx" SG_ 71 immoTarget1Status 1;
BA_ "U_CD542_MY2021_Rx" SG_ 71 immoTarget1Status 1;
BA_ "U_U55X_MY2022_Rx" SG_ 71 immoTarget1Status 1;
BA_ "U_CD764_MY2022_Rx" SG_ 71 immoTarget1Status 1;
BA_ "U_CX727_MY2021_Tx" SG_ 71 immoTarget1Status 1;
BA_ "U_P702_MY2021_Tx" SG_ 71 immoTarget1Status 1;
BA_ "U_T6_MCA_MY2020_Tx" SG_ 71 immoTarget1Status 1;
BA_ "U_CD542_MY2021_Tx" SG_ 71 immoTarget1Status 1;
BA_ "U_U55X_MY2022_Tx" SG_ 71 immoTarget1Status 1;
BA_ "U_CD764_MY2022_Tx" SG_ 71 immoTarget1Status 1;
BA_ "U_CX727_MY2021_Rx" SG_ 71 immoTarget1Data 1;
BA_ "U_P702_MY2021_Rx" SG_ 71 immoTarget1Data 1;
BA_ "U_T6_MCA_MY2020_Rx" SG_ 71 immoTarget1Data 1;
BA_ "U_CD542_MY2021_Rx" SG_ 71 immoTarget1Data 1;
BA_ "U_U55X_MY2022_Rx" SG_ 71 immoTarget1Data 1;
BA_ "U_CD764_MY2022_Rx" SG_ 71 immoTarget1Data 1;
BA_ "U_CX727_MY2021_Tx" SG_ 71 immoTarget1Data 1;
BA_ "U_P702_MY2021_Tx" SG_ 71 immoTarget1Data 1;
BA_ "U_T6_MCA_MY2020_Tx" SG_ 71 immoTarget1Data 1;
BA_ "U_CD542_MY2021_Tx" SG_ 71 immoTarget1Data 1;
BA_ "U_U55X_MY2022_Tx" SG_ 71 immoTarget1Data 1;
BA_ "U_CD764_MY2022_Tx" SG_ 71 immoTarget1Data 1;
BA_ "U_CX727_MY2021_Rx" SG_ 71 immoTarget1Cmd 1;
BA_ "U_P702_MY2021_Rx" SG_ 71 immoTarget1Cmd 1;
BA_ "U_T6_MCA_MY2020_Rx" SG_ 71 immoTarget1Cmd 1;
BA_ "U_CD542_MY2021_Rx" SG_ 71 immoTarget1Cmd 1;
BA_ "U_U55X_MY2022_Rx" SG_ 71 immoTarget1Cmd 1;
BA_ "U_CD764_MY2022_Rx" SG_ 71 immoTarget1Cmd 1;
BA_ "U_CX727_MY2021_Tx" SG_ 71 immoTarget1Cmd 1;
BA_ "U_P702_MY2021_Tx" SG_ 71 immoTarget1Cmd 1;
BA_ "U_T6_MCA_MY2020_Tx" SG_ 71 immoTarget1Cmd 1;
BA_ "U_CD542_MY2021_Tx" SG_ 71 immoTarget1Cmd 1;
BA_ "U_U55X_MY2022_Tx" SG_ 71 immoTarget1Cmd 1;
BA_ "U_CD764_MY2022_Tx" SG_ 71 immoTarget1Cmd 1;
BA_ "GenSigSendType" SG_ 1229 ExitNotClrRight_B_Stat 3;
BA_ "U_U55X_MY2022_Tx" SG_ 1229 ExitNotClrRight_B_Stat 1;
BA_ "U_CD764_MY2022_Tx" SG_ 1229 ExitNotClrRight_B_Stat 1;
BA_ "GenSigSendType" SG_ 1229 ExitNotClrLeft_B_Stat 3;
BA_ "U_U55X_MY2022_Tx" SG_ 1229 ExitNotClrLeft_B_Stat 1;
BA_ "U_CD764_MY2022_Tx" SG_ 1229 ExitNotClrLeft_B_Stat 1;
BA_ "GenSigSendType" SG_ 1238 TjaLc_D_Stat 3;
BA_ "GenSigSendType" SG_ 1238 TjaLcWarn_D_Rq 3;
BA_ "GenSigSendType" SG_ 1238 TjaLcMsgTxt_D_Rq 3;
BA_ "GenSigSendType" SG_ 1238 TjaLcEnbl_D_Stat 3;
BA_ "GenSigSendType" SG_ 1238 TjaCanclMsgTxt_D_Dsply 3;
BA_ "ECGUsedRxSignal" SG_ 1238 TjaCanclMsgTxt_D_Dsply 1;
BA_ "GenSigSendType" SG_ 1238 TjaLaneBiasEnbl_D_Stat 3;
BA_ "GenSigSendType" SG_ 1238 AhbcMnu_D_Rq 3;
BA_ "GenSigSendType" SG_ 1238 GfhbMnu_D_Rq 3;
BA_ "GenSigSendType" SG_ 1238 TjaLaneBias_D_Stat 3;
BA_ "U_U55X_MY2022_Tx" SG_ 1238 TjaLaneBias_D_Stat 1;
BA_ "U_U55X_MY2022_Tx" SG_ 1238 IaccVAdjReas_D_Dsply 1;
BA_ "GenSigSendType" SG_ 1238 IaccVAdjLim_No_Actl 3;
BA_ "U_U55X_MY2022_Tx" SG_ 1238 IaccVAdjLim_No_Actl 1;
BA_ "GenSigSendType" SG_ 2610126880 OTAPhysVDMtoGWM_ECG 3;
BA_ "ECGUsedRxSignal" SG_ 2610126880 OTAPhysVDMtoGWM_ECG 1;
BA_ "U_CD542_MY2021_Rx" SG_ 2610126880 OTAPhysVDMtoGWM_ECG 1;
BA_ "U_T6_MCA_MY2020_Tx" SG_ 2610126880 OTAPhysVDMtoGWM_ECG 1;
BA_ "GenSigSendType" SG_ 2609938648 OTAPhysGWM_ECGtoVDM 3;
BA_ "U_T6_MCA_MY2020_Rx" SG_ 2609938648 OTAPhysGWM_ECGtoVDM 1;
BA_ "ECGUsedTxSignal" SG_ 2609938648 OTAPhysGWM_ECGtoVDM 1;
BA_ "U_CD542_MY2021_Tx" SG_ 2609938648 OTAPhysGWM_ECGtoVDM 1;
BA_ "GenSigSendType" SG_ 2610987224 PARSEDPhysGWM_ECGtoVDM 3;
BA_ "U_T6_MCA_MY2020_Rx" SG_ 2610987224 PARSEDPhysGWM_ECGtoVDM 1;
BA_ "ECGUsedTxSignal" SG_ 2610987224 PARSEDPhysGWM_ECGtoVDM 1;
BA_ "U_CD542_MY2021_Tx" SG_ 2610987224 PARSEDPhysGWM_ECGtoVDM 1;
BA_ "GenSigSendType" SG_ 2611175456 PARSEDPhysVDMtoGWM_ECG 3;
BA_ "ECGUsedRxSignal" SG_ 2611175456 PARSEDPhysVDMtoGWM_ECG 1;
BA_ "U_CD542_MY2021_Rx" SG_ 2611175456 PARSEDPhysVDMtoGWM_ECG 1;
BA_ "U_T6_MCA_MY2020_Tx" SG_ 2611175456 PARSEDPhysVDMtoGWM_ECG 1;
BA_ "GenSigSendType" SG_ 2612035800 PARSEDPushFcGWM_ECGtoVDM 3;
BA_ "U_T6_MCA_MY2020_Rx" SG_ 2612035800 PARSEDPushFcGWM_ECGtoVDM 1;
BA_ "ECGUsedTxSignal" SG_ 2612035800 PARSEDPushFcGWM_ECGtoVDM 1;
BA_ "U_CD542_MY2021_Tx" SG_ 2612035800 PARSEDPushFcGWM_ECGtoVDM 1;
BA_ "GenSigSendType" SG_ 2612224032 PARSEDPushVDMtoGWM_ECG 3;
BA_ "ECGUsedRxSignal" SG_ 2612224032 PARSEDPushVDMtoGWM_ECG 1;
BA_ "U_CD542_MY2021_Rx" SG_ 2612224032 PARSEDPushVDMtoGWM_ECG 1;
BA_ "U_T6_MCA_MY2020_Tx" SG_ 2612224032 PARSEDPushVDMtoGWM_ECG 1;
BA_ "MetaData" SG_ 895 RmtCtlDStat_No_Cs 1;
BA_ "U_U55X_MY2022_Rx" SG_ 895 RmtCtlDStat_No_Cs 1;
BA_ "MetaData" SG_ 895 RmtCtlDStat_No_Cnt 1;
BA_ "U_U55X_MY2022_Rx" SG_ 895 RmtCtlDStat_No_Cnt 1;
BA_ "WakeupSignal" SG_ 895 RmtCtl_D_Stat 1;
BA_ "U_U55X_MY2022_Rx" SG_ 895 RmtCtl_D_Stat 1;
BA_ "GenSigStartValueInteger" SG_ 1092 BattTracMnCell_Te_Actl 254;
BA_ "GenSigStartValue" SG_ 1092 BattTracMnCell_Te_Actl 254;
BA_ "GenSigStartValueInteger" SG_ 1092 BattTracMxCell_Te_Actl 254;
BA_ "GenSigStartValue" SG_ 1092 BattTracMxCell_Te_Actl 254;
BA_ "GenSigStartValueInteger" SG_ 1092 BattTracInsltn_R_Actl 255;
BA_ "GenSigStartValue" SG_ 1092 BattTracInsltn_R_Actl 255;
BA_ "GenSigStartValue" SG_ 1236 ApaSlotRearX_L_Actl 1048;
BA_ "U_U55X_MY2022_Tx" SG_ 1236 ApaSlotRearX_L_Actl 1;
BA_ "GenSigSendType" SG_ 1236 ApaSlotRight3X_L_Actl 3;
BA_ "GenSigStartValue" SG_ 1236 ApaSlotRight3X_L_Actl 1048;
BA_ "U_U55X_MY2022_Tx" SG_ 1236 ApaSlotRight3X_L_Actl 1;
BA_ "GenSigSendType" SG_ 1236 ApaSlotRight3_D_Stat 3;
BA_ "U_U55X_MY2022_Tx" SG_ 1236 ApaSlotRight3_D_Stat 1;
BA_ "GenSigSendType" SG_ 1236 ApaSlotRight3_B_Altr 3;
BA_ "U_U55X_MY2022_Tx" SG_ 1236 ApaSlotRight3_B_Altr 1;
BA_ "GenSigSendType" SG_ 1236 ApaSlotRight2X_L_Actl 3;
BA_ "GenSigStartValue" SG_ 1236 ApaSlotRight2X_L_Actl 1048;
BA_ "U_U55X_MY2022_Tx" SG_ 1236 ApaSlotRight2X_L_Actl 1;
BA_ "GenSigSendType" SG_ 1236 ApaSlotRight2_D_Stat 3;
BA_ "U_U55X_MY2022_Tx" SG_ 1236 ApaSlotRight2_D_Stat 1;
BA_ "GenSigSendType" SG_ 1236 ApaSlotRight2_B_Altr 3;
BA_ "U_U55X_MY2022_Tx" SG_ 1236 ApaSlotRight2_B_Altr 1;
BA_ "GenSigSendType" SG_ 1236 ApaSlotRight1X_L_Actl 3;
BA_ "GenSigStartValue" SG_ 1236 ApaSlotRight1X_L_Actl 1048;
BA_ "U_U55X_MY2022_Tx" SG_ 1236 ApaSlotRight1X_L_Actl 1;
BA_ "GenSigSendType" SG_ 1236 ApaSlotRight1_D_Stat 3;
BA_ "U_U55X_MY2022_Tx" SG_ 1236 ApaSlotRight1_D_Stat 1;
BA_ "GenSigSendType" SG_ 1236 ApaSlotRight1_B_Altr 3;
BA_ "U_U55X_MY2022_Tx" SG_ 1236 ApaSlotRight1_B_Altr 1;
BA_ "GenSigStartValue" SG_ 1236 ApaSlotRearY_L_Actl 32;
BA_ "U_U55X_MY2022_Tx" SG_ 1236 ApaSlotRearY_L_Actl 1;
BA_ "U_U55X_MY2022_Tx" SG_ 1236 ApaSlotRear_D_Stat 1;
BA_ "GenSigSendType" SG_ 1235 ApaSlotFront_D_Stat 3;
BA_ "U_U55X_MY2022_Tx" SG_ 1235 ApaSlotFront_D_Stat 1;
BA_ "GenSigStartValue" SG_ 1235 ApaSlotFrontX_L_Actl 1048;
BA_ "U_U55X_MY2022_Tx" SG_ 1235 ApaSlotFrontX_L_Actl 1;
BA_ "GenSigStartValue" SG_ 1235 ApaSlotFrontY_L_Actl 32;
BA_ "U_U55X_MY2022_Tx" SG_ 1235 ApaSlotFrontY_L_Actl 1;
BA_ "GenSigSendType" SG_ 1235 ApaSlotLeft3X_L_Actl 3;
BA_ "GenSigStartValue" SG_ 1235 ApaSlotLeft3X_L_Actl 1048;
BA_ "U_U55X_MY2022_Tx" SG_ 1235 ApaSlotLeft3X_L_Actl 1;
BA_ "GenSigSendType" SG_ 1235 ApaSlotLeft3_D_Stat 3;
BA_ "U_U55X_MY2022_Tx" SG_ 1235 ApaSlotLeft3_D_Stat 1;
BA_ "GenSigSendType" SG_ 1235 ApaSlotLeft3_B_Altr 3;
BA_ "U_U55X_MY2022_Tx" SG_ 1235 ApaSlotLeft3_B_Altr 1;
BA_ "GenSigSendType" SG_ 1235 ApaSlotLeft2X_L_Actl 3;
BA_ "GenSigStartValue" SG_ 1235 ApaSlotLeft2X_L_Actl 1048;
BA_ "U_U55X_MY2022_Tx" SG_ 1235 ApaSlotLeft2X_L_Actl 1;
BA_ "GenSigSendType" SG_ 1235 ApaSlotLeft2_D_Stat 3;
BA_ "U_U55X_MY2022_Tx" SG_ 1235 ApaSlotLeft2_D_Stat 1;
BA_ "GenSigSendType" SG_ 1235 ApaSlotLeft2_B_Altr 3;
BA_ "U_U55X_MY2022_Tx" SG_ 1235 ApaSlotLeft2_B_Altr 1;
BA_ "GenSigSendType" SG_ 1235 ApaSlotLeft1X_L_Actl 3;
BA_ "GenSigStartValue" SG_ 1235 ApaSlotLeft1X_L_Actl 1048;
BA_ "U_U55X_MY2022_Tx" SG_ 1235 ApaSlotLeft1X_L_Actl 1;
BA_ "GenSigSendType" SG_ 1235 ApaSlotLeft1_D_Stat 3;
BA_ "U_U55X_MY2022_Tx" SG_ 1235 ApaSlotLeft1_D_Stat 1;
BA_ "GenSigSendType" SG_ 1235 ApaSlotLeft1_B_Altr 3;
BA_ "U_U55X_MY2022_Tx" SG_ 1235 ApaSlotLeft1_B_Altr 1;
BA_ "GenSigSendType" SG_ 1234 RmtCtlSnsBlckg_B_Stat 3;
BA_ "U_U55X_MY2022_Tx" SG_ 1234 RmtCtlSnsBlckg_B_Stat 1;
BA_ "GenSigSendType" SG_ 1234 RmtCtlConfgSrc_D_Stat 3;
BA_ "GenSigStartValue" SG_ 1234 RmtCtlConfgSrc_D_Stat 1;
BA_ "U_U55X_MY2022_Tx" SG_ 1234 RmtCtlConfgSrc_D_Stat 1;
BA_ "GenSigSendType" SG_ 1234 RmtCtlTrjctry_D_Avail 3;
BA_ "U_U55X_MY2022_Tx" SG_ 1234 RmtCtlTrjctry_D_Avail 1;
BA_ "GenSigSendType" SG_ 1234 RmtCtlSns_D_Err 3;
BA_ "U_U55X_MY2022_Tx" SG_ 1234 RmtCtlSns_D_Err 1;
BA_ "GenSigSendType" SG_ 1234 RmtCtlPathPlan_D_Stat 3;
BA_ "U_U55X_MY2022_Tx" SG_ 1234 RmtCtlPathPlan_D_Stat 1;
BA_ "GenSigSendType" SG_ 1234 RmtCtlPathPlan_B_Err 3;
BA_ "U_U55X_MY2022_Tx" SG_ 1234 RmtCtlPathPlan_B_Err 1;
BA_ "GenSigSendType" SG_ 1234 RmtCtlAdas_D_Stat 3;
BA_ "U_U55X_MY2022_Tx" SG_ 1234 RmtCtlAdas_D_Stat 1;
BA_ "GenSigSendType" SG_ 1234 RmtCtlAdas_B_Err 3;
BA_ "U_U55X_MY2022_Tx" SG_ 1234 RmtCtlAdas_B_Err 1;
BA_ "GenSigSendType" SG_ 1233 FreeDrvRear_D_Avail 3;
BA_ "U_U55X_MY2022_Tx" SG_ 1233 FreeDrvRear_D_Avail 1;
BA_ "GenSigSendType" SG_ 1233 FreeDrvFwd_D_Avail 3;
BA_ "U_U55X_MY2022_Tx" SG_ 1233 FreeDrvFwd_D_Avail 1;
BA_ "GenSigSendType" SG_ 1233 RmtCtlTrgDist_D_Stat 3;
BA_ "U_U55X_MY2022_Tx" SG_ 1233 RmtCtlTrgDist_D_Stat 1;
BA_ "GenSigSendType" SG_ 1233 RmtCtlSnsRrCrnr_D_Stat 3;
BA_ "U_U55X_MY2022_Tx" SG_ 1233 RmtCtlSnsRrCrnr_D_Stat 1;
BA_ "GenSigSendType" SG_ 1233 RmtCtlSnsRlCrnr_D_Stat 3;
BA_ "U_U55X_MY2022_Tx" SG_ 1233 RmtCtlSnsRlCrnr_D_Stat 1;
BA_ "GenSigSendType" SG_ 1233 RmtCtlSnsRear_D_Stat 3;
BA_ "U_U55X_MY2022_Tx" SG_ 1233 RmtCtlSnsRear_D_Stat 1;
BA_ "GenSigSendType" SG_ 1233 RmtCtlSnsFront_D_Stat 3;
BA_ "U_U55X_MY2022_Tx" SG_ 1233 RmtCtlSnsFront_D_Stat 1;
BA_ "GenSigSendType" SG_ 1233 RmtCtlSnsFrCrnr_D_Stat 3;
BA_ "U_U55X_MY2022_Tx" SG_ 1233 RmtCtlSnsFrCrnr_D_Stat 1;
BA_ "GenSigSendType" SG_ 1233 RmtCtlSnsFlCrnr_D_Stat 3;
BA_ "U_U55X_MY2022_Tx" SG_ 1233 RmtCtlSnsFlCrnr_D_Stat 1;
BA_ "GenSigSendType" SG_ 1233 RmtCtlSideSnsR4_D_Stat 3;
BA_ "U_U55X_MY2022_Tx" SG_ 1233 RmtCtlSideSnsR4_D_Stat 1;
BA_ "GenSigSendType" SG_ 1233 RmtCtlSideSnsR3_D_Stat 3;
BA_ "U_U55X_MY2022_Tx" SG_ 1233 RmtCtlSideSnsR3_D_Stat 1;
BA_ "GenSigSendType" SG_ 1233 RmtCtlSideSnsR2_D_Stat 3;
BA_ "U_U55X_MY2022_Tx" SG_ 1233 RmtCtlSideSnsR2_D_Stat 1;
BA_ "GenSigSendType" SG_ 1233 RmtCtlSideSnsR1_D_Stat 3;
BA_ "U_U55X_MY2022_Tx" SG_ 1233 RmtCtlSideSnsR1_D_Stat 1;
BA_ "GenSigSendType" SG_ 1233 RmtCtlSideSnsL4_D_Stat 3;
BA_ "U_U55X_MY2022_Tx" SG_ 1233 RmtCtlSideSnsL4_D_Stat 1;
BA_ "GenSigSendType" SG_ 1233 RmtCtlSideSnsL3_D_Stat 3;
BA_ "U_U55X_MY2022_Tx" SG_ 1233 RmtCtlSideSnsL3_D_Stat 1;
BA_ "GenSigSendType" SG_ 1233 RmtCtlSideSnsL2_D_Stat 3;
BA_ "U_U55X_MY2022_Tx" SG_ 1233 RmtCtlSideSnsL2_D_Stat 1;
BA_ "GenSigSendType" SG_ 1233 RmtCtlSideSnsL1_D_Stat 3;
BA_ "U_U55X_MY2022_Tx" SG_ 1233 RmtCtlSideSnsL1_D_Stat 1;
BA_ "GenSigSendType" SG_ 1233 RmtCtlRightOrnt_D_Avail 3;
BA_ "U_U55X_MY2022_Tx" SG_ 1233 RmtCtlRightOrnt_D_Avail 1;
BA_ "GenSigSendType" SG_ 1233 RmtCtlRight_D_Avail 3;
BA_ "U_U55X_MY2022_Tx" SG_ 1233 RmtCtlRight_D_Avail 1;
BA_ "GenSigSendType" SG_ 1233 RmtCtlRear_D_Avail 3;
BA_ "U_U55X_MY2022_Tx" SG_ 1233 RmtCtlRear_D_Avail 1;
BA_ "GenSigSendType" SG_ 1233 RmtCtlPrkMde_D_Stat 3;
BA_ "U_U55X_MY2022_Tx" SG_ 1233 RmtCtlPrkMde_D_Stat 1;
BA_ "GenSigSendType" SG_ 1233 RmtCtlPrkInSlot_D_Stat 3;
BA_ "U_U55X_MY2022_Tx" SG_ 1233 RmtCtlPrkInSlot_D_Stat 1;
BA_ "GenSigSendType" SG_ 1233 RmtCtlObstcl_B_Stat 3;
BA_ "U_U55X_MY2022_Tx" SG_ 1233 RmtCtlObstcl_B_Stat 1;
BA_ "GenSigSendType" SG_ 1233 RmtCtlNxtMoveDir_D_Stat 3;
BA_ "U_U55X_MY2022_Tx" SG_ 1233 RmtCtlNxtMoveDir_D_Stat 1;
BA_ "GenSigSendType" SG_ 1233 RmtCtlMoveDir_D_Stat 3;
BA_ "U_U55X_MY2022_Tx" SG_ 1233 RmtCtlMoveDir_D_Stat 1;
BA_ "GenSigSendType" SG_ 1233 RmtCtlLeftOrnt_D_Avail 3;
BA_ "U_U55X_MY2022_Tx" SG_ 1233 RmtCtlLeftOrnt_D_Avail 1;
BA_ "GenSigSendType" SG_ 1233 RmtCtlLeft_D_Avail 3;
BA_ "U_U55X_MY2022_Tx" SG_ 1233 RmtCtlLeft_D_Avail 1;
BA_ "GenSigSendType" SG_ 1233 RmtCtlFront_D_Avail 3;
BA_ "U_U55X_MY2022_Tx" SG_ 1233 RmtCtlFront_D_Avail 1;
BA_ "GenSigSendType" SG_ 1237 ApaSlotRef2Y_L_Actl 3;
BA_ "U_U55X_MY2022_Tx" SG_ 1237 ApaSlotRef2Y_L_Actl 1;
BA_ "GenSigSendType" SG_ 1237 ApaSlotRef2X_L_Actl 3;
BA_ "U_U55X_MY2022_Tx" SG_ 1237 ApaSlotRef2X_L_Actl 1;
BA_ "GenSigSendType" SG_ 1237 ApaSlotRef1Y_L_Actl 3;
BA_ "U_U55X_MY2022_Tx" SG_ 1237 ApaSlotRef1Y_L_Actl 1;
BA_ "GenSigSendType" SG_ 1237 ApaSlotRef1X_L_Actl 3;
BA_ "U_U55X_MY2022_Tx" SG_ 1237 ApaSlotRef1X_L_Actl 1;
BA_ "GenSigStartValue" SG_ 1149 BattTracPerf_Pc_Dsply 254;
BA_ "GenSigStartValue" SG_ 1149 BattTracPerf_Pc_Actl 254;
BA_ "GenSigStartValueInteger" SG_ 1436 IPMA_GWOnBoardTester 255;
BA_ "ContentDependant" SG_ 1436 IPMA_GWOnBoardTester 1;
BA_ "GenSigStartValue" SG_ 1436 IPMA_GWOnBoardTester 255;
BA_ "U_U55X_MY2022_Tx" SG_ 1436 IPMA_GWOnBoardTester 1;
BA_ "GenSigStartValueInteger" SG_ 1436 IPMA_GWNMProxy 255;
BA_ "ContentDependant" SG_ 1436 IPMA_GWNMProxy 1;
BA_ "GenSigStartValue" SG_ 1436 IPMA_GWNMProxy 255;
BA_ "U_U55X_MY2022_Tx" SG_ 1436 IPMA_GWNMProxy 1;
BA_ "GenSigStartValueInteger" SG_ 1436 IPMA_AutoSarNMReserved4 255;
BA_ "ContentDependant" SG_ 1436 IPMA_AutoSarNMReserved4 1;
BA_ "GenSigStartValue" SG_ 1436 IPMA_AutoSarNMReserved4 255;
BA_ "U_U55X_MY2022_Tx" SG_ 1436 IPMA_AutoSarNMReserved4 1;
BA_ "GenSigStartValueInteger" SG_ 1436 IPMA_AutoSarNMReserved3 255;
BA_ "ContentDependant" SG_ 1436 IPMA_AutoSarNMReserved3 1;
BA_ "GenSigStartValue" SG_ 1436 IPMA_AutoSarNMReserved3 255;
BA_ "U_U55X_MY2022_Tx" SG_ 1436 IPMA_AutoSarNMReserved3 1;
BA_ "GenSigStartValueInteger" SG_ 1436 IPMA_AutoSarNMReserved2 255;
BA_ "ContentDependant" SG_ 1436 IPMA_AutoSarNMReserved2 1;
BA_ "GenSigStartValue" SG_ 1436 IPMA_AutoSarNMReserved2 255;
BA_ "U_U55X_MY2022_Tx" SG_ 1436 IPMA_AutoSarNMReserved2 1;
BA_ "GenSigStartValueInteger" SG_ 1436 IPMA_AutoSarNMReserved1 255;
BA_ "ContentDependant" SG_ 1436 IPMA_AutoSarNMReserved1 1;
BA_ "GenSigStartValue" SG_ 1436 IPMA_AutoSarNMReserved1 255;
BA_ "U_U55X_MY2022_Tx" SG_ 1436 IPMA_AutoSarNMReserved1 1;
BA_ "GenSigStartValueInteger" SG_ 1436 IPMA_AutoSarNMNodeId 145;
BA_ "ContentDependant" SG_ 1436 IPMA_AutoSarNMNodeId 1;
BA_ "GenSigStartValue" SG_ 1436 IPMA_AutoSarNMNodeId 156;
BA_ "U_U55X_MY2022_Tx" SG_ 1436 IPMA_AutoSarNMNodeId 1;
BA_ "ContentDependant" SG_ 1436 IPMA_AutoSarNMControl 1;
BA_ "U_U55X_MY2022_Tx" SG_ 1436 IPMA_AutoSarNMControl 1;
BA_ "GenSigStartValueInteger" SG_ 788 EcoCochDecel2_Pc_Dsply 255;
BA_ "GenSigStartValue" SG_ 788 EcoCochDecel2_Pc_Dsply 255;
BA_ "U_T6_MCA_MY2020_Tx" SG_ 788 EcoCochDecel2_Pc_Dsply 1;
BA_ "U_CD764_MY2022_Tx" SG_ 788 EcoCochDecel2_Pc_Dsply 1;
BA_ "GenSigStartValueInteger" SG_ 788 EcoCochDecel1_Pc_Dsply 255;
BA_ "GenSigStartValue" SG_ 788 EcoCochDecel1_Pc_Dsply 255;
BA_ "U_T6_MCA_MY2020_Tx" SG_ 788 EcoCochDecel1_Pc_Dsply 1;
BA_ "U_CD764_MY2022_Tx" SG_ 788 EcoCochDecel1_Pc_Dsply 1;
BA_ "GenSigStartValueInteger" SG_ 788 EcoCochCrus2_Pc_Dsply 255;
BA_ "GenSigStartValue" SG_ 788 EcoCochCrus2_Pc_Dsply 255;
BA_ "U_T6_MCA_MY2020_Tx" SG_ 788 EcoCochCrus2_Pc_Dsply 1;
BA_ "U_CD764_MY2022_Tx" SG_ 788 EcoCochCrus2_Pc_Dsply 1;
BA_ "GenSigStartValueInteger" SG_ 788 EcoCochCrus1_Pc_Dsply 255;
BA_ "GenSigStartValue" SG_ 788 EcoCochCrus1_Pc_Dsply 255;
BA_ "U_T6_MCA_MY2020_Tx" SG_ 788 EcoCochCrus1_Pc_Dsply 1;
BA_ "U_CD764_MY2022_Tx" SG_ 788 EcoCochCrus1_Pc_Dsply 1;
BA_ "GenSigStartValueInteger" SG_ 788 EcoCochATrip2_Pc_Dsply 255;
BA_ "GenSigStartValue" SG_ 788 EcoCochATrip2_Pc_Dsply 255;
BA_ "U_T6_MCA_MY2020_Tx" SG_ 788 EcoCochATrip2_Pc_Dsply 1;
BA_ "U_CD764_MY2022_Tx" SG_ 788 EcoCochATrip2_Pc_Dsply 1;
BA_ "GenSigStartValueInteger" SG_ 788 EcoCochATrip1_Pc_Dsply 255;
BA_ "GenSigStartValue" SG_ 788 EcoCochATrip1_Pc_Dsply 255;
BA_ "U_T6_MCA_MY2020_Tx" SG_ 788 EcoCochATrip1_Pc_Dsply 1;
BA_ "U_CD764_MY2022_Tx" SG_ 788 EcoCochATrip1_Pc_Dsply 1;
BA_ "GenSigSendType" SG_ 824 DteCldCompltRoute_B_Rq 3;
BA_ "ECGUsedTxSignal" SG_ 824 DteCldCompltRoute_B_Rq 1;
BA_ "U_CD542_MY2021_Tx" SG_ 824 DteCldCompltRoute_B_Rq 1;
BA_ "GenSigSendType" SG_ 824 DteCldTrlrOn_B_Stat 3;
BA_ "ECGUsedTxSignal" SG_ 824 DteCldTrlrOn_B_Stat 1;
BA_ "U_CD542_MY2021_Tx" SG_ 824 DteCldTrlrOn_B_Stat 1;
BA_ "U_U55X_MY2022_Tx" SG_ 824 DteCldTrlrOn_B_Stat 1;
BA_ "GenSigSendType" SG_ 824 DteCldTrlrOff_B_Stat 3;
BA_ "ECGUsedTxSignal" SG_ 824 DteCldTrlrOff_B_Stat 1;
BA_ "U_CD542_MY2021_Tx" SG_ 824 DteCldTrlrOff_B_Stat 1;
BA_ "U_U55X_MY2022_Tx" SG_ 824 DteCldTrlrOff_B_Stat 1;
BA_ "GenSigSendType" SG_ 824 DteCldTraffic_B_Stat 3;
BA_ "ECGUsedTxSignal" SG_ 824 DteCldTraffic_B_Stat 1;
BA_ "U_CD542_MY2021_Tx" SG_ 824 DteCldTraffic_B_Stat 1;
BA_ "U_U55X_MY2022_Tx" SG_ 824 DteCldTraffic_B_Stat 1;
BA_ "GenSigSendType" SG_ 824 DteCldTerrain_B_Stat 3;
BA_ "ECGUsedTxSignal" SG_ 824 DteCldTerrain_B_Stat 1;
BA_ "U_CD542_MY2021_Tx" SG_ 824 DteCldTerrain_B_Stat 1;
BA_ "U_U55X_MY2022_Tx" SG_ 824 DteCldTerrain_B_Stat 1;
BA_ "GenSigSendType" SG_ 824 DteCldRoute_B_Stat 3;
BA_ "ECGUsedTxSignal" SG_ 824 DteCldRoute_B_Stat 1;
BA_ "U_CD542_MY2021_Tx" SG_ 824 DteCldRoute_B_Stat 1;
BA_ "U_U55X_MY2022_Tx" SG_ 824 DteCldRoute_B_Stat 1;
BA_ "GenSigSendType" SG_ 824 DteCldPayload_B_Stat 3;
BA_ "ECGUsedTxSignal" SG_ 824 DteCldPayload_B_Stat 1;
BA_ "U_CD542_MY2021_Tx" SG_ 824 DteCldPayload_B_Stat 1;
BA_ "U_U55X_MY2022_Tx" SG_ 824 DteCldPayload_B_Stat 1;
BA_ "GenSigSendType" SG_ 824 DteCldId_No_Actl 3;
BA_ "ECGUsedTxSignal" SG_ 824 DteCldId_No_Actl 1;
BA_ "U_CD542_MY2021_Tx" SG_ 824 DteCldId_No_Actl 1;
BA_ "U_U55X_MY2022_Tx" SG_ 824 DteCldId_No_Actl 1;
BA_ "GenSigSendType" SG_ 824 DteCldExtTe_B_Stat 3;
BA_ "ECGUsedTxSignal" SG_ 824 DteCldExtTe_B_Stat 1;
BA_ "U_CD542_MY2021_Tx" SG_ 824 DteCldExtTe_B_Stat 1;
BA_ "U_U55X_MY2022_Tx" SG_ 824 DteCldExtTe_B_Stat 1;
BA_ "GenSigStartValue" SG_ 824 DteCldExt_Eff_Actl 100;
BA_ "ECGUsedTxSignal" SG_ 824 DteCldExt_Eff_Actl 1;
BA_ "U_CD542_MY2021_Tx" SG_ 824 DteCldExt_Eff_Actl 1;
BA_ "U_U55X_MY2022_Tx" SG_ 824 DteCldExt_Eff_Actl 1;
BA_ "GenSigStartValue" SG_ 824 DteCldDrv_Eff_Actl 100;
BA_ "ECGUsedTxSignal" SG_ 824 DteCldDrv_Eff_Actl 1;
BA_ "U_CD542_MY2021_Tx" SG_ 824 DteCldDrv_Eff_Actl 1;
BA_ "U_U55X_MY2022_Tx" SG_ 824 DteCldDrv_Eff_Actl 1;
BA_ "GenSigSendType" SG_ 824 DteCldDcac_B_Stat 3;
BA_ "ECGUsedTxSignal" SG_ 824 DteCldDcac_B_Stat 1;
BA_ "U_CD542_MY2021_Tx" SG_ 824 DteCldDcac_B_Stat 1;
BA_ "U_U55X_MY2022_Tx" SG_ 824 DteCldDcac_B_Stat 1;
BA_ "GenSigStartValue" SG_ 824 DteCldClimt_Eff_Actl 100;
BA_ "ECGUsedTxSignal" SG_ 824 DteCldClimt_Eff_Actl 1;
BA_ "U_CD542_MY2021_Tx" SG_ 824 DteCldClimt_Eff_Actl 1;
BA_ "U_U55X_MY2022_Tx" SG_ 824 DteCldClimt_Eff_Actl 1;
BA_ "GenSigStartValue" SG_ 824 DteCldBattULo_Eff_Actl 100;
BA_ "ECGUsedTxSignal" SG_ 824 DteCldBattULo_Eff_Actl 1;
BA_ "U_CD542_MY2021_Tx" SG_ 824 DteCldBattULo_Eff_Actl 1;
BA_ "U_U55X_MY2022_Tx" SG_ 824 DteCldBattULo_Eff_Actl 1;
BA_ "GenSigStartValue" SG_ 824 DteCldTrip_L2_Actl 8190;
BA_ "ECGUsedTxSignal" SG_ 824 DteCldTrip_L2_Actl 1;
BA_ "U_CD542_MY2021_Tx" SG_ 824 DteCldTrip_L2_Actl 1;
BA_ "U_U55X_MY2022_Tx" SG_ 824 DteCldTrip_L2_Actl 1;
BA_ "GenSigStartValue" SG_ 811 ScMnSoc_Pc_RqMnu 126;
BA_ "U_T6_MCA_MY2020_Rx" SG_ 811 OnePdlDrvButtn_B_Falt 1;
BA_ "U_T6_MCA_MY2020_Rx" SG_ 811 OnePdlDrvButtn_B_Stat 1;
BA_ "GenSigStartValue" SG_ 811 DistToStopover_L_Actl 65535;
BA_ "WakeupSignal" SG_ 811 ExtLghtRight_D_RqMnu 1;
BA_ "WakeupSignal" SG_ 811 AutoLghtOvrrd_B_RqDrv 1;
BA_ "WakeupSignal" SG_ 811 ExtLghtRear_D_RqMnu 1;
BA_ "WakeupSignal" SG_ 811 ExtLghtLeft_D_RqMnu 1;
BA_ "WakeupSignal" SG_ 811 ExtLghtFront_D_RqMnu 1;
BA_ "GenSigStartValue" SG_ 811 GoTEditMnte_T_RqMnu 14;
BA_ "GenSigStartValue" SG_ 811 GoTEditHr_T_RqMnu 30;
BA_ "WakeupSignal" SG_ 811 BecRleas_No_RqMnu 1;
BA_ "WakeupSignal" SG_ 811 TrnkFrontRleas_No_RqMnu 1;
BA_ "GenSigSendType" SG_ 942 ApaOffOptnSel_B_Avail 3;
BA_ "GenSigStartValue" SG_ 942 ApaOffOptnSel_B_Avail 1;
BA_ "U_U55X_MY2022_Tx" SG_ 942 ApaOffOptnSel_B_Avail 1;
BA_ "GenSigSendType" SG_ 942 PrkBrkElRleas_B_RqApa 3;
BA_ "U_CD764_MY2022_Tx" SG_ 942 PrkBrkElRleas_B_RqApa 1;
BA_ "GenSigSendType" SG_ 942 ApaDrvRq2MsgTxt_D_Rq 3;
BA_ "U_U55X_MY2022_Tx" SG_ 942 ApaDrvRq2MsgTxt_D_Rq 1;
BA_ "GenSigSendType" SG_ 942 ApaDrvRq1MsgTxt_D_Rq 3;
BA_ "U_U55X_MY2022_Tx" SG_ 942 ApaDrvRq1MsgTxt_D_Rq 1;
BA_ "GenSigSendType" SG_ 942 ApaSys_D2_Stat 3;
BA_ "U_U55X_MY2022_Tx" SG_ 942 ApaSys_D2_Stat 1;
BA_ "GenSigSendType" SG_ 942 ApaSlotTrgt_D_Stat 3;
BA_ "U_U55X_MY2022_Tx" SG_ 942 ApaSlotTrgt_D_Stat 1;
BA_ "GenSigSendType" SG_ 942 ApaSlotOption_B_Avail 3;
BA_ "U_U55X_MY2022_Tx" SG_ 942 ApaSlotOption_B_Avail 1;
BA_ "GenSigSendType" SG_ 942 ApaSlotAlrtSet_B_Stat 3;
BA_ "U_U55X_MY2022_Tx" SG_ 942 ApaSlotAlrtSet_B_Stat 1;
BA_ "GenSigSendType" SG_ 942 ApaSlotAlrt_B_Rq 3;
BA_ "U_U55X_MY2022_Tx" SG_ 942 ApaSlotAlrt_B_Rq 1;
BA_ "GenSigSendType" SG_ 942 ApaRmtFeatSel_B_Avail 3;
BA_ "U_U55X_MY2022_Tx" SG_ 942 ApaRmtFeatSel_B_Avail 1;
BA_ "GenSigSendType" SG_ 942 ApaParkOutSel_B_Avail 3;
BA_ "U_U55X_MY2022_Tx" SG_ 942 ApaParkOutSel_B_Avail 1;
BA_ "GenSigSendType" SG_ 942 ApaParkInSel_B_Avail 3;
BA_ "U_U55X_MY2022_Tx" SG_ 942 ApaParkInSel_B_Avail 1;
BA_ "GenSigSendType" SG_ 942 ApaMsgTxt_D2_Stat 3;
BA_ "U_U55X_MY2022_Tx" SG_ 942 ApaMsgTxt_D2_Stat 1;
BA_ "GenSigSendType" SG_ 942 ApaDynmcSlot_B_Stat 3;
BA_ "U_U55X_MY2022_Tx" SG_ 942 ApaDynmcSlot_B_Stat 1;
BA_ "GenSigSendType" SG_ 942 ApaDisplayMode_D_Stat 3;
BA_ "U_U55X_MY2022_Tx" SG_ 942 ApaDisplayMode_D_Stat 1;
BA_ "GenSigSendType" SG_ 942 ApaControlMode_D_Stat 3;
BA_ "U_U55X_MY2022_Tx" SG_ 942 ApaControlMode_D_Stat 1;
BA_ "GenSigSendType" SG_ 942 PrkAidAcsyRear_D_Stat 3;
BA_ "U_T6_MCA_MY2020_Tx" SG_ 942 PrkAidAcsyRear_D_Stat 1;
BA_ "U_U55X_MY2022_Tx" SG_ 942 PrkAidAcsyRear_D_Stat 1;
BA_ "U_CD764_MY2022_Tx" SG_ 942 PrkAidAcsyRear_D_Stat 1;
BA_ "GenSigSendType" SG_ 942 PrkAidAcsyFront_D_Stat 3;
BA_ "U_T6_MCA_MY2020_Tx" SG_ 942 PrkAidAcsyFront_D_Stat 1;
BA_ "U_U55X_MY2022_Tx" SG_ 942 PrkAidAcsyFront_D_Stat 1;
BA_ "GenSigSendType" SG_ 942 PrkAidRdiusRight_L_Dsply 3;
BA_ "U_T6_MCA_MY2020_Tx" SG_ 942 PrkAidRdiusRight_L_Dsply 1;
BA_ "U_U55X_MY2022_Tx" SG_ 942 PrkAidRdiusRight_L_Dsply 1;
BA_ "U_CD764_MY2022_Tx" SG_ 942 PrkAidRdiusRight_L_Dsply 1;
BA_ "GenSigSendType" SG_ 942 PrkAidRdiusLeft_L_Dsply 3;
BA_ "U_T6_MCA_MY2020_Tx" SG_ 942 PrkAidRdiusLeft_L_Dsply 1;
BA_ "U_U55X_MY2022_Tx" SG_ 942 PrkAidRdiusLeft_L_Dsply 1;
BA_ "U_CD764_MY2022_Tx" SG_ 942 PrkAidRdiusLeft_L_Dsply 1;
BA_ "GenSigSendType" SG_ 942 PrkAidDrvDir_D_Stat 3;
BA_ "U_T6_MCA_MY2020_Tx" SG_ 942 PrkAidDrvDir_D_Stat 1;
BA_ "U_U55X_MY2022_Tx" SG_ 942 PrkAidDrvDir_D_Stat 1;
BA_ "U_CD764_MY2022_Tx" SG_ 942 PrkAidDrvDir_D_Stat 1;
BA_ "GenSigStartValueInteger" SG_ 123 BattTrac_U2_Actl 1022;
BA_ "GenSigStartValue" SG_ 123 BattTrac_U2_Actl 4094;
BA_ "GenSigStartValueInteger" SG_ 123 BattTrac_I2_Actl 15000;
BA_ "GenSigStartValue" SG_ 123 BattTrac_I2_Actl 262142;
BA_ "GenSigSendType" SG_ 2612052184 PARSEDPushFcGWM_ECGtoPSCM 3;
BA_ "U_CD542_MY2021_Rx" SG_ 2612052184 PARSEDPushFcGWM_ECGtoPSCM 1;
BA_ "U_U55X_MY2022_Rx" SG_ 2612052184 PARSEDPushFcGWM_ECGtoPSCM 1;
BA_ "U_CD764_MY2022_Rx" SG_ 2612052184 PARSEDPushFcGWM_ECGtoPSCM 1;
BA_ "ECGUsedTxSignal" SG_ 2612052184 PARSEDPushFcGWM_ECGtoPSCM 1;
BA_ "U_CD542_MY2021_Tx" SG_ 2612052184 PARSEDPushFcGWM_ECGtoPSCM 1;
BA_ "U_U55X_MY2022_Tx" SG_ 2612052184 PARSEDPushFcGWM_ECGtoPSCM 1;
BA_ "U_CD764_MY2022_Tx" SG_ 2612052184 PARSEDPushFcGWM_ECGtoPSCM 1;
BA_ "GenSigSendType" SG_ 2612224187 PARSEDPushCMRtoGWM_ECG 3;
BA_ "U_T6_MCA_MY2020_Rx" SG_ 2612224187 PARSEDPushCMRtoGWM_ECG 1;
BA_ "ECGUsedRxSignal" SG_ 2612224187 PARSEDPushCMRtoGWM_ECG 1;
BA_ "U_CD542_MY2021_Rx" SG_ 2612224187 PARSEDPushCMRtoGWM_ECG 1;
BA_ "U_U55X_MY2022_Rx" SG_ 2612224187 PARSEDPushCMRtoGWM_ECG 1;
BA_ "U_T6_MCA_MY2020_Tx" SG_ 2612224187 PARSEDPushCMRtoGWM_ECG 1;
BA_ "U_CD542_MY2021_Tx" SG_ 2612224187 PARSEDPushCMRtoGWM_ECG 1;
BA_ "U_U55X_MY2022_Tx" SG_ 2612224187 PARSEDPushCMRtoGWM_ECG 1;
BA_ "U_CD764_MY2022_Tx" SG_ 2612224187 PARSEDPushCMRtoGWM_ECG 1;
BA_ "GenSigSendType" SG_ 1239 CstmDrvMdeTracCtl_D_Rq 3;
BA_ "ECGUsedTxSignal" SG_ 1239 CstmDrvMdeTracCtl_D_Rq 1;
BA_ "GenSigSendType" SG_ 1239 CstmDrvMdeChassis_D_Rq 3;
BA_ "ECGUsedTxSignal" SG_ 1239 CstmDrvMdeChassis_D_Rq 1;
BA_ "GenSigSendType" SG_ 1239 CstmDrvMdeHmi2_D_Rq 3;
BA_ "GenSigStartValueInteger" SG_ 1239 CstmDrvMdeHmi2_D_Rq 31;
BA_ "GenSigStartValue" SG_ 1239 CstmDrvMdeHmi2_D_Rq 31;
BA_ "ECGUsedTxSignal" SG_ 1239 CstmDrvMdeHmi2_D_Rq 1;
BA_ "GenSigSendType" SG_ 1239 SelDrvMdeCstmLamp_D_Rq 3;
BA_ "ECGUsedTxSignal" SG_ 1239 SelDrvMdeCstmLamp_D_Rq 1;
BA_ "U_CD542_MY2021_Tx" SG_ 1239 SelDrvMdeCstmLamp_D_Rq 1;
BA_ "U_CD764_MY2022_Tx" SG_ 1239 SelDrvMdeCstmLamp_D_Rq 1;
BA_ "GenSigSendType" SG_ 1239 SelDrvMdeCstm_D_RqDrv 3;
BA_ "ECGUsedTxSignal" SG_ 1239 SelDrvMdeCstm_D_RqDrv 1;
BA_ "U_CD542_MY2021_Tx" SG_ 1239 SelDrvMdeCstm_D_RqDrv 1;
BA_ "U_CD764_MY2022_Tx" SG_ 1239 SelDrvMdeCstm_D_RqDrv 1;
BA_ "GenSigSendType" SG_ 1239 StabBarCnnctLamp_D_Cstm 3;
BA_ "ECGUsedTxSignal" SG_ 1239 StabBarCnnctLamp_D_Cstm 1;
BA_ "U_CD542_MY2021_Tx" SG_ 1239 StabBarCnnctLamp_D_Cstm 1;
BA_ "U_CD764_MY2022_Tx" SG_ 1239 StabBarCnnctLamp_D_Cstm 1;
BA_ "GenSigSendType" SG_ 1239 IndvMdeSuspCstm_No_Rq 3;
BA_ "GenSigStartValue" SG_ 1239 IndvMdeSuspCstm_No_Rq 15;
BA_ "ECGUsedTxSignal" SG_ 1239 IndvMdeSuspCstm_No_Rq 1;
BA_ "U_CD542_MY2021_Tx" SG_ 1239 IndvMdeSuspCstm_No_Rq 1;
BA_ "U_CD764_MY2022_Tx" SG_ 1239 IndvMdeSuspCstm_No_Rq 1;
BA_ "GenSigSendType" SG_ 1239 IndvMdeSteCstm_No_Rq 3;
BA_ "GenSigStartValue" SG_ 1239 IndvMdeSteCstm_No_Rq 15;
BA_ "ECGUsedTxSignal" SG_ 1239 IndvMdeSteCstm_No_Rq 1;
BA_ "U_CD542_MY2021_Tx" SG_ 1239 IndvMdeSteCstm_No_Rq 1;
BA_ "U_CD764_MY2022_Tx" SG_ 1239 IndvMdeSteCstm_No_Rq 1;
BA_ "GenSigSendType" SG_ 1239 CstmDrvMdeMsgTxt_D_Rq 3;
BA_ "ECGUsedTxSignal" SG_ 1239 CstmDrvMdeMsgTxt_D_Rq 1;
BA_ "U_CD542_MY2021_Tx" SG_ 1239 CstmDrvMdeMsgTxt_D_Rq 1;
BA_ "U_CD764_MY2022_Tx" SG_ 1239 CstmDrvMdeMsgTxt_D_Rq 1;
BA_ "GenSigSendType" SG_ 1239 ActvDrvMdeCstm_D2_Rq 3;
BA_ "GenSigStartValue" SG_ 1239 ActvDrvMdeCstm_D2_Rq 31;
BA_ "ECGUsedTxSignal" SG_ 1239 ActvDrvMdeCstm_D2_Rq 1;
BA_ "U_CD542_MY2021_Tx" SG_ 1239 ActvDrvMdeCstm_D2_Rq 1;
BA_ "U_CD764_MY2022_Tx" SG_ 1239 ActvDrvMdeCstm_D2_Rq 1;
BA_ "GenSigStartValueInteger" SG_ 949 Tire_Press_RR_ORR_Data 65533;
BA_ "GenSigStartValue" SG_ 949 Tire_Press_RR_ORR_Data 65533;
BA_ "U_T6_MCA_MY2020_Rx" SG_ 949 Tire_Press_RR_ORR_Data 1;
BA_ "GenSigStartValueInteger" SG_ 949 Tire_Press_LR_OLR_Data 65533;
BA_ "GenSigStartValue" SG_ 949 Tire_Press_LR_OLR_Data 65533;
BA_ "U_T6_MCA_MY2020_Rx" SG_ 949 Tire_Press_LR_OLR_Data 1;
BA_ "GenSigStartValueInteger" SG_ 949 Tire_Press_LF_Data 65533;
BA_ "GenSigStartValue" SG_ 949 Tire_Press_LF_Data 65533;
BA_ "U_T6_MCA_MY2020_Rx" SG_ 949 Tire_Press_LF_Data 1;
BA_ "GenSigStartValueInteger" SG_ 949 Tire_Press_RF_Data 65533;
BA_ "GenSigStartValue" SG_ 949 Tire_Press_RF_Data 65533;
BA_ "U_T6_MCA_MY2020_Rx" SG_ 949 Tire_Press_RF_Data 1;
BA_ "GenSigSendType" SG_ 2612074712 PARSEDPushFcGWMtoSODCMD 3;
BA_ "U_T6_MCA_MY2020_Rx" SG_ 2612074712 PARSEDPushFcGWMtoSODCMD 1;
BA_ "U_U55X_MY2022_Rx" SG_ 2612074712 PARSEDPushFcGWMtoSODCMD 1;
BA_ "U_T6_MCA_MY2020_Tx" SG_ 2612074712 PARSEDPushFcGWMtoSODCMD 1;
BA_ "ECGUsedTxSignal" SG_ 2612074712 PARSEDPushFcGWMtoSODCMD 1;
BA_ "U_CD542_MY2021_Tx" SG_ 2612074712 PARSEDPushFcGWMtoSODCMD 1;
BA_ "U_U55X_MY2022_Tx" SG_ 2612074712 PARSEDPushFcGWMtoSODCMD 1;
BA_ "GenSigSendType" SG_ 2612024536 PARSEDPushFcGWM_ECGtoCCM 3;
BA_ "U_T6_MCA_MY2020_Rx" SG_ 2612024536 PARSEDPushFcGWM_ECGtoCCM 1;
BA_ "U_U55X_MY2022_Rx" SG_ 2612024536 PARSEDPushFcGWM_ECGtoCCM 1;
BA_ "U_T6_MCA_MY2020_Tx" SG_ 2612024536 PARSEDPushFcGWM_ECGtoCCM 1;
BA_ "ECGUsedTxSignal" SG_ 2612024536 PARSEDPushFcGWM_ECGtoCCM 1;
BA_ "U_CD542_MY2021_Tx" SG_ 2612024536 PARSEDPushFcGWM_ECGtoCCM 1;
BA_ "U_U55X_MY2022_Tx" SG_ 2612024536 PARSEDPushFcGWM_ECGtoCCM 1;
BA_ "GenSigSendType" SG_ 2612036824 PARSEDPushFcGWM_ECGtoIPMA 3;
BA_ "U_T6_MCA_MY2020_Rx" SG_ 2612036824 PARSEDPushFcGWM_ECGtoIPMA 1;
BA_ "U_U55X_MY2022_Rx" SG_ 2612036824 PARSEDPushFcGWM_ECGtoIPMA 1;
BA_ "U_T6_MCA_MY2020_Tx" SG_ 2612036824 PARSEDPushFcGWM_ECGtoIPMA 1;
BA_ "ECGUsedTxSignal" SG_ 2612036824 PARSEDPushFcGWM_ECGtoIPMA 1;
BA_ "U_CD542_MY2021_Tx" SG_ 2612036824 PARSEDPushFcGWM_ECGtoIPMA 1;
BA_ "U_U55X_MY2022_Tx" SG_ 2612036824 PARSEDPushFcGWM_ECGtoIPMA 1;
BA_ "U_CD764_MY2022_Tx" SG_ 2612036824 PARSEDPushFcGWM_ECGtoIPMA 1;
BA_ "GenSigSendType" SG_ 2612103384 PARSEDPushFcGWM_ECGtoSODL 3;
BA_ "U_T6_MCA_MY2020_Rx" SG_ 2612103384 PARSEDPushFcGWM_ECGtoSODL 1;
BA_ "U_U55X_MY2022_Rx" SG_ 2612103384 PARSEDPushFcGWM_ECGtoSODL 1;
BA_ "U_T6_MCA_MY2020_Tx" SG_ 2612103384 PARSEDPushFcGWM_ECGtoSODL 1;
BA_ "ECGUsedTxSignal" SG_ 2612103384 PARSEDPushFcGWM_ECGtoSODL 1;
BA_ "U_CD542_MY2021_Tx" SG_ 2612103384 PARSEDPushFcGWM_ECGtoSODL 1;
BA_ "U_U55X_MY2022_Tx" SG_ 2612103384 PARSEDPushFcGWM_ECGtoSODL 1;
BA_ "ECGUsedTxSignal" SG_ 639 OfbTrgtSocOvrrd_Pc_Rq 1;
BA_ "GenSigStartValue" SG_ 639 OfbTrgtSocOvrrd_Pc_Rq 100;
BA_ "ECGUsedTxSignal" SG_ 639 OfbTrgtSocOvrrd_D_Rq 1;
BA_ "GenSigSendType" SG_ 639 OfbTrgtSocOvrrd_D_Rq 3;
BA_ "GenSigSendType" SG_ 639 OfbChrgPrflUpdate_B_Rq 3;
BA_ "ECGUsedTxSignal" SG_ 639 OfbChrgPrflUpdate_B_Rq 1;
BA_ "U_CD542_MY2021_Tx" SG_ 639 OfbChrgPrflUpdate_B_Rq 1;
BA_ "U_U55X_MY2022_Tx" SG_ 639 OfbChrgPrflUpdate_B_Rq 1;
BA_ "GenSigSendType" SG_ 639 OfbChrgClearAll_B_Rq 3;
BA_ "ECGUsedTxSignal" SG_ 639 OfbChrgClearAll_B_Rq 1;
BA_ "U_CD542_MY2021_Tx" SG_ 639 OfbChrgClearAll_B_Rq 1;
BA_ "U_U55X_MY2022_Tx" SG_ 639 OfbChrgClearAll_B_Rq 1;
BA_ "GenSigSendType" SG_ 639 OfbChrgGoTTouch_D_Rq 3;
BA_ "ECGUsedTxSignal" SG_ 639 OfbChrgGoTTouch_D_Rq 1;
BA_ "U_CD542_MY2021_Tx" SG_ 639 OfbChrgGoTTouch_D_Rq 1;
BA_ "U_U55X_MY2022_Tx" SG_ 639 OfbChrgGoTTouch_D_Rq 1;
BA_ "ECGUsedTxSignal" SG_ 639 OfbChrgGoTPrcond_D_Rq 1;
BA_ "U_CD542_MY2021_Tx" SG_ 639 OfbChrgGoTPrcond_D_Rq 1;
BA_ "U_U55X_MY2022_Tx" SG_ 639 OfbChrgGoTPrcond_D_Rq 1;
BA_ "GenSigSendType" SG_ 639 OfbChrgGoTOn_D_Rq 3;
BA_ "GenSigStartValueInteger" SG_ 639 OfbChrgGoTOn_D_Rq 2;
BA_ "ECGUsedTxSignal" SG_ 639 OfbChrgGoTOn_D_Rq 1;
BA_ "U_CD542_MY2021_Tx" SG_ 639 OfbChrgGoTOn_D_Rq 1;
BA_ "U_U55X_MY2022_Tx" SG_ 639 OfbChrgGoTOn_D_Rq 1;
BA_ "ECGUsedTxSignal" SG_ 639 OfbChrgGoTMnte_D_Rq 1;
BA_ "U_CD542_MY2021_Tx" SG_ 639 OfbChrgGoTMnte_D_Rq 1;
BA_ "U_U55X_MY2022_Tx" SG_ 639 OfbChrgGoTMnte_D_Rq 1;
BA_ "GenSigStartValueInteger" SG_ 639 OfbChrgGoTHr_T_Rq 30;
BA_ "GenSigStartValue" SG_ 639 OfbChrgGoTHr_T_Rq 30;
BA_ "ECGUsedTxSignal" SG_ 639 OfbChrgGoTHr_T_Rq 1;
BA_ "U_CD542_MY2021_Tx" SG_ 639 OfbChrgGoTHr_T_Rq 1;
BA_ "U_U55X_MY2022_Tx" SG_ 639 OfbChrgGoTHr_T_Rq 1;
BA_ "GenSigSendType" SG_ 639 OfbChrgGoTExtHtr_D_Rq 3;
BA_ "ECGUsedTxSignal" SG_ 639 OfbChrgGoTExtHtr_D_Rq 1;
BA_ "U_CD542_MY2021_Tx" SG_ 639 OfbChrgGoTExtHtr_D_Rq 1;
BA_ "U_U55X_MY2022_Tx" SG_ 639 OfbChrgGoTExtHtr_D_Rq 1;
BA_ "GenSigSendType" SG_ 639 OfbChrgGoTElement_D_Rq 3;
BA_ "ECGUsedTxSignal" SG_ 639 OfbChrgGoTElement_D_Rq 1;
BA_ "U_CD542_MY2021_Tx" SG_ 639 OfbChrgGoTElement_D_Rq 1;
BA_ "U_U55X_MY2022_Tx" SG_ 639 OfbChrgGoTElement_D_Rq 1;
BA_ "ECGUsedTxSignal" SG_ 639 OfbChrgGoTDelete_B_Rq 1;
BA_ "U_CD542_MY2021_Tx" SG_ 639 OfbChrgGoTDelete_B_Rq 1;
BA_ "U_U55X_MY2022_Tx" SG_ 639 OfbChrgGoTDelete_B_Rq 1;
BA_ "GenSigSendType" SG_ 639 OfbChrgGoTUpdate_B_Rq 3;
BA_ "ECGUsedTxSignal" SG_ 639 OfbChrgGoTUpdate_B_Rq 1;
BA_ "U_CD542_MY2021_Tx" SG_ 639 OfbChrgGoTUpdate_B_Rq 1;
BA_ "U_U55X_MY2022_Tx" SG_ 639 OfbChrgGoTUpdate_B_Rq 1;
BA_ "GenSigSendType" SG_ 530 OfbChrgLocIdTrgt_No_Rq 3;
BA_ "ECGUsedTxSignal" SG_ 530 OfbChrgLocIdTrgt_No_Rq 1;
BA_ "U_CD542_MY2021_Tx" SG_ 530 OfbChrgLocIdTrgt_No_Rq 1;
BA_ "U_U55X_MY2022_Tx" SG_ 530 OfbChrgLocIdTrgt_No_Rq 1;
BA_ "ECGUsedTxSignal" SG_ 530 OfbChrgToPcWknd_D_Actl 1;
BA_ "U_CD542_MY2021_Tx" SG_ 530 OfbChrgToPcWknd_D_Actl 1;
BA_ "U_U55X_MY2022_Tx" SG_ 530 OfbChrgToPcWknd_D_Actl 1;
BA_ "ECGUsedTxSignal" SG_ 530 OfbChrgToPcWkdy_D_Actl 1;
BA_ "U_CD542_MY2021_Tx" SG_ 530 OfbChrgToPcWkdy_D_Actl 1;
BA_ "U_U55X_MY2022_Tx" SG_ 530 OfbChrgToPcWkdy_D_Actl 1;
BA_ "ECGUsedTxSignal" SG_ 530 OfbChrgSetNow_D_Rq 1;
BA_ "U_CD542_MY2021_Tx" SG_ 530 OfbChrgSetNow_D_Rq 1;
BA_ "U_U55X_MY2022_Tx" SG_ 530 OfbChrgSetNow_D_Rq 1;
BA_ "ECGUsedTxSignal" SG_ 530 OfbChrgSetDelete_B_Rq 1;
BA_ "U_CD542_MY2021_Tx" SG_ 530 OfbChrgSetDelete_B_Rq 1;
BA_ "U_U55X_MY2022_Tx" SG_ 530 OfbChrgSetDelete_B_Rq 1;
BA_ "ECGUsedTxSignal" SG_ 530 OfbChrgPrflWknd_No_Rq 1;
BA_ "U_CD542_MY2021_Tx" SG_ 530 OfbChrgPrflWknd_No_Rq 1;
BA_ "U_U55X_MY2022_Tx" SG_ 530 OfbChrgPrflWknd_No_Rq 1;
BA_ "ECGUsedTxSignal" SG_ 530 OfbChrgPrflWkdy_No_Rq 1;
BA_ "U_CD542_MY2021_Tx" SG_ 530 OfbChrgPrflWkdy_No_Rq 1;
BA_ "U_U55X_MY2022_Tx" SG_ 530 OfbChrgPrflWkdy_No_Rq 1;
BA_ "ECGUsedTxSignal" SG_ 530 OfbChrgLocIdUns_B_Rq 1;
BA_ "U_CD542_MY2021_Tx" SG_ 530 OfbChrgLocIdUns_B_Rq 1;
BA_ "U_U55X_MY2022_Tx" SG_ 530 OfbChrgLocIdUns_B_Rq 1;
BA_ "GenSigSendType" SG_ 550 PtWakeupActv1_B_Rq 3;
BA_ "WakeupSignal" SG_ 550 PtWakeupActv1_B_Rq 1;
BA_ "ECGUsedTxSignal" SG_ 550 PtWakeupActv1_B_Rq 1;
BA_ "U_CD542_MY2021_Tx" SG_ 550 PtWakeupActv1_B_Rq 1;
BA_ "U_U55X_MY2022_Tx" SG_ 550 PtWakeupActv1_B_Rq 1;
BA_ "GenSigSendType" SG_ 2612019416 PARSEDPushFcGWM_ECGtoPCM 3;
BA_ "U_T6_MCA_MY2020_Rx" SG_ 2612019416 PARSEDPushFcGWM_ECGtoPCM 1;
BA_ "U_CD542_MY2021_Rx" SG_ 2612019416 PARSEDPushFcGWM_ECGtoPCM 1;
BA_ "U_U55X_MY2022_Rx" SG_ 2612019416 PARSEDPushFcGWM_ECGtoPCM 1;
BA_ "U_CD764_MY2022_Rx" SG_ 2612019416 PARSEDPushFcGWM_ECGtoPCM 1;
BA_ "U_T6_MCA_MY2020_Tx" SG_ 2612019416 PARSEDPushFcGWM_ECGtoPCM 1;
BA_ "ECGUsedTxSignal" SG_ 2612019416 PARSEDPushFcGWM_ECGtoPCM 1;
BA_ "U_U55X_MY2022_Tx" SG_ 2612019416 PARSEDPushFcGWM_ECGtoPCM 1;
BA_ "U_CD764_MY2022_Tx" SG_ 2612019416 PARSEDPushFcGWM_ECGtoPCM 1;
BA_ "U_T6_MCA_MY2020_Tx" SG_ 885 BattULoChrg_D_RqOta 1;
BA_ "ECGUsedTxSignal" SG_ 885 BattULoChrg_D_RqOta 1;
BA_ "U_CD542_MY2021_Tx" SG_ 885 BattULoChrg_D_RqOta 1;
BA_ "U_U55X_MY2022_Tx" SG_ 885 BattULoChrg_D_RqOta 1;
BA_ "U_CD764_MY2022_Tx" SG_ 885 BattULoChrg_D_RqOta 1;
BA_ "U_T6_MCA_MY2020_Tx" SG_ 885 VehStrtInhbt_T_Dsply 1;
BA_ "ECGUsedTxSignal" SG_ 885 VehStrtInhbt_T_Dsply 1;
BA_ "U_CD542_MY2021_Tx" SG_ 885 VehStrtInhbt_T_Dsply 1;
BA_ "U_U55X_MY2022_Tx" SG_ 885 VehStrtInhbt_T_Dsply 1;
BA_ "U_CD764_MY2022_Tx" SG_ 885 VehStrtInhbt_T_Dsply 1;
BA_ "U_T6_MCA_MY2020_Tx" SG_ 885 VehStrtInhbt_D_Dsply 1;
BA_ "ECGUsedTxSignal" SG_ 885 VehStrtInhbt_D_Dsply 1;
BA_ "U_CD542_MY2021_Tx" SG_ 885 VehStrtInhbt_D_Dsply 1;
BA_ "U_U55X_MY2022_Tx" SG_ 885 VehStrtInhbt_D_Dsply 1;
BA_ "U_CD764_MY2022_Tx" SG_ 885 VehStrtInhbt_D_Dsply 1;
BA_ "U_T6_MCA_MY2020_Tx" SG_ 885 VehOnRqstr_D_Stat 1;
BA_ "ECGUsedTxSignal" SG_ 885 VehOnRqstr_D_Stat 1;
BA_ "U_CD542_MY2021_Tx" SG_ 885 VehOnRqstr_D_Stat 1;
BA_ "U_U55X_MY2022_Tx" SG_ 885 VehOnRqstr_D_Stat 1;
BA_ "U_CD764_MY2022_Tx" SG_ 885 VehOnRqstr_D_Stat 1;
BA_ "U_T6_MCA_MY2020_Tx" SG_ 885 VehStrtInhbt_D_RqCld 1;
BA_ "ECGUsedTxSignal" SG_ 885 VehStrtInhbt_D_RqCld 1;
BA_ "U_CD542_MY2021_Tx" SG_ 885 VehStrtInhbt_D_RqCld 1;
BA_ "U_U55X_MY2022_Tx" SG_ 885 VehStrtInhbt_D_RqCld 1;
BA_ "U_CD764_MY2022_Tx" SG_ 885 VehStrtInhbt_D_RqCld 1;
BA_ "U_T6_MCA_MY2020_Tx" SG_ 885 VehOn_D_RqCld 1;
BA_ "ECGUsedTxSignal" SG_ 885 VehOn_D_RqCld 1;
BA_ "U_CD542_MY2021_Tx" SG_ 885 VehOn_D_RqCld 1;
BA_ "U_U55X_MY2022_Tx" SG_ 885 VehOn_D_RqCld 1;
BA_ "U_CD764_MY2022_Tx" SG_ 885 VehOn_D_RqCld 1;
BA_ "MetaData" SG_ 885 CanMsg375_No_Cnt 1;
BA_ "U_T6_MCA_MY2020_Tx" SG_ 885 CanMsg375_No_Cnt 1;
BA_ "ECGUsedTxSignal" SG_ 885 CanMsg375_No_Cnt 1;
BA_ "U_CD542_MY2021_Tx" SG_ 885 CanMsg375_No_Cnt 1;
BA_ "U_U55X_MY2022_Tx" SG_ 885 CanMsg375_No_Cnt 1;
BA_ "U_CD764_MY2022_Tx" SG_ 885 CanMsg375_No_Cnt 1;
BA_ "MetaData" SG_ 885 CanMsg375_No_Crc 1;
BA_ "U_T6_MCA_MY2020_Tx" SG_ 885 CanMsg375_No_Crc 1;
BA_ "ECGUsedTxSignal" SG_ 885 CanMsg375_No_Crc 1;
BA_ "U_CD542_MY2021_Tx" SG_ 885 CanMsg375_No_Crc 1;
BA_ "U_U55X_MY2022_Tx" SG_ 885 CanMsg375_No_Crc 1;
BA_ "U_CD764_MY2022_Tx" SG_ 885 CanMsg375_No_Crc 1;
BA_ "U_T6_MCA_MY2020_Rx" SG_ 885 OtaActv_D_Stat 1;
BA_ "U_T6_MCA_MY2020_Tx" SG_ 885 OtaActv_D_Stat 1;
BA_ "ECGUsedTxSignal" SG_ 885 OtaActv_D_Stat 1;
BA_ "U_CD542_MY2021_Tx" SG_ 885 OtaActv_D_Stat 1;
BA_ "U_U55X_MY2022_Tx" SG_ 885 OtaActv_D_Stat 1;
BA_ "U_CD764_MY2022_Tx" SG_ 885 OtaActv_D_Stat 1;
BA_ "GenSigSendType" SG_ 2612104408 PARSEDPushFcGWM_ECGtoSODR 3;
BA_ "U_T6_MCA_MY2020_Rx" SG_ 2612104408 PARSEDPushFcGWM_ECGtoSODR 1;
BA_ "U_U55X_MY2022_Rx" SG_ 2612104408 PARSEDPushFcGWM_ECGtoSODR 1;
BA_ "U_T6_MCA_MY2020_Tx" SG_ 2612104408 PARSEDPushFcGWM_ECGtoSODR 1;
BA_ "ECGUsedTxSignal" SG_ 2612104408 PARSEDPushFcGWM_ECGtoSODR 1;
BA_ "U_CD542_MY2021_Tx" SG_ 2612104408 PARSEDPushFcGWM_ECGtoSODR 1;
BA_ "U_U55X_MY2022_Tx" SG_ 2612104408 PARSEDPushFcGWM_ECGtoSODR 1;
BA_ "GenSigSendType" SG_ 2612020440 PARSEDPushFcGWMtoSOBDMC 3;
BA_ "ECGUsedTxSignal" SG_ 2612020440 PARSEDPushFcGWMtoSOBDMC 1;
BA_ "U_CD542_MY2021_Tx" SG_ 2612020440 PARSEDPushFcGWMtoSOBDMC 1;
BA_ "U_U55X_MY2022_Tx" SG_ 2612020440 PARSEDPushFcGWMtoSOBDMC 1;
BA_ "GenSigStartValue" SG_ 739 BptMnSoc_L_RqMnu 8190;
BA_ "U_T6_MCA_MY2020_Rx" SG_ 739 EngExhMdeHrStrt_D_Rq 1;
BA_ "U_T6_MCA_MY2020_Rx" SG_ 739 EngExhMdeHrEnd_D_Rq 1;
BA_ "U_T6_MCA_MY2020_Rx" SG_ 739 EngExhMdeHrEnbl_D_Rq 1;
BA_ "GenSigStartValue" SG_ 739 BptDly_T_RqMnu 62;
BA_ "WakeupSignal" SG_ 739 HMI_HMIMode_St 1;
BA_ "U_CD764_MY2022_Rx" SG_ 739 HMI_HMIMode_St 1;
BA_ "ECGUsedTxSignal" SG_ 1160 HybMdeGzg_D_Rq 1;
BA_ "GenSigSendType" SG_ 1160 ReFuelSwtchStat_D_Actl2 3;
BA_ "WakeupSignal" SG_ 1160 ReFuelSwtchStat_D_Actl2 1;
BA_ "ECGUsedTxSignal" SG_ 1160 ReFuelSwtchStat_D_Actl2 1;
BA_ "U_CD764_MY2022_Tx" SG_ 1160 ReFuelSwtchStat_D_Actl2 1;
BA_ "GenSigSendType" SG_ 1160 DcacPwReset_B_RqCell 3;
BA_ "ECGUsedTxSignal" SG_ 1160 DcacPwReset_B_RqCell 1;
BA_ "U_CD542_MY2021_Tx" SG_ 1160 DcacPwReset_B_RqCell 1;
BA_ "U_U55X_MY2022_Tx" SG_ 1160 DcacPwReset_B_RqCell 1;
BA_ "U_CD764_MY2022_Tx" SG_ 1160 DcacPwReset_B_RqCell 1;
BA_ "GenSigSendType" SG_ 1160 DcacPw_D_RqCell 3;
BA_ "ECGUsedTxSignal" SG_ 1160 DcacPw_D_RqCell 1;
BA_ "U_CD542_MY2021_Tx" SG_ 1160 DcacPw_D_RqCell 1;
BA_ "U_U55X_MY2022_Tx" SG_ 1160 DcacPw_D_RqCell 1;
BA_ "U_CD764_MY2022_Tx" SG_ 1160 DcacPw_D_RqCell 1;
BA_ "GenSigSendType" SG_ 1160 DgtlCommPncReset_B_Req 3;
BA_ "ECGUsedTxSignal" SG_ 1160 DgtlCommPncReset_B_Req 1;
BA_ "U_CD542_MY2021_Tx" SG_ 1160 DgtlCommPncReset_B_Req 1;
BA_ "U_U55X_MY2022_Tx" SG_ 1160 DgtlCommPncReset_B_Req 1;
BA_ "U_CD764_MY2022_Tx" SG_ 1160 DgtlCommPncReset_B_Req 1;
BA_ "GenSigSendType" SG_ 1160 DgtlCommPnc_D_Rq 3;
BA_ "ECGUsedTxSignal" SG_ 1160 DgtlCommPnc_D_Rq 1;
BA_ "U_CD542_MY2021_Tx" SG_ 1160 DgtlCommPnc_D_Rq 1;
BA_ "U_U55X_MY2022_Tx" SG_ 1160 DgtlCommPnc_D_Rq 1;
BA_ "U_CD764_MY2022_Tx" SG_ 1160 DgtlCommPnc_D_Rq 1;
BA_ "GenSigSendType" SG_ 1160 DataMntrSustn_B_Rq 3;
BA_ "ECGUsedTxSignal" SG_ 1160 DataMntrSustn_B_Rq 1;
BA_ "U_CD542_MY2021_Tx" SG_ 1160 DataMntrSustn_B_Rq 1;
BA_ "U_U55X_MY2022_Tx" SG_ 1160 DataMntrSustn_B_Rq 1;
BA_ "U_CD764_MY2022_Tx" SG_ 1160 DataMntrSustn_B_Rq 1;
BA_ "GenSigSendType" SG_ 1160 PwSustnRdata_B_RqTelem 3;
BA_ "ECGUsedTxSignal" SG_ 1160 PwSustnRdata_B_RqTelem 1;
BA_ "U_CD542_MY2021_Tx" SG_ 1160 PwSustnRdata_B_RqTelem 1;
BA_ "U_U55X_MY2022_Tx" SG_ 1160 PwSustnRdata_B_RqTelem 1;
BA_ "U_CD764_MY2022_Tx" SG_ 1160 PwSustnRdata_B_RqTelem 1;
BA_ "GenSigSendType" SG_ 1825 TesterPhysicalReqVDM 3;
BA_ "U_T6_MCA_MY2020_Rx" SG_ 1825 TesterPhysicalReqVDM 1;
BA_ "U_U55X_MY2022_Rx" SG_ 1825 TesterPhysicalReqVDM 1;
BA_ "WakeupSignal" SG_ 945 PrkLckCtlMsgTxt_D2_Rq 1;
BA_ "WakeupSignal" SG_ 945 PwLoApim_T_Actl 1;
BA_ "WakeupSignal" SG_ 945 KeyPadCodeDgt6_D_Dsply 1;
BA_ "WakeupSignal" SG_ 945 KeyPadCodeDgt5_D_Dsply 1;
BA_ "WakeupSignal" SG_ 945 KeyPadCodeDgt4_D_Dsply 1;
BA_ "WakeupSignal" SG_ 945 KeyPadCodeDgt3_D_Dsply 1;
BA_ "WakeupSignal" SG_ 945 KeyPadCodeDgt2_D_Dsply 1;
BA_ "WakeupSignal" SG_ 945 KeyPadCodeDgt1_D_Dsply 1;
BA_ "GenSigSendType" SG_ 2612073688 PARSEDPushFcGWMtoSODCMC 3;
BA_ "U_T6_MCA_MY2020_Rx" SG_ 2612073688 PARSEDPushFcGWMtoSODCMC 1;
BA_ "U_U55X_MY2022_Rx" SG_ 2612073688 PARSEDPushFcGWMtoSODCMC 1;
BA_ "U_T6_MCA_MY2020_Tx" SG_ 2612073688 PARSEDPushFcGWMtoSODCMC 1;
BA_ "ECGUsedTxSignal" SG_ 2612073688 PARSEDPushFcGWMtoSODCMC 1;
BA_ "U_CD542_MY2021_Tx" SG_ 2612073688 PARSEDPushFcGWMtoSODCMC 1;
BA_ "U_U55X_MY2022_Tx" SG_ 2612073688 PARSEDPushFcGWMtoSODCMC 1;
BA_ "GenSigSendType" SG_ 1833 TesterPhysicalResVDM 3;
BA_ "U_T6_MCA_MY2020_Tx" SG_ 1833 TesterPhysicalResVDM 1;
BA_ "U_U55X_MY2022_Tx" SG_ 1833 TesterPhysicalResVDM 1;
BA_ "U_T6_MCA_MY2020_Rx" SG_ 395 SelDrvMdeCnfm_D_Stat 1;
BA_ "U_U55X_MY2022_Rx" SG_ 395 SelDrvMdeCnfm_D_Stat 1;
BA_ "U_CD764_MY2022_Rx" SG_ 395 SelDrvMdeCnfm_D_Stat 1;
BA_ "GenSigStartValueInteger" SG_ 395 HudShifPoint_N_Rq 30;
BA_ "GenSigStartValue" SG_ 395 HudShifPoint_N_Rq 30;
BA_ "U_CD542_MY2021_Rx" SG_ 542 LocationServices_3 1;
BA_ "GenSigSendType" SG_ 515 PtIgnSwtch_D_Stat 3;
BA_ "GenSigStartValueInteger" SG_ 515 PtIgnSwtch_D_Stat 2;
BA_ "GenSigStartValue" SG_ 515 PtIgnSwtch_D_Stat 2;
BA_ "U_T6_MCA_MY2020_Tx" SG_ 515 PtIgnSwtch_D_Stat 1;
BA_ "U_CD764_MY2022_Tx" SG_ 515 PtIgnSwtch_D_Stat 1;
BA_ "U_T6_MCA_MY2020_Rx" SG_ 982 LatCtlRampType_D_Rq 1;
BA_ "U_U55X_MY2022_Rx" SG_ 982 LatCtlRampType_D_Rq 1;
BA_ "U_CD764_MY2022_Rx" SG_ 982 LatCtlRampType_D_Rq 1;
BA_ "U_T6_MCA_MY2020_Tx" SG_ 982 LatCtlRampType_D_Rq 1;
BA_ "U_U55X_MY2022_Tx" SG_ 982 LatCtlRampType_D_Rq 1;
BA_ "U_CD764_MY2022_Tx" SG_ 982 LatCtlRampType_D_Rq 1;
BA_ "GenSigStartValue" SG_ 982 LatCtlCrv_NoRate2_Actl 1024;
BA_ "U_T6_MCA_MY2020_Rx" SG_ 982 LatCtlCrv_NoRate2_Actl 1;
BA_ "U_CD542_MY2021_Rx" SG_ 982 LatCtlCrv_NoRate2_Actl 1;
BA_ "U_U55X_MY2022_Rx" SG_ 982 LatCtlCrv_NoRate2_Actl 1;
BA_ "U_CD764_MY2022_Rx" SG_ 982 LatCtlCrv_NoRate2_Actl 1;
BA_ "U_T6_MCA_MY2020_Tx" SG_ 982 LatCtlCrv_NoRate2_Actl 1;
BA_ "U_CD542_MY2021_Tx" SG_ 982 LatCtlCrv_NoRate2_Actl 1;
BA_ "U_U55X_MY2022_Tx" SG_ 982 LatCtlCrv_NoRate2_Actl 1;
BA_ "U_CD764_MY2022_Tx" SG_ 982 LatCtlCrv_NoRate2_Actl 1;
BA_ "ContentDependant" SG_ 982 LatCtlPath_No_Cnt 1;
BA_ "MetaData" SG_ 982 LatCtlPath_No_Cnt 1;
BA_ "U_T6_MCA_MY2020_Rx" SG_ 982 LatCtlPath_No_Cnt 1;
BA_ "U_U55X_MY2022_Rx" SG_ 982 LatCtlPath_No_Cnt 1;
BA_ "U_CD764_MY2022_Rx" SG_ 982 LatCtlPath_No_Cnt 1;
BA_ "U_T6_MCA_MY2020_Tx" SG_ 982 LatCtlPath_No_Cnt 1;
BA_ "U_CD542_MY2021_Tx" SG_ 982 LatCtlPath_No_Cnt 1;
BA_ "U_U55X_MY2022_Tx" SG_ 982 LatCtlPath_No_Cnt 1;
BA_ "U_CD764_MY2022_Tx" SG_ 982 LatCtlPath_No_Cnt 1;
BA_ "ContentDependant" SG_ 982 LatCtlPath_No_Cs 1;
BA_ "MetaData" SG_ 982 LatCtlPath_No_Cs 1;
BA_ "U_T6_MCA_MY2020_Rx" SG_ 982 LatCtlPath_No_Cs 1;
BA_ "U_U55X_MY2022_Rx" SG_ 982 LatCtlPath_No_Cs 1;
BA_ "U_CD764_MY2022_Rx" SG_ 982 LatCtlPath_No_Cs 1;
BA_ "U_T6_MCA_MY2020_Tx" SG_ 982 LatCtlPath_No_Cs 1;
BA_ "U_CD542_MY2021_Tx" SG_ 982 LatCtlPath_No_Cs 1;
BA_ "U_U55X_MY2022_Tx" SG_ 982 LatCtlPath_No_Cs 1;
BA_ "U_CD764_MY2022_Tx" SG_ 982 LatCtlPath_No_Cs 1;
BA_ "U_T6_MCA_MY2020_Rx" SG_ 982 LatCtl_D2_Rq 1;
BA_ "U_CD542_MY2021_Rx" SG_ 982 LatCtl_D2_Rq 1;
BA_ "U_U55X_MY2022_Rx" SG_ 982 LatCtl_D2_Rq 1;
BA_ "U_CD764_MY2022_Rx" SG_ 982 LatCtl_D2_Rq 1;
BA_ "U_T6_MCA_MY2020_Tx" SG_ 982 LatCtl_D2_Rq 1;
BA_ "U_CD542_MY2021_Tx" SG_ 982 LatCtl_D2_Rq 1;
BA_ "U_U55X_MY2022_Tx" SG_ 982 LatCtl_D2_Rq 1;
BA_ "U_CD764_MY2022_Tx" SG_ 982 LatCtl_D2_Rq 1;
BA_ "U_T6_MCA_MY2020_Rx" SG_ 982 LatCtlPrecision_D_Rq 1;
BA_ "U_U55X_MY2022_Rx" SG_ 982 LatCtlPrecision_D_Rq 1;
BA_ "U_CD764_MY2022_Rx" SG_ 982 LatCtlPrecision_D_Rq 1;
BA_ "U_T6_MCA_MY2020_Tx" SG_ 982 LatCtlPrecision_D_Rq 1;
BA_ "U_U55X_MY2022_Tx" SG_ 982 LatCtlPrecision_D_Rq 1;
BA_ "U_CD764_MY2022_Tx" SG_ 982 LatCtlPrecision_D_Rq 1;
BA_ "GenSigStartValueInteger" SG_ 982 LatCtlPathOffst_L_Actl 512;
BA_ "U_T6_MCA_MY2020_Rx" SG_ 982 LatCtlPathOffst_L_Actl 1;
BA_ "U_U55X_MY2022_Rx" SG_ 982 LatCtlPathOffst_L_Actl 1;
BA_ "U_CD764_MY2022_Rx" SG_ 982 LatCtlPathOffst_L_Actl 1;
BA_ "U_T6_MCA_MY2020_Tx" SG_ 982 LatCtlPathOffst_L_Actl 1;
BA_ "U_U55X_MY2022_Tx" SG_ 982 LatCtlPathOffst_L_Actl 1;
BA_ "U_CD764_MY2022_Tx" SG_ 982 LatCtlPathOffst_L_Actl 1;
BA_ "GenSigStartValueInteger" SG_ 982 LatCtlPath_An_Actl 1000;
BA_ "U_T6_MCA_MY2020_Rx" SG_ 982 LatCtlPath_An_Actl 1;
BA_ "U_U55X_MY2022_Rx" SG_ 982 LatCtlPath_An_Actl 1;
BA_ "U_CD764_MY2022_Rx" SG_ 982 LatCtlPath_An_Actl 1;
BA_ "U_T6_MCA_MY2020_Tx" SG_ 982 LatCtlPath_An_Actl 1;
BA_ "U_U55X_MY2022_Tx" SG_ 982 LatCtlPath_An_Actl 1;
BA_ "U_CD764_MY2022_Tx" SG_ 982 LatCtlPath_An_Actl 1;
BA_ "GenSigStartValueInteger" SG_ 982 LatCtlCurv_No_Actl 1000;
BA_ "U_T6_MCA_MY2020_Rx" SG_ 982 LatCtlCurv_No_Actl 1;
BA_ "U_U55X_MY2022_Rx" SG_ 982 LatCtlCurv_No_Actl 1;
BA_ "U_CD764_MY2022_Rx" SG_ 982 LatCtlCurv_No_Actl 1;
BA_ "U_T6_MCA_MY2020_Tx" SG_ 982 LatCtlCurv_No_Actl 1;
BA_ "U_U55X_MY2022_Tx" SG_ 982 LatCtlCurv_No_Actl 1;
BA_ "U_CD764_MY2022_Tx" SG_ 982 LatCtlCurv_No_Actl 1;
BA_ "U_T6_MCA_MY2020_Rx" SG_ 982 HandsOffCnfm_B_Rq 1;
BA_ "U_U55X_MY2022_Rx" SG_ 982 HandsOffCnfm_B_Rq 1;
BA_ "U_CD764_MY2022_Rx" SG_ 982 HandsOffCnfm_B_Rq 1;
BA_ "U_T6_MCA_MY2020_Tx" SG_ 982 HandsOffCnfm_B_Rq 1;
BA_ "U_U55X_MY2022_Tx" SG_ 982 HandsOffCnfm_B_Rq 1;
BA_ "U_CD764_MY2022_Tx" SG_ 982 HandsOffCnfm_B_Rq 1;
BA_ "ContentDependant" SG_ 1104 DrvEngageLevel_No_Cs 1;
BA_ "MetaData" SG_ 1104 DrvEngageLevel_No_Cs 1;
BA_ "U_T6_MCA_MY2020_Rx" SG_ 1104 DrvEngageLevel_No_Cs 1;
BA_ "U_CD542_MY2021_Rx" SG_ 1104 DrvEngageLevel_No_Cs 1;
BA_ "U_U55X_MY2022_Rx" SG_ 1104 DrvEngageLevel_No_Cs 1;
BA_ "U_CD764_MY2022_Rx" SG_ 1104 DrvEngageLevel_No_Cs 1;
BA_ "U_T6_MCA_MY2020_Tx" SG_ 1104 DrvEngageLevel_No_Cs 1;
BA_ "U_CD542_MY2021_Tx" SG_ 1104 DrvEngageLevel_No_Cs 1;
BA_ "U_U55X_MY2022_Tx" SG_ 1104 DrvEngageLevel_No_Cs 1;
BA_ "U_CD764_MY2022_Tx" SG_ 1104 DrvEngageLevel_No_Cs 1;
BA_ "ContentDependant" SG_ 1104 DrvEngageLevel_No_Cnt 1;
BA_ "MetaData" SG_ 1104 DrvEngageLevel_No_Cnt 1;
BA_ "U_T6_MCA_MY2020_Rx" SG_ 1104 DrvEngageLevel_No_Cnt 1;
BA_ "U_CD542_MY2021_Rx" SG_ 1104 DrvEngageLevel_No_Cnt 1;
BA_ "U_U55X_MY2022_Rx" SG_ 1104 DrvEngageLevel_No_Cnt 1;
BA_ "U_CD764_MY2022_Rx" SG_ 1104 DrvEngageLevel_No_Cnt 1;
BA_ "U_T6_MCA_MY2020_Tx" SG_ 1104 DrvEngageLevel_No_Cnt 1;
BA_ "U_CD542_MY2021_Tx" SG_ 1104 DrvEngageLevel_No_Cnt 1;
BA_ "U_U55X_MY2022_Tx" SG_ 1104 DrvEngageLevel_No_Cnt 1;
BA_ "U_CD764_MY2022_Tx" SG_ 1104 DrvEngageLevel_No_Cnt 1;
BA_ "U_T6_MCA_MY2020_Rx" SG_ 1104 DrvEngageLevel_D_Stat 1;
BA_ "U_CD542_MY2021_Rx" SG_ 1104 DrvEngageLevel_D_Stat 1;
BA_ "U_U55X_MY2022_Rx" SG_ 1104 DrvEngageLevel_D_Stat 1;
BA_ "U_CD764_MY2022_Rx" SG_ 1104 DrvEngageLevel_D_Stat 1;
BA_ "U_T6_MCA_MY2020_Tx" SG_ 1104 DrvEngageLevel_D_Stat 1;
BA_ "U_CD542_MY2021_Tx" SG_ 1104 DrvEngageLevel_D_Stat 1;
BA_ "U_U55X_MY2022_Tx" SG_ 1104 DrvEngageLevel_D_Stat 1;
BA_ "U_CD764_MY2022_Tx" SG_ 1104 DrvEngageLevel_D_Stat 1;
BA_ "U_T6_MCA_MY2020_Rx" SG_ 1104 DrvImpLvlConfid_D_Stat 1;
BA_ "U_CD542_MY2021_Rx" SG_ 1104 DrvImpLvlConfid_D_Stat 1;
BA_ "U_U55X_MY2022_Rx" SG_ 1104 DrvImpLvlConfid_D_Stat 1;
BA_ "U_CD764_MY2022_Rx" SG_ 1104 DrvImpLvlConfid_D_Stat 1;
BA_ "U_T6_MCA_MY2020_Tx" SG_ 1104 DrvImpLvlConfid_D_Stat 1;
BA_ "U_CD542_MY2021_Tx" SG_ 1104 DrvImpLvlConfid_D_Stat 1;
BA_ "U_U55X_MY2022_Tx" SG_ 1104 DrvImpLvlConfid_D_Stat 1;
BA_ "U_CD764_MY2022_Tx" SG_ 1104 DrvImpLvlConfid_D_Stat 1;
BA_ "U_T6_MCA_MY2020_Rx" SG_ 1104 DrvImpairLvl_D_Stat 1;
BA_ "U_CD542_MY2021_Rx" SG_ 1104 DrvImpairLvl_D_Stat 1;
BA_ "U_U55X_MY2022_Rx" SG_ 1104 DrvImpairLvl_D_Stat 1;
BA_ "U_CD764_MY2022_Rx" SG_ 1104 DrvImpairLvl_D_Stat 1;
BA_ "U_T6_MCA_MY2020_Tx" SG_ 1104 DrvImpairLvl_D_Stat 1;
BA_ "U_CD542_MY2021_Tx" SG_ 1104 DrvImpairLvl_D_Stat 1;
BA_ "U_U55X_MY2022_Tx" SG_ 1104 DrvImpairLvl_D_Stat 1;
BA_ "U_CD764_MY2022_Tx" SG_ 1104 DrvImpairLvl_D_Stat 1;
BA_ "U_T6_MCA_MY2020_Rx" SG_ 1104 DrvEngLvlConfid_D_Stat 1;
BA_ "U_CD542_MY2021_Rx" SG_ 1104 DrvEngLvlConfid_D_Stat 1;
BA_ "U_U55X_MY2022_Rx" SG_ 1104 DrvEngLvlConfid_D_Stat 1;
BA_ "U_CD764_MY2022_Rx" SG_ 1104 DrvEngLvlConfid_D_Stat 1;
BA_ "U_T6_MCA_MY2020_Tx" SG_ 1104 DrvEngLvlConfid_D_Stat 1;
BA_ "U_CD542_MY2021_Tx" SG_ 1104 DrvEngLvlConfid_D_Stat 1;
BA_ "U_U55X_MY2022_Tx" SG_ 1104 DrvEngLvlConfid_D_Stat 1;
BA_ "U_CD764_MY2022_Tx" SG_ 1104 DrvEngLvlConfid_D_Stat 1;
BA_ "U_T6_MCA_MY2020_Rx" SG_ 1104 DrvCamPassIR_D_Stat 1;
BA_ "U_CD542_MY2021_Rx" SG_ 1104 DrvCamPassIR_D_Stat 1;
BA_ "U_U55X_MY2022_Rx" SG_ 1104 DrvCamPassIR_D_Stat 1;
BA_ "U_CD764_MY2022_Rx" SG_ 1104 DrvCamPassIR_D_Stat 1;
BA_ "U_T6_MCA_MY2020_Tx" SG_ 1104 DrvCamPassIR_D_Stat 1;
BA_ "U_CD542_MY2021_Tx" SG_ 1104 DrvCamPassIR_D_Stat 1;
BA_ "U_U55X_MY2022_Tx" SG_ 1104 DrvCamPassIR_D_Stat 1;
BA_ "U_CD764_MY2022_Tx" SG_ 1104 DrvCamPassIR_D_Stat 1;
BA_ "U_T6_MCA_MY2020_Rx" SG_ 1104 DrvCamera_D_Stat 1;
BA_ "U_CD542_MY2021_Rx" SG_ 1104 DrvCamera_D_Stat 1;
BA_ "U_U55X_MY2022_Rx" SG_ 1104 DrvCamera_D_Stat 1;
BA_ "U_CD764_MY2022_Rx" SG_ 1104 DrvCamera_D_Stat 1;
BA_ "U_T6_MCA_MY2020_Tx" SG_ 1104 DrvCamera_D_Stat 1;
BA_ "U_CD542_MY2021_Tx" SG_ 1104 DrvCamera_D_Stat 1;
BA_ "U_U55X_MY2022_Tx" SG_ 1104 DrvCamera_D_Stat 1;
BA_ "U_CD764_MY2022_Tx" SG_ 1104 DrvCamera_D_Stat 1;
BA_ "U_T6_MCA_MY2020_Rx" SG_ 1104 DrvCamDrvIR_D_Stat 1;
BA_ "U_CD542_MY2021_Rx" SG_ 1104 DrvCamDrvIR_D_Stat 1;
BA_ "U_U55X_MY2022_Rx" SG_ 1104 DrvCamDrvIR_D_Stat 1;
BA_ "U_CD764_MY2022_Rx" SG_ 1104 DrvCamDrvIR_D_Stat 1;
BA_ "U_T6_MCA_MY2020_Tx" SG_ 1104 DrvCamDrvIR_D_Stat 1;
BA_ "U_CD542_MY2021_Tx" SG_ 1104 DrvCamDrvIR_D_Stat 1;
BA_ "U_U55X_MY2022_Tx" SG_ 1104 DrvCamDrvIR_D_Stat 1;
BA_ "U_CD764_MY2022_Tx" SG_ 1104 DrvCamDrvIR_D_Stat 1;
BA_ "U_T6_MCA_MY2020_Rx" SG_ 1104 DrvAttentZone_D_Stat 1;
BA_ "U_CD542_MY2021_Rx" SG_ 1104 DrvAttentZone_D_Stat 1;
BA_ "U_U55X_MY2022_Rx" SG_ 1104 DrvAttentZone_D_Stat 1;
BA_ "U_CD764_MY2022_Rx" SG_ 1104 DrvAttentZone_D_Stat 1;
BA_ "U_T6_MCA_MY2020_Tx" SG_ 1104 DrvAttentZone_D_Stat 1;
BA_ "U_CD542_MY2021_Tx" SG_ 1104 DrvAttentZone_D_Stat 1;
BA_ "U_U55X_MY2022_Tx" SG_ 1104 DrvAttentZone_D_Stat 1;
BA_ "U_CD764_MY2022_Tx" SG_ 1104 DrvAttentZone_D_Stat 1;
BA_ "U_T6_MCA_MY2020_Rx" SG_ 1104 DrvAlertSt_D_Stat 1;
BA_ "U_CD542_MY2021_Rx" SG_ 1104 DrvAlertSt_D_Stat 1;
BA_ "U_U55X_MY2022_Rx" SG_ 1104 DrvAlertSt_D_Stat 1;
BA_ "U_CD764_MY2022_Rx" SG_ 1104 DrvAlertSt_D_Stat 1;
BA_ "U_T6_MCA_MY2020_Tx" SG_ 1104 DrvAlertSt_D_Stat 1;
BA_ "U_CD542_MY2021_Tx" SG_ 1104 DrvAlertSt_D_Stat 1;
BA_ "U_U55X_MY2022_Tx" SG_ 1104 DrvAlertSt_D_Stat 1;
BA_ "U_CD764_MY2022_Tx" SG_ 1104 DrvAlertSt_D_Stat 1;
BA_ "GenSigSendType" SG_ 2610021592 OTAPhysGWM_ECGtoHCM 3;
BA_ "U_U55X_MY2022_Rx" SG_ 2610021592 OTAPhysGWM_ECGtoHCM 1;
BA_ "U_CD764_MY2022_Rx" SG_ 2610021592 OTAPhysGWM_ECGtoHCM 1;
BA_ "ECGUsedTxSignal" SG_ 2610021592 OTAPhysGWM_ECGtoHCM 1;
BA_ "U_CD542_MY2021_Tx" SG_ 2610021592 OTAPhysGWM_ECGtoHCM 1;
BA_ "U_U55X_MY2022_Tx" SG_ 2610021592 OTAPhysGWM_ECGtoHCM 1;
BA_ "GenSigSendType" SG_ 2610975960 PARSEDPhysGWM_ECGtoCCM 3;
BA_ "U_T6_MCA_MY2020_Rx" SG_ 2610975960 PARSEDPhysGWM_ECGtoCCM 1;
BA_ "U_CD542_MY2021_Rx" SG_ 2610975960 PARSEDPhysGWM_ECGtoCCM 1;
BA_ "U_U55X_MY2022_Rx" SG_ 2610975960 PARSEDPhysGWM_ECGtoCCM 1;
BA_ "U_CD764_MY2022_Rx" SG_ 2610975960 PARSEDPhysGWM_ECGtoCCM 1;
BA_ "U_T6_MCA_MY2020_Tx" SG_ 2610975960 PARSEDPhysGWM_ECGtoCCM 1;
BA_ "ECGUsedTxSignal" SG_ 2610975960 PARSEDPhysGWM_ECGtoCCM 1;
BA_ "U_CD542_MY2021_Tx" SG_ 2610975960 PARSEDPhysGWM_ECGtoCCM 1;
BA_ "U_U55X_MY2022_Tx" SG_ 2610975960 PARSEDPhysGWM_ECGtoCCM 1;
BA_ "GenSigSendType" SG_ 2611175445 PARSEDPhysCCMtoGWM_ECG 3;
BA_ "U_T6_MCA_MY2020_Rx" SG_ 2611175445 PARSEDPhysCCMtoGWM_ECG 1;
BA_ "ECGUsedRxSignal" SG_ 2611175445 PARSEDPhysCCMtoGWM_ECG 1;
BA_ "U_CD542_MY2021_Rx" SG_ 2611175445 PARSEDPhysCCMtoGWM_ECG 1;
BA_ "U_U55X_MY2022_Rx" SG_ 2611175445 PARSEDPhysCCMtoGWM_ECG 1;
BA_ "U_T6_MCA_MY2020_Tx" SG_ 2611175445 PARSEDPhysCCMtoGWM_ECG 1;
BA_ "U_CD542_MY2021_Tx" SG_ 2611175445 PARSEDPhysCCMtoGWM_ECG 1;
BA_ "U_U55X_MY2022_Tx" SG_ 2611175445 PARSEDPhysCCMtoGWM_ECG 1;
BA_ "U_CD764_MY2022_Tx" SG_ 2611175445 PARSEDPhysCCMtoGWM_ECG 1;
BA_ "GenSigSendType" SG_ 2612224021 PARSEDPushCCMtoGWM_ECG 3;
BA_ "U_T6_MCA_MY2020_Rx" SG_ 2612224021 PARSEDPushCCMtoGWM_ECG 1;
BA_ "ECGUsedRxSignal" SG_ 2612224021 PARSEDPushCCMtoGWM_ECG 1;
BA_ "U_CD542_MY2021_Rx" SG_ 2612224021 PARSEDPushCCMtoGWM_ECG 1;
BA_ "U_U55X_MY2022_Rx" SG_ 2612224021 PARSEDPushCCMtoGWM_ECG 1;
BA_ "U_T6_MCA_MY2020_Tx" SG_ 2612224021 PARSEDPushCCMtoGWM_ECG 1;
BA_ "U_CD542_MY2021_Tx" SG_ 2612224021 PARSEDPushCCMtoGWM_ECG 1;
BA_ "U_U55X_MY2022_Tx" SG_ 2612224021 PARSEDPushCCMtoGWM_ECG 1;
BA_ "U_CD764_MY2022_Tx" SG_ 2612224021 PARSEDPushCCMtoGWM_ECG 1;
BA_ "GenSigSendType" SG_ 2611025112 PARSEDPhysGWM_ECGtoSODCMC 3;
BA_ "U_T6_MCA_MY2020_Rx" SG_ 2611025112 PARSEDPhysGWM_ECGtoSODCMC 1;
BA_ "U_U55X_MY2022_Rx" SG_ 2611025112 PARSEDPhysGWM_ECGtoSODCMC 1;
BA_ "U_T6_MCA_MY2020_Tx" SG_ 2611025112 PARSEDPhysGWM_ECGtoSODCMC 1;
BA_ "ECGUsedTxSignal" SG_ 2611025112 PARSEDPhysGWM_ECGtoSODCMC 1;
BA_ "U_CD542_MY2021_Tx" SG_ 2611025112 PARSEDPhysGWM_ECGtoSODCMC 1;
BA_ "U_U55X_MY2022_Tx" SG_ 2611025112 PARSEDPhysGWM_ECGtoSODCMC 1;
BA_ "GenSigSendType" SG_ 2611175493 PARSEDPhysSODCMCtoGWM_ECG 3;
BA_ "U_T6_MCA_MY2020_Rx" SG_ 2611175493 PARSEDPhysSODCMCtoGWM_ECG 1;
BA_ "ECGUsedRxSignal" SG_ 2611175493 PARSEDPhysSODCMCtoGWM_ECG 1;
BA_ "U_CD542_MY2021_Rx" SG_ 2611175493 PARSEDPhysSODCMCtoGWM_ECG 1;
BA_ "U_U55X_MY2022_Rx" SG_ 2611175493 PARSEDPhysSODCMCtoGWM_ECG 1;
BA_ "U_T6_MCA_MY2020_Tx" SG_ 2611175493 PARSEDPhysSODCMCtoGWM_ECG 1;
BA_ "U_CD542_MY2021_Tx" SG_ 2611175493 PARSEDPhysSODCMCtoGWM_ECG 1;
BA_ "U_U55X_MY2022_Tx" SG_ 2611175493 PARSEDPhysSODCMCtoGWM_ECG 1;
BA_ "U_CD764_MY2022_Tx" SG_ 2611175493 PARSEDPhysSODCMCtoGWM_ECG 1;
BA_ "GenSigSendType" SG_ 2612224069 PARSEDPushSODCMCtoGWM 3;
BA_ "U_T6_MCA_MY2020_Rx" SG_ 2612224069 PARSEDPushSODCMCtoGWM 1;
BA_ "ECGUsedRxSignal" SG_ 2612224069 PARSEDPushSODCMCtoGWM 1;
BA_ "U_CD542_MY2021_Rx" SG_ 2612224069 PARSEDPushSODCMCtoGWM 1;
BA_ "U_U55X_MY2022_Rx" SG_ 2612224069 PARSEDPushSODCMCtoGWM 1;
BA_ "U_T6_MCA_MY2020_Tx" SG_ 2612224069 PARSEDPushSODCMCtoGWM 1;
BA_ "U_CD542_MY2021_Tx" SG_ 2612224069 PARSEDPushSODCMCtoGWM 1;
BA_ "U_U55X_MY2022_Tx" SG_ 2612224069 PARSEDPushSODCMCtoGWM 1;
BA_ "U_CD764_MY2022_Tx" SG_ 2612224069 PARSEDPushSODCMCtoGWM 1;
BA_ "GenSigSendType" SG_ 1787 TesterPhysicalResSODCMD 3;
BA_ "U_T6_MCA_MY2020_Tx" SG_ 1787 TesterPhysicalResSODCMD 1;
BA_ "U_CD542_MY2021_Tx" SG_ 1787 TesterPhysicalResSODCMD 1;
BA_ "U_U55X_MY2022_Tx" SG_ 1787 TesterPhysicalResSODCMD 1;
BA_ "U_CD764_MY2022_Tx" SG_ 1787 TesterPhysicalResSODCMD 1;
BA_ "GenSigSendType" SG_ 1779 TesterPhysicalReqSODCMD 3;
BA_ "U_T6_MCA_MY2020_Rx" SG_ 1779 TesterPhysicalReqSODCMD 1;
BA_ "U_CD542_MY2021_Rx" SG_ 1779 TesterPhysicalReqSODCMD 1;
BA_ "U_U55X_MY2022_Rx" SG_ 1779 TesterPhysicalReqSODCMD 1;
BA_ "U_CD764_MY2022_Rx" SG_ 1779 TesterPhysicalReqSODCMD 1;
BA_ "GenSigSendType" SG_ 1786 TesterPhysicalResSODCMC 3;
BA_ "U_T6_MCA_MY2020_Tx" SG_ 1786 TesterPhysicalResSODCMC 1;
BA_ "U_CD542_MY2021_Tx" SG_ 1786 TesterPhysicalResSODCMC 1;
BA_ "U_U55X_MY2022_Tx" SG_ 1786 TesterPhysicalResSODCMC 1;
BA_ "U_CD764_MY2022_Tx" SG_ 1786 TesterPhysicalResSODCMC 1;
VAL_ 516 EngAout3_N_Actl 65535 "Invalid" ;
VAL_ 516 ApedPosPcActl_D_Qf 3 "OK" 2 "Not_Within_Specifications" 1 "No_Data_Exists" 0 "Faulty" ;
VAL_ 516 ApedPos_PcRate_ActlArb 255 "Fault" 254 "Unknown" ;
VAL_ 514 StrtrMtrDlyStrt_B_Stat 1 "Yes" 0 "No" ;
VAL_ 514 StrtrMtrCtlMsgTxt_D_Rq 7 "Start_In_Gear_Allowed" 6 "Pending_Start_Cancelled" 5 "Start_Pending_Please_Wait" 4 "Cranking_Limit_Exceeded" 3 "Press_Brk_and_Shift_to_P_N" 2 "Press_Clutch_and_Brake" 1 "Press_Clutch_To_Start" 0 "No_Display" ;
VAL_ 514 VehVActlEng_D_Qf 3 "OK" 2 "Not_Within_Specifications" 1 "No_Data_Exists" 0 "Faulty" ;
VAL_ 514 GearRvrse_D_Actl 7 "Fault" 6 "NotUsed_3" 5 "NotUsed_2" 4 "NotUsed_1" 3 "Active_confirmed" 2 "Active_not_confirmed" 1 "Inactive_confirmed" 0 "Inactive_not_confirmed" ;
VAL_ 514 StrtrMtrCtlMsgTxt_D2_Rq 3 "NoRequestPcmStartingMsgCtl" 2 "ShiftToNeutralToStart" 1 "ShiftToParkToStart" 0 "NoRequestBcmStartingMsgCtl" ;
VAL_ 381 EngOilSrvcMsgTxt_D_Rq 7 "NotUsed3" 6 "OilMinderNotConfigured" 5 "ResetFailed" 4 "ResetComplete" 3 "ResetInProgress" 2 "ChangeOilNow" 1 "ChangeOilSoon" 0 "NoText" ;
VAL_ 381 RunDryPrevent_B_Stat 1 "True" 0 "False" ;
VAL_ 381 WaterInFuel 1 "On" 0 "Off" ;
VAL_ 381 GlowIndication 1 "On" 0 "Off" ;
VAL_ 380 FuelMaintMde_D_Rq 3 "Feature_Not_Present" 2 "Fuel_Maint_Req_Now" 1 "Fuel_Maint_Req_Soon" 0 "NoRequest" ;
VAL_ 380 GrdAsstAllw_D_DsplyPt 3 "NotUsed" 2 "On" 1 "Off" 0 "NoModeSelected" ;
VAL_ 380 EngOilLvlWarn_D_Rq1 7 "Undefined_3" 6 "Undefined_2" 5 "Engine_Oil_Monitor_Fault" 3 "Engine_Oil_High" 2 "Engine_Oil_Critical_Low" 1 "Engine_Oil_Low" 0 "No_Message" 4 "Engine_Oil_Critical_High" ;
VAL_ 377 HvacAirFullOut_B_Rq 1 "Yes" 0 "No" ;
VAL_ 377 TrnManShif_D_IndDrv 7 "Undefined_3" 6 "Undefined_2" 5 "Shift_to_Neutral" 4 "Downshift_Recommendation" 3 "Upshift_Warning" 2 "Upshift_Performance" 1 "Upshift_Fuel_Economy" 0 "No_Indication" ;
VAL_ 377 TrnManShifGear_D_IndDrv 7 "Indicate_Reverse_Gear" 6 "Indicate_Gear6" 5 "Indicate_Gear5" 4 "Indicate_Gear4" 3 "Indicate_Gear3" 2 "Indicate_Gear2" 1 "Indicate_Gear1" 0 "No_Indication" ;
VAL_ 377 EngFuelCutFull_B_Inhbt 1 "Inhibit_DFSO" 0 "Normal" ;
VAL_ 377 FuelFillInlet_B_Dsply 1 "Yes" 0 "No" ;
VAL_ 377 EngSrvcRqd_B_Rq 1 "Engine_Service_Required" 0 "No_engine_service_required" ;
VAL_ 377 OdoCount 255 "Invalid" ;
VAL_ 377 AirCondRec_B_Rq 1 "Yes" 0 "No" ;
VAL_ 377 AirCondClutch_B_Stats 1 "Yes" 0 "No" ;
VAL_ 377 EngAoutTqActl_D_Qf 3 "OK" 2 "Not_Within_Specifications" 1 "No_Data_Exists" 0 "Faulty" ;
VAL_ 376 GasPrtc_D_RqDsply 7 "NotUsed_5" 6 "NotUsed_4" 5 "NotUsed_3" 4 "NotUsed_2" 3 "NotUsed_1" 2 "GpfOverLimit" 1 "GpfAtLimit" 0 "NormalOperation" ;
VAL_ 376 DynoMde_B_Cmd 1 "DynomometerMode" 0 "NormalOperation" ;
VAL_ 376 AslChime_B_Rq 1 "Yes" 0 "No" ;
VAL_ 376 HvacHtrCore2_Te_Actl 1023 "Faulty" ;
VAL_ 376 PtcHtr_D_Cmd 3 "TurnOn" 2 "AutoMode" 1 "TurnOff" 0 "NoDecision_Initializing" ;
VAL_ 376 EcssLamp_D_RqDsply 3 "Not_Used" 2 "Flash" 1 "On" 0 "Off" ;
VAL_ 376 AirAmbTe_D_Qf 3 "OK" 2 "Not_Within_Specifications" 1 "No_Data_Exists" 0 "Faulty" ;
VAL_ 376 AirAmb_P_Actl 63 "Fault" 62 "NoDataExists" ;
VAL_ 376 AslIconDsply_D_Rq 3 "On_Passive_Overridden" 2 "On_Active" 1 "On_Passive" 0 "Off" ;
VAL_ 373 EngFuelCutFull_B_Allw 1 "Yes" 0 "No" ;
VAL_ 359 LscmbbEngTqMn_B_Actl 1 "Engine_Braking_Activated" 0 "Engine_Braking_Off" ;
VAL_ 359 LscmbbDeny_B_ActlPrpl 1 "Denied" 0 "Allowed" ;
VAL_ 359 PrplWhlRgenMn_Tq_Actl 8191 "Faulty" ;
VAL_ 359 ElPw_D_StatStrtStop 15 "NotUsed6" 14 "NotUsed5" 13 "NotUsed4" 12 "NotUsed3" 11 "NotUsed2" 10 "NotUsed1" 9 "Supported_Level_4" 8 "Supported_Level_3" 7 "Supported_Level_2" 6 "Supported_Level_1" 5 "Limited_Support" 4 "Fault_Limited" 3 "LV_Event_in_Progress" 2 "Not_Supported_Imminent" 1 "Supported_All" 0 "Not_Supported" ;
VAL_ 359 PrplWhlTot2_Tq_Actl 65535 "Fault" 65534 "NoDataExists" ;
VAL_ 359 PwPckTq_D_Stat 3 "PwPckOn_TqAvailable" 2 "StartInPrgrss_TqNotAvail" 1 "PwPckOn_TqNotAvailable" 0 "PwPckOff_TqNotAvailable" ;
VAL_ 359 Eng_D_Stat 3 "NotUsed" 2 "EngAutoStopped" 1 "EngOn" 0 "EngOff" ;
VAL_ 359 PlgActvArb_B_Actl 1 "On" 0 "Off" ;
VAL_ 359 ElPw_D_Stat 7 "NotUsed_3" 6 "NotUsed_2" 5 "NotUsed_1" 4 "Fault_Limited" 3 "LV_Event_In_Progress" 2 "Not_Supported_Imminent" 1 "Supported" 0 "Not_Supported" ;
VAL_ 359 TrnAinTq_D_Qf 3 "OK" 2 "Not_Within_Specifications" 1 "No_Data_Exists" 0 "Faulty" ;
VAL_ 358 StopStrtStdby_D_Indic 6 "Telltale_On_Grey" 5 "Telltale_Struck_Out" 4 "Telltale_Flashing_Amber" 3 "Telltale_On_Amber" 2 "Telltale_Flashing_Green" 1 "Telltale_On_Green" 0 "Telltale_Off" 7 "NotUsed3" ;
VAL_ 358 StopStrtIODTxt_D_Rq 31 "Message31" 30 "Message30" 29 "Message29" 28 "Message28" 27 "Message27" 26 "Message26" 25 "Message25" 24 "Message24" 23 "Message23" 22 "Message22" 21 "Message21" 20 "Message20" 19 "Message19" 18 "Message18" 17 "Message17" 16 "Message16" 15 "Message15" 14 "Message14" 13 "Message13" 12 "Message12" 11 "Message11" 10 "Message10" 9 "Message9" 8 "Message8" 7 "Message7" 6 "Message6" 5 "Message5" 4 "Message4" 3 "Message3" 2 "Message2" 1 "Message1" 0 "NoMessage" ;
VAL_ 358 StopStrtDrvMde_D_Indic 3 "NotUsed" 2 "StartStop_IndirectDeselect" 1 "StopStart_Deselected" 0 "StopStart_Selected" ;
VAL_ 358 StopStrtMsgTxt_D_Rq 15 "Message_15" 14 "Message_14" 13 "Message_13" 12 "Message_12" 11 "Message_11" 10 "Message_10" 9 "Message_9" 8 "Message_8" 7 "Message_7" 6 "Message_6" 5 "Message_5" 4 "Message_4" 3 "Message_3" 2 "Message_2" 1 "Message_1" 0 "NoMessage" ;
VAL_ 358 OdoTripVerify_L_Actl 16777215 "Fault" ;
VAL_ 358 HiElPwInhbt_B_Stat 1 "Inhibit" 0 "No_Inibit" ;
VAL_ 358 AutoStopPtDelta_I_Est 255 "Fault" ;
VAL_ 357 BPedDrvAppl_D_QF 3 "OK" 2 "Not_Within_Specifications" 1 "No_Data_Exists" 0 "Faulty" ;
VAL_ 357 CmbbDeny_B_ActlPrpl 1 "Yes" 0 "No" ;
VAL_ 357 PrplTqMnSat_B_Actl 1 "Yes" 0 "No" ;
VAL_ 357 VehStrtStop_D_Rq 3 "NotUsed" 2 "Vehicle_Start_Request" 1 "Vehicle_Stop_Request" 0 "NoRequest" ;
VAL_ 357 BpedDrvAppl_D_Actl 3 "_Not_Allowed" 2 "Driver_Braking" 1 "Driver_Not_Braking" 0 "Not_Allowed" ;
VAL_ 357 CmbbEngTqMn_B_Actl 1 "Yes" 0 "No" ;
VAL_ 357 Veh_V_DsplyCcSet 255 "Fault" 254 "Unknown" ;
VAL_ 357 AccEngStat_D_Actl 7 "Undefined_2" 6 "Undefined_1" 5 "ACCSoonCancel_due_Low_Spd" 4 "Shift_Down_Recommendation" 3 "Shift_Up_Recommendation" 2 "ACCNotAllowedToBeActivated" 1 "ACCStandby_due_Auto_Cancel" 0 "Normal_Operation" ;
VAL_ 357 CcMde_D_Actl 7 "TapDownWaiting" 6 "TapUpWaiting" 5 "Resuming_Low" 4 "Resuming_High" 3 "Decelerating" 2 "Accelerating" 1 "Keeping_Speed" 0 "Not_Active" ;
VAL_ 357 CcStat_D_Actl 7 "Undefined_2" 6 "Undefined_1" 5 "Active" 4 "Active_Que_Assist" 3 "Standby" 2 "Standby_Denied" 1 "Denied" 0 "Off" ;
VAL_ 357 CcOvrrdActv_B_Actl 1 "Cruise_Overridden" 0 "Cruise_Req_Not_Overridden" ;
VAL_ 357 AccStopMde_D_Rq 3 "Stop_Mode_Active" 2 "EPBApplyOrBrakeReleaseWarn" 1 "Limit_Rolling_Speed" 0 "Stop_Mode_Not_Active" ;
VAL_ 342 HtrLoop_B_Stat 1 "Fault" 0 "No_Fault" ;
VAL_ 342 EngOvrhtMitgActv_D_Ind 3 "Undefined" 2 "Mode2" 1 "Mode1" 0 "Normal_Mode" ;
VAL_ 342 EngClntTe_D_Qf 3 "OK" 2 "Not_Within_Specifications" 1 "No_Data_Exists" 0 "Faulty" ;
VAL_ 342 EngTeColdPrtct_B_Rq 1 "On" 0 "Off" ;
VAL_ 71 immoTarget1Status 7 "Unused4" 6 "Unused3" 5 "Unused2" 4 "ENABLED_LIMITEDMOTIVE_STAR" 3 "DISABLED_RESET   " 2 "ENABLED_NONMOTIVE_START" 1 "ENABLED_MOTIVE_START" 0 "DISABLED" ;
VAL_ 71 immoTarget1Cmd 7 "Unused4" 6 "Unused3" 5 "Unused2" 4 "Unused1" 3 "TARGET1_IDBLOCK2" 2 "TARGET1_IDBLOCK1" 1 "CHALLENGE" 0 "IDLE" ;
VAL_ 1229 ExitNotClrRight_B_Stat 1 "True" 0 "False" ;
VAL_ 1229 ExitNotClrLeft_B_Stat 1 "True" 0 "False" ;
VAL_ 1238 TjaLc_D_Stat 0 "Off" 1 "Standby" 2 "AvailableLeft" 3 "AvailableRight" 4 "AvailableLeftRight" 5 "PreparingLeft" 6 "PreparingRight" 7 "LcActiveLeft" 8 "LcActiveRight" 9 "NotUsed_1" 10 "NotUsed_2" 11 "NotUsed_3" 12 "NotUsed_4" 13 "NotUsed_5" 14 "NotUsed_6" 15 "NotUsed_7" ;
VAL_ 1238 TjaLcWarn_D_Rq 0 "NoWarning" 1 "DriverCancel" 2 "SystemCancel" 3 "CancelNoLane" 4 "CancelLaneBusy" 5 "CancelSpeedTooLow" 6 "NotUsed_1" 7 "NotUsed_2" ;
VAL_ 1238 TjaLcMsgTxt_D_Rq 0 "NoMessage" 1 "LcSuggestionLeft" 2 "LcSuggestionRight" 3 "AlcOn" 4 "AlcOff" 5 "TurnOffIndicator" 6 "NotUsed_1" 7 "NotUsed_2" ;
VAL_ 1238 TjaLcEnbl_D_Stat 0 "Inactive" 1 "Off" 2 "On" 3 "NotUsed" ;
VAL_ 1238 TjaCanclMsgTxt_D_Dsply 15 "NotUsed_9" 14 "NotUsed_8" 13 "NotUsed_7" 12 "NotUsed_6" 11 "NotUsed_5" 10 "NotUsed_4" 9 "NotUsed_3" 8 "NotUsed_2" 7 "NotUsed_1" 6 "DriverNotSeen2" 5 "DriverNotSeen1" 4 "HandsFreeUnavailInThisArea" 3 "HandsFreeUnavailForMaxSpd" 2 "CancelledForLaneConditions" 1 "CancelledForRoadCurvature" 0 "NoMessage" ;
VAL_ 1238 TjaLaneBiasEnbl_D_Stat 3 "NotUsed" 0 "Inactive" 2 "Enable" 1 "Disable" ;
VAL_ 1238 AhbcMnu_D_Rq 3 "NotUsed" 2 "Enable" 1 "Disable" 0 "Null" ;
VAL_ 1238 GfhbMnu_D_Rq 3 "EnableADB" 2 "EnableGFHB" 1 "Disable" 0 "Null" ;
VAL_ 1238 TjaLaneBias_D_Stat 7 "NotUsed" 6 "ElBiasRight" 5 "ElBiasLeft" 4 "SystemBiasRight" 3 "SystemBiasLeft" 2 "ManualBiasRight" 1 "ManualBiasLeft" 0 "NoBias" ;
VAL_ 1238 IaccVAdjReas_D_Dsply 15 "NotUsed_21" 11 "NotUsed_1" 10 "SpeedSign" 9 "LeftRamp" 8 "RightRamp" 7 "Roundabout_CCW" 6 "Roundabout_CW" 5 "LeftCurve" 4 "RightCurve" 3 "LeftTurnIntersection" 2 "RightTurnIntersection" 1 "RoadGeometryUnavailable" 0 "NoDisplay" ;
VAL_ 895 TurnLght_D_RqRmtCtl 3 "NotUsed" 2 "Right" 1 "Left" 0 "Null" ;
VAL_ 895 RmtCtlRngSet_D_Rq 3 "NotUsed" 2 "RangeSetB" 1 "RangeSetA" 0 "None" ;
VAL_ 895 RmtCtlKeyPoll_D_Rq 3 "NotUsed" 2 "Polling" 1 "NoPolling" 0 "Null" ;
VAL_ 895 RmtCtlCntnsIn_B_Stat 1 "Available" 0 "NotAvailable" ;
VAL_ 895 RmtCtl_D_Stat 15 "Faulty" 14 "NotUsed_5" 13 "NotUsed_4" 12 "NotUsed_3" 11 "NotUsed_2" 10 "NotUsed_1" 9 "Shutdown" 8 "ManeuverFinished" 7 "ReadyForResume" 6 "Pause" 5 "Maneuvering" 4 "ReadyForManeuvering" 3 "Activation" 2 "Initialize" 1 "Preparation" 0 "Disabled" ;
VAL_ 1092 BattChrgOvrCurnt_B_Falt 1 "Yes" 0 "No" ;
VAL_ 1092 BattTracCell_U_Mx 16383 "Faulty" ;
VAL_ 1092 BattTracMnCell_Te_Actl 255 "Faulty" 254 "NoDataExists" ;
VAL_ 1092 BattTracInsAlrm_B_Stat 1 "Active" 0 "Inactive" ;
VAL_ 1092 BattTracUMx_B_Stat 1 "Active" 0 "Inactive" ;
VAL_ 1092 BattTracTeMx_B_Stat 1 "Exceeded" 0 "NotExceeded" ;
VAL_ 1092 BattTracMxCell_Te_Actl 255 "Faulty" 254 "NoDataExists" ;
VAL_ 1092 BattTracEq_B_Actl 1 "Active" 0 "Inactive" ;
VAL_ 1092 BattTracCell_U_Mn 16383 "Faulty" ;
VAL_ 1092 BattTracUMn_B_Stat 1 "Active" 0 "Inactive" ;
VAL_ 1092 BattTracUAlrm_B_Stat 1 "Active" 0 "Inactive" ;
VAL_ 1092 BattTracTeMn_B_Stat 1 "Exceeded" 0 "NotExceeded" ;
VAL_ 1092 BattTracInsltn_R_Actl 255 "Faulty" ;
VAL_ 1236 ApaSlotRight3_D_Stat 7 "NotUsed_3" 6 "NotUsed_2" 5 "NotUsed_1" 4 "IPeReady" 3 "IPeFound" 2 "IPaReady" 1 "IPaFound" 0 "None" ;
VAL_ 1236 ApaSlotRight3_B_Altr 1 "Available" 0 "NotAvailable" ;
VAL_ 1236 ApaSlotRight2_D_Stat 7 "NotUsed_3" 6 "NotUsed_2" 5 "NotUsed_1" 4 "IPeReady" 3 "IPeFound" 2 "IPaReady" 1 "IPaFound" 0 "None" ;
VAL_ 1236 ApaSlotRight2_B_Altr 1 "Available" 0 "NotAvailable" ;
VAL_ 1236 ApaSlotRight1_D_Stat 7 "NotUsed_3" 6 "NotUsed_2" 5 "NotUsed_1" 4 "IPeReady" 3 "IPeFound" 2 "IPaReady" 1 "IPaFound" 0 "None" ;
VAL_ 1236 ApaSlotRight1_B_Altr 1 "Available" 0 "NotAvailable" ;
VAL_ 1236 ApaSlotRear_D_Stat 1 "True" 0 "False" ;
VAL_ 1235 ApaSlotFront_D_Stat 1 "True" 0 "False" ;
VAL_ 1235 ApaSlotLeft3_D_Stat 7 "NotUsed_3" 6 "NotUsed_2" 5 "NotUsed_1" 4 "IPeReady" 3 "IPeFound" 2 "IPaReady" 1 "IPaFound" 0 "None" ;
VAL_ 1235 ApaSlotLeft3_B_Altr 1 "Available" 0 "NotAvailable" ;
VAL_ 1235 ApaSlotLeft2_D_Stat 7 "NotUsed_3" 6 "NotUsed_2" 5 "NotUsed_1" 4 "IPeReady" 3 "IPeFound" 2 "IPaReady" 1 "IPaFound" 0 "None" ;
VAL_ 1235 ApaSlotLeft2_B_Altr 1 "Unavailable" 0 "Available" ;
VAL_ 1235 ApaSlotLeft1_D_Stat 7 "NotUsed_3" 6 "NotUsed_2" 5 "NotUsed_1" 4 "IPeReady" 3 "IPeFound" 2 "IPaReady" 1 "IPaFound" 0 "None" ;
VAL_ 1235 ApaSlotLeft1_B_Altr 1 "Unavailable" 0 "Available" ;
VAL_ 1234 RmtCtlSnsBlckg_B_Stat 1 "Yes" 0 "No" ;
VAL_ 1234 RmtCtlConfgSrc_D_Stat 7 "NotUsed_2" 6 "NotUsed_1" 5 "BPO" 4 "ApaHmi" 3 "FAP_Handover" 2 "User" 1 "None" 0 "NotDetermined" ;
VAL_ 1234 RmtCtlTrjctry_D_Avail 3 "NotUsed" 2 "Available" 1 "NotAvailable" 0 "Null" ;
VAL_ 1234 RmtCtlSns_D_Err 1 "Yes" 0 "No" ;
VAL_ 1234 RmtCtlPathPlan_D_Stat 7 "NotUsed_3" 6 "NotUsed_2" 5 "NotUsed_1" 4 "FinishedMovesExceeded" 3 "FinishedDistanceExceeded" 2 "Finished" 1 "Ongoing" 0 "None" ;
VAL_ 1234 RmtCtlPathPlan_B_Err 1 "Yes" 0 "No" ;
VAL_ 1234 RmtCtlAdas_D_Stat 7 "Paused" 6 "Abort" 5 "ManeuverFinished" 4 "EndPositionReached" 3 "Backward" 2 "Forward" 1 "ManeuverBegin" 0 "Inactive" ;
VAL_ 1234 RmtCtlAdas_B_Err 1 "Yes" 0 "No" ;
VAL_ 1233 FreeDrvRear_D_Avail 3 "NotUsed" 2 "Available" 1 "NotAvailable" 0 "Null" ;
VAL_ 1233 FreeDrvFwd_D_Avail 3 "NotUsed" 2 "Available" 1 "NotAvailable" 0 "Null" ;
VAL_ 1233 RmtCtlSnsRrCrnr_D_Stat 3 "Zone3" 2 "Zone2" 1 "Zone1" 0 "Off" ;
VAL_ 1233 RmtCtlSnsRlCrnr_D_Stat 3 "Zone3" 2 "Zone2" 1 "Zone1" 0 "Off" ;
VAL_ 1233 RmtCtlSnsRear_D_Stat 3 "Zone3" 2 "Zone2" 1 "Zone1" 0 "Off" ;
VAL_ 1233 RmtCtlSnsFront_D_Stat 3 "Zone3" 2 "Zone2" 1 "Zone1" 0 "Off" ;
VAL_ 1233 RmtCtlSnsFrCrnr_D_Stat 3 "Zone3" 2 "Zone2" 1 "Zone1" 0 "Off" ;
VAL_ 1233 RmtCtlSnsFlCrnr_D_Stat 3 "Zone3" 2 "Zone2" 1 "Zone1" 0 "Off" ;
VAL_ 1233 RmtCtlSideSnsR4_D_Stat 3 "Zone3" 2 "Zone2" 1 "Zone1" 0 "Off" ;
VAL_ 1233 RmtCtlSideSnsR3_D_Stat 3 "Zone3" 2 "Zone2" 1 "Zone1" 0 "Off" ;
VAL_ 1233 RmtCtlSideSnsR2_D_Stat 3 "Zone3" 2 "Zone2" 1 "Zone1" 0 "Off" ;
VAL_ 1233 RmtCtlSideSnsR1_D_Stat 3 "Zone3" 2 "Zone2" 1 "Zone1" 0 "Off" ;
VAL_ 1233 RmtCtlSideSnsL4_D_Stat 3 "Zone3" 2 "Zone2" 1 "Zone1" 0 "Off" ;
VAL_ 1233 RmtCtlSideSnsL3_D_Stat 3 "Zone3" 2 "Zone2" 1 "Zone1" 0 "Off" ;
VAL_ 1233 RmtCtlSideSnsL2_D_Stat 3 "Zone3" 2 "Zone2" 1 "Zone1" 0 "Off" ;
VAL_ 1233 RmtCtlSideSnsL1_D_Stat 3 "Zone3" 2 "Zone2" 1 "Zone1" 0 "Off" ;
VAL_ 1233 RmtCtlRightOrnt_D_Avail 7 "NotUsed_3" 6 "NotUsed_2" 5 "NotUsed_1" 4 "Both" 3 "Backward" 2 "Forward" 1 "None" 0 "NotDetermined" ;
VAL_ 1233 RmtCtlRight_D_Avail 3 "NotUsed" 2 "Available" 1 "NotAvailable" 0 "Null" ;
VAL_ 1233 RmtCtlRear_D_Avail 3 "NotUsed" 2 "Available" 1 "NotAvailable" 0 "Null" ;
VAL_ 1233 RmtCtlPrkMde_D_Stat 3 "NotUsed" 2 "FreeDrive" 1 "ParkIn" 0 "None" ;
VAL_ 1233 RmtCtlPrkInSlot_D_Stat 7 "NotUsed_3" 6 "NotUsed_2" 5 "NotUsed_1" 4 "Right" 3 "Left" 2 "Rear" 1 "Front" 0 "None" ;
VAL_ 1233 RmtCtlObstcl_B_Stat 1 "Yes" 0 "No" ;
VAL_ 1233 RmtCtlNxtMoveDir_D_Stat 3 "NotUsed" 2 "Backward" 1 "Forward" 0 "Null" ;
VAL_ 1233 RmtCtlMoveDir_D_Stat 3 "NotUsed" 2 "Backward" 1 "Forward" 0 "None" ;
VAL_ 1233 RmtCtlLeftOrnt_D_Avail 7 "NotUsed_3" 6 "NotUsed_2" 5 "NotUsed_1" 4 "Both" 3 "Backward" 2 "Forward" 1 "None" 0 "NotDetermined" ;
VAL_ 1233 RmtCtlLeft_D_Avail 3 "NotUsed" 2 "Available" 1 "NotAvailable" 0 "Null" ;
VAL_ 1233 RmtCtlFront_D_Avail 3 "NotUsed" 2 "Available" 1 "NotAvailable" 0 "Null" ;
VAL_ 1149 BattTracPerf_Pc_Dsply 255 "Faulty" 254 "NoDataExists" ;
VAL_ 1149 BattTracPerf_Pc_Actl 255 "Faulty" 254 "NoDataExists" ;
VAL_ 824 DteCldCompltRoute_B_Rq 1 "Yes" 0 "No" ;
VAL_ 824 DteCldTrlrOn_B_Stat 1 "Yes" 0 "No" ;
VAL_ 824 DteCldTrlrOff_B_Stat 1 "Yes" 0 "No" ;
VAL_ 824 DteCldTraffic_B_Stat 1 "Yes" 0 "No" ;
VAL_ 824 DteCldTerrain_B_Stat 1 "Yes" 0 "No" ;
VAL_ 824 DteCldRoute_B_Stat 1 "Yes" 0 "No" ;
VAL_ 824 DteCldPayload_B_Stat 1 "Yes" 0 "No" ;
VAL_ 824 DteCldExtTe_B_Stat 1 "Yes" 0 "No" ;
VAL_ 824 DteCldDcac_B_Stat 1 "Yes" 0 "No" ;
VAL_ 824 DteCldTrip_L2_Actl 8191 "Faulty" 8190 "NoDataExists" ;
VAL_ 811 SpeedoMajorUnit_D_Confg 3 "NotUsed" 2 "Kph" 1 "Mph" 0 "Null" ;
VAL_ 811 ScMnSoc_Pc_RqMnu 127 "Faulty" 126 "NoDataExists" ;
VAL_ 811 ScEnbl_D_RqMnu 3 "NotUsed" 2 "On" 1 "Off" 0 "Null" ;
VAL_ 811 OnePdlDrvButtn_B_Falt 1 "Faulted" 0 "NotFaulted" ;
VAL_ 811 OnePdlDrvButtn_B_Stat 1 "Pressed" 0 "Not_Pressed" ;
VAL_ 811 DistToStopover_L_Actl 65535 "Faulty" ;
VAL_ 811 StopoverType_D_Stat 7 "Faulty" 6 "NotUsed_1" 5 "Other" 4 "Work" 3 "Home" 2 "ChargeStation" 1 "FinalDestination" 0 "Null" ;
VAL_ 811 ExtLghtDsply_D_Stat 7 "NotUsed" 6 "PressToOn3" 5 "PressToOff3" 4 "PressToOn2" 3 "PressToOff2" 2 "PressToOn1" 1 "PressToOff1" 0 "Reset" ;
VAL_ 811 ExtLghtRight_D_RqMnu 7 "NotUsed" 6 "PressToOn3" 5 "PressToOff3" 4 "PressToOn2" 3 "PressToOff2" 2 "PressToOn1" 1 "PressToOff1" 0 "Reset" ;
VAL_ 811 AutoLghtOvrrd_B_RqDrv 1 "Allowed" 0 "NotAllowed" ;
VAL_ 811 ExtLghtRear_D_RqMnu 7 "NotUsed" 6 "PressToOn3" 5 "PressToOff3" 4 "PressToOn2" 3 "PressToOff2" 2 "PressToOn1" 1 "PressToOff1" 0 "Reset" ;
VAL_ 811 LongTermReset_B_RqMnu 1 "On" 0 "Off" ;
VAL_ 811 ExtLghtLeft_D_RqMnu 7 "NotUsed" 6 "PressToOn3" 5 "PressToOff3" 4 "PressToOn2" 3 "PressToOff2" 2 "PressToOn1" 1 "PressToOff1" 0 "Reset" ;
VAL_ 811 ExtLghtFront_D_RqMnu 7 "NotUsed" 6 "PressToOn3" 5 "PressToOff3" 4 "PressToOn2" 3 "PressToOff2" 2 "PressToOn1" 1 "PressToOff1" 0 "Reset" ;
VAL_ 811 GoTEditMnte_T_RqMnu 15 "Faulty" 14 "NoDataExists" 13 "NotUsed_2" 12 "NotUsed_1" 11 "Minute_55" 10 "Minute_50" 9 "Minute_45" 8 "Minute_40" 7 "Minute_35" 6 "Minute_30" 5 "Minute_25" 4 "Minute_20" 3 "Minute_15" 2 "Minute_10" 1 "Minute_5" 0 "Minute_0" ;
VAL_ 811 GoTEditHr_T_RqMnu 31 "Faulty" 30 "NoDataExists" ;
VAL_ 942 ApaOffOptnSel_B_Avail 1 "Available" 0 "NotAvailable" ;
VAL_ 942 PrkBrkElRleas_B_RqApa 1 "Yes" 0 "No" ;
VAL_ 942 ApaDrvRq2MsgTxt_D_Rq 15 "NotUsed_7" 14 "NotUsed_6" 13 "NotUsed_5" 12 "NotUsed_4" 11 "NotUsed_3" 10 "NotUsed_2" 9 "NotUsed_1" 8 "CloseDoor" 7 "TakeControl" 6 "ReleaseEpb" 5 "ReleaseSteering" 4 "ReleaseBrake" 3 "DriveBackward" 2 "DriveForward" 1 "Stop" 0 "NoRequest" ;
VAL_ 942 ApaDrvRq1MsgTxt_D_Rq 7 "NotUsed" 6 "ExitVehicle" 5 "PressApaButton" 4 "ShiftToP" 3 "ShiftToN" 2 "ShiftToD" 1 "ShiftToR" 0 "NoRequest" ;
VAL_ 942 ApaSys_D2_Stat 15 "NotUsed_5" 14 "NotUsed_4" 13 "NotUsed_3" 12 "NotUsed_2" 11 "NotUsed_1" 10 "NoSideSelectable" 9 "RightSideSelectable" 8 "LeftSideSelectable" 7 "BothSidesSelectable" 6 "Faulty" 5 "Finished" 4 "Cancelled" 3 "NotAvailable" 2 "Overspeed" 1 "Pause" 0 "NormalOperation" ;
VAL_ 942 ApaSlotTrgt_D_Stat 15 "NotUsed_7" 14 "NotUsed_6" 13 "NotUsed_5" 12 "NotUsed_4" 11 "NotUsed_3" 10 "NotUsed_2" 9 "NotUsed_1" 8 "Front" 7 "Rear" 6 "Right3" 5 "Right2" 4 "Right1" 3 "Left3" 2 "Left2" 1 "Left1" 0 "None" ;
VAL_ 942 ApaSlotOption_B_Avail 1 "Available" 0 "NotAvailable" ;
VAL_ 942 ApaSlotAlrtSet_B_Stat 1 "Enable" 0 "Disable" ;
VAL_ 942 ApaSlotAlrt_B_Rq 1 "True" 0 "False" ;
VAL_ 942 ApaRmtFeatSel_B_Avail 1 "Available" 0 "NotAvailable" ;
VAL_ 942 ApaParkOutSel_B_Avail 1 "Available" 0 "NotAvailable" ;
VAL_ 942 ApaParkInSel_B_Avail 1 "Available" 0 "NotAvailable" ;
VAL_ 942 ApaMsgTxt_D2_Stat 15 "ReducedFunction" 14 "TrailerFeatureNotAvailable" 13 "AcceleratorPedalInactive" 12 "SensorsBlocked" 11 "TrailerAttached" 10 "TcsDeactivated" 9 "WheelSlip" 8 "HighInclination" 7 "DoorOpen" 6 "SteeringInteraction" 5 "WrongDirection" 4 "SpeedLimitExceeded" 3 "BrakeEvent" 2 "ObstacleInPath" 1 "WaitForSteering" 0 "None" ;
VAL_ 942 ApaDynmcSlot_B_Stat 1 "On" 0 "Off" ;
VAL_ 942 ApaDisplayMode_D_Stat 3 "NotUsed" 2 "FullScreen" 1 "Menu" 0 "Off" ;
VAL_ 942 ApaControlMode_D_Stat 1 "Active" 0 "Inactive" ;
VAL_ 942 PrkAidAcsyRear_D_Stat 3 "NotUsed" 2 "On" 1 "Off" 0 "Null" ;
VAL_ 942 PrkAidAcsyFront_D_Stat 3 "NotUsed" 2 "On" 1 "Off" 0 "Null" ;
VAL_ 942 PrkAidDrvDir_D_Stat 7 "NotUsed_2" 6 "NotUsed_1" 5 "BackwardNegative" 4 "ForwardNegative" 3 "BackwardPositive" 2 "ForwardPositive" 1 "NoMotion" 0 "DirectionNotKnown" ;
VAL_ 123 BattTrac_U2_Actl 4095 "Faulty" 4094 "NoDataExists" ;
VAL_ 123 BattTrac_I2_Actl 262143 "Faulty" 262142 "NoDataExists" ;
VAL_ 1239 CstmDrvMdeTracCtl_D_Rq 3 "App_Specific_Off_Mode_3" 2 "App_Specific_Off_Mode_2" 1 "App_Specific_Off_Mode_1" 0 "Default_Mode" ;
VAL_ 1239 CstmDrvMdeChassis_D_Rq 31 "Faulty" 30 "NotUsed17" 29 "NotUsed16" 28 "NotUsed15" 27 "NotUsed14" 26 "NotUsed13" 25 "NotUsed12" 24 "NotUsed11" 23 "NotUsed10" 22 "NotUsed9" 21 "NotUsed8" 20 "NotUsed7" 19 "NotUsed6" 18 "NotUsed5" 17 "NotUsed4" 16 "OnePedalDrive" 15 "DragMode" 14 "RoughRoadMode" 13 "TrackMode" 12 "HighSpeedDesertMode" 11 "TowHaulMode" 10 "RockCrawlMode" 9 "SandMode" 8 "MudAndRutsMode" 7 "LowMuMode" 6 "ComfortAdaptiveMode" 5 "ComfortMode" 4 "SportAdaptiveMode" 3 "SportMode" 2 "EconomyMode" 1 "NormalAdaptiveMode" 0 "NormalMode" ;
VAL_ 1239 CstmDrvMdeHmi2_D_Rq 31 "Faulty" 30 "SelDrvMde31" 29 "SelDrvMde30" 28 "SelDrvMde29" 27 "SelDrvMde28" 26 "SelDrvMde27" 25 "SelDrvMde26" 24 "SelDrvMde25" 23 "SelDrvMde24" 22 "SelDrvMde23" 21 "SelDrvMde22" 20 "SelDrvMde21" 19 "SelDrvMde20" 18 "SelDrvMde19" 17 "SelDrvMde18" 16 "SelDrvMde17" 15 "SelDrvMde16" 14 "SelDrvMde15" 13 "SelDrvMde14" 12 "SelDrvMde13" 11 "SelDrvMde12" 10 "SelDrvMde11" 9 "SelDrvMde10" 8 "SelDrvMde09" 7 "SelDrvMde08" 6 "SelDrvMde07" 5 "SelDrvMde06" 4 "SelDrvMde05" 3 "SelDrvMde04" 2 "SelDrvMde03" 1 "SelDrvMde02" 0 "SelDrvMde01" ;
VAL_ 1239 SelDrvMdeCstmLamp_D_Rq 3 "NotUsed2" 2 "NotUsed1" 1 "On" 0 "Off" ;
VAL_ 1239 SelDrvMdeCstm_D_RqDrv 7 "Faulty" 6 "NotUsed_3" 5 "NotUsed_2" 4 "NotUsed_1" 3 "Recall" 2 "Save" 1 "Activate" 0 "Null" ;
VAL_ 1239 StabBarCnnctLamp_D_Cstm 3 "Fast_Flash" 2 "Slow_Flash" 1 "On" 0 "Off" ;
VAL_ 1239 CstmDrvMdeMsgTxt_D_Rq 15 "Message15" 14 "Message14" 13 "Message13" 12 "Message12" 11 "Message11" 10 "Message10" 9 "Message9" 8 "Message8" 7 "Message7" 6 "Message6" 5 "Message5" 4 "Message4" 3 "Message3" 2 "Message2" 1 "Message1" 0 "NoMessage" ;
VAL_ 1239 ActvDrvMdeCstm_D2_Rq 31 "Faulty" 30 "SelDrvMde31" 29 "SelDrvMde30" 28 "SelDrvMde29" 27 "SelDrvMde28" 26 "SelDrvMde27" 25 "SelDrvMde26" 24 "SelDrvMde25" 23 "SelDrvMde24" 22 "SelDrvMde23" 21 "SelDrvMde22" 20 "SelDrvMde21" 19 "SelDrvMde20" 18 "SelDrvMde19" 17 "SelDrvMde18" 16 "SelDrvMde17" 15 "SelDrvMde16" 14 "SelDrvMde15" 13 "SelDrvMde14" 12 "SelDrvMde13" 11 "SelDrvMde12" 10 "SelDrvMde11" 9 "SelDrvMde10" 8 "SelDrvMde09" 7 "SelDrvMde08" 6 "SelDrvMde07" 5 "SelDrvMde06" 4 "SelDrvMde05" 3 "SelDrvMde04" 2 "SelDrvMde03" 1 "SelDrvMde02" 0 "SelDrvMde01" ;
VAL_ 949 Tire_Press_RR_ORR_Data 65535 "Not_Supported" 65534 "Invalid" 65533 "Unknown" ;
VAL_ 949 Tire_Press_LR_OLR_Data 65535 "Not_Supported" 65534 "Invalid" 65533 "Unknown" ;
VAL_ 949 Tire_Press_LF_Data 65535 "Not_Supported" 65534 "Invalid" 65533 "Unknown" ;
VAL_ 949 Tire_Press_RF_Data 65535 "Not_Supported" 65534 "Invalid" 65533 "Unknown" ;
VAL_ 639 OfbTrgtSocOvrrd_D_Rq 3 "NotUsed" 2 "Enable" 1 "Disable" 0 "Null" ;
VAL_ 639 OfbChrgPrflUpdate_B_Rq 1 "Request" 0 "NoRequest" ;
VAL_ 639 OfbChrgClearAll_B_Rq 1 "Request" 0 "NoRequest" ;
VAL_ 639 OfbChrgGoTTouch_D_Rq 3 "NotUsed" 2 "On" 1 "Off" 0 "Null" ;
VAL_ 639 OfbChrgGoTPrcond_D_Rq 3 "High" 2 "Medium" 1 "Low" 0 "Off" ;
VAL_ 639 OfbChrgGoTOn_D_Rq 3 "NotUsed" 2 "On" 1 "Off" 0 "Null" ;
VAL_ 639 OfbChrgGoTMnte_D_Rq 15 "NotUsed_4" 14 "NotUsed_3" 13 "NotUsed_2" 12 "NotUsed_1" 11 "Minute_55" 10 "Minute_50" 9 "Minute_45" 8 "Minute_40" 7 "Minute_35" 6 "Minute_30" 5 "Minute_25" 4 "Minute_20" 3 "Minute_15" 2 "Minute_10" 1 "Minute_5" 0 "Minute_0" ;
VAL_ 639 OfbChrgGoTHr_T_Rq 31 "Faulty" 30 "NoDataExists" ;
VAL_ 639 OfbChrgGoTExtHtr_D_Rq 3 "NotUsed" 2 "On" 1 "Off" 0 "Null" ;
VAL_ 639 OfbChrgGoTDelete_B_Rq 1 "Request" 0 "NoRequest" ;
VAL_ 639 OfbChrgGoTUpdate_B_Rq 1 "Request" 0 "NoRequest" ;
VAL_ 530 OfbChrgToPcWknd_D_Actl 7 "Percent_50" 6 "Percent_60" 5 "Percent_70" 4 "Percent_80" 3 "Percent_85" 2 "Percent_90" 1 "Percent_95" 0 "Percent_100" ;
VAL_ 530 OfbChrgToPcWkdy_D_Actl 7 "Percent_50" 6 "Percent_60" 5 "Percent_70" 4 "Percent_80" 3 "Percent_85" 2 "Percent_90" 1 "Percent_95" 0 "Percent_100" ;
VAL_ 530 OfbChrgSetNow_D_Rq 3 "NotUsed" 2 "On" 1 "Off" 0 "Null" ;
VAL_ 530 OfbChrgSetDelete_B_Rq 1 "Request" 0 "NoRequest" ;
VAL_ 530 OfbChrgLocIdUns_B_Rq 1 "Request" 0 "NoRequest" ;
VAL_ 550 PtWakeupActv1_B_Rq 1 "Wake_up_Powertrain_via_HW" 0 "Don_t_Wake_Up_Powertrain" ;
VAL_ 885 BattULoChrg_D_RqOta 1 "Yes" 0 "No" ;
VAL_ 885 VehStrtInhbt_D_Dsply 15 "NotUsed_12" 14 "NotUsed_11" 13 "NotUsed_10" 12 "NotUsed_9" 11 "NotUsed_8" 10 "NotUsed_7" 9 "NotUsed_6" 8 "NotUsed_5" 7 "NotUsed_4" 6 "FleetPhoneNumber" 5 "FleetGeneral" 4 "OtaSuccess" 3 "PostOtaActivatePermFail" 2 "PostOtaActivateWarning" 1 "DuringOtaActivate" 0 "NoMessage" ;
VAL_ 885 VehOnRqstr_D_Stat 11 "NotUsed_8" 10 "NotUsed_7" 9 "NotUsed_6" 8 "NotUsed_5" 7 "NotUsed_4" 6 "NotUsed_3" 5 "NotUsed_2" 4 "NotUsed_1" 3 "FleetVehInhbt" 2 "StolenVehInhbt" 1 "OverTheAir" 0 "NoRequestor" 15 "NotUsed_12" 14 "NotUsed_11" 13 "NotUsed_10" 12 "NotUsed_9" ;
VAL_ 885 VehStrtInhbt_D_RqCld 3 "NotUsed" 2 "On" 1 "Off" 0 "Null" ;
VAL_ 885 VehOn_D_RqCld 3 "NoControl" 2 "On" 1 "Off" 0 "Null" ;
VAL_ 885 OtaActv_D_Stat 15 "NotUsed_10" 14 "NotUsed_9" 13 "NotUsed_8" 12 "NotUsed_7" 11 "NotUsed_6" 10 "NotUsed_5" 9 "NotUsed_4" 8 "NotUsed_3" 7 "NotUsed_2" 6 "NotUsed_1" 5 "NonInterruptible_Pending" 4 "NonInterruptible_Config" 3 "NonInterruptible_ER" 2 "NonInterruptible_AB" 1 "Interruptible_AB" 0 "NoInVehicleOta" ;
VAL_ 739 BptMde_D_RqMnu 7 "NotUsed_4" 6 "NotUsed_3" 5 "NotUsed_2" 4 "NotUsed_1" 3 "Automatic" 2 "Manual" 1 "Off" 0 "Null" ;
VAL_ 739 BptMnSoc_L_RqMnu 8191 "Faulty" 8190 "NoDataExists" ;
VAL_ 739 BptStrtStop_D_RqMnu 3 "NotUsed_1" 2 "Start" 1 "Stop" 0 "NoRequest" ;
VAL_ 739 BabySeatInUse_D_Stat 3 "NotUsed" 2 "InUse" 1 "NotInUse" 0 "Null" ;
VAL_ 739 VehHornOccAlrt_D_Stat 3 "NotUsed" 2 "On" 1 "Off" 0 "Null" ;
VAL_ 739 SeatOccChime_B_RqCancl 1 "Cancel" 0 "Null" ;
VAL_ 739 SeatOccRear_D_Stat 3 "NotUsed" 2 "On" 1 "Off" 0 "Null" ;
VAL_ 739 EngExhMdeHrStrt_D_Rq 31 "NotUsed_7" 30 "NotUsed_6" 29 "NotUsed_5" 28 "NotUsed_4" 27 "NotUsed_3" 26 "NotUsed_2" 25 "NotUsed_1" 24 "Hour23_11pm" 23 "Hour22_10pm" 22 "Hour21_9pm" 21 "Hour20_8pm" 20 "Hour19_7pm" 19 "Hour18_6pm" 18 "Hour17_5pm" 17 "Hour16_4pm" 16 "Hour15_3pm" 15 "Hour14_2pm" 14 "Hour13_1pm" 13 "Hour12_12pm" 12 "Hour11_11am" 11 "Hour10_10am" 10 "Hour9_9am" 9 "Hour8_8am" 8 "Hour7_7am" 7 "Hour6_6am" 6 "Hour5_5am" 5 "Hour4_4am" 4 "Hour3_3am" 3 "Hour2_2am" 2 "Hour1_1am" 1 "Hour0_12am" 0 "Null" ;
VAL_ 739 EngExhMdeHrEnd_D_Rq 31 "NotUsed_7" 30 "NotUsed_6" 29 "NotUsed_5" 28 "NotUsed_4" 27 "NotUsed_3" 26 "NotUsed_2" 25 "NotUsed_1" 24 "Hour23_11pm" 23 "Hour22_10pm" 22 "Hour21_9pm" 21 "Hour20_8pm" 20 "Hour19_7pm" 19 "Hour18_6pm" 18 "Hour17_5pm" 17 "Hour16_4pm" 16 "Hour15_3pm" 15 "Hour14_2pm" 14 "Hour13_1pm" 13 "Hour12_12pm" 12 "Hour11_11am" 11 "Hour10_10am" 10 "Hour9_9am" 9 "Hour8_8am" 8 "Hour7_7am" 7 "Hour6_6am" 6 "Hour5_5am" 5 "Hour4_4am" 4 "Hour3_3am" 3 "Hour2_2am" 2 "Hour1_1am" 1 "Hour0_12am" 0 "Null" ;
VAL_ 739 EngExhMdeHrEnbl_D_Rq 3 "NotConfigured" 2 "Enabled" 1 "Disabled" 0 "Null" ;
VAL_ 739 BptDly_T_RqMnu 63 "Faulty" 62 "NoDataExists" ;
VAL_ 739 Partial_Amp_Shutdown 1 "Active" 0 "Inactive" ;
VAL_ 739 HMI_HMIMode_St 7 "NotUsed2" 6 "NotUsed1" 5 "Load_Shed_Active" 0 "Invalid" 1 "OffMode" 2 "On" 3 "Phone" 4 "Climate" ;
VAL_ 1160 HybMdeGzg_D_Rq 7 "NotUsed_2" 6 "NotUsed_1" 5 "EV_Override_Mode" 4 "EV_Charge_Mode" 3 "EV_Later_Mode" 2 "EV_Now_Mode" 1 "EV_Auto_Mode" 0 "Null" ;
VAL_ 1160 ReFuelSwtchStat_D_Actl2 3 "NotUsed_2" 2 "NotUsed_1" 1 "On" 0 "Off" ;
VAL_ 1160 DcacPwReset_B_RqCell 1 "Reset" 0 "Null" ;
VAL_ 1160 DcacPw_D_RqCell 3 "High" 2 "Low" 1 "Off" 0 "Null" ;
VAL_ 1160 DgtlCommPncReset_B_Req 1 "Yes" 0 "No" ;
VAL_ 1160 DgtlCommPnc_D_Rq 3 "DeleteAll" 2 "Disable" 1 "Reset" 0 "NoRequest" ;
VAL_ 1160 DataMntrSustn_B_Rq 1 "Active" 0 "Inactive" ;
VAL_ 1160 PwSustnRdata_B_RqTelem 1 "Active" 0 "Inactive" ;
VAL_ 945 PrkLckCtlMsgTxt_D2_Rq 7 "Message7" 6 "Message6" 5 "Message5" 4 "Message4" 3 "Message3" 2 "Message2" 1 "Message1" 0 "NoMessage" ;
VAL_ 945 KeyPadCodeDgt7_D_Dsply 15 "NotUsed_4" 14 "NotUsed_3" 13 "NotUsed_2" 12 "NotUsed_1" 11 "Button7_8and9_0" 10 "Button0" 9 "Button9_0or9" 8 "Button8" 7 "Button7_8or7" 6 "Button6" 5 "Button5_6or5" 4 "Button4" 3 "Button3_4or3" 2 "Button2" 1 "Button1_2or1" 0 "EndofString" ;
VAL_ 945 KeyPadCodeDgt6_D_Dsply 15 "NotUsed_4" 14 "NotUsed_3" 13 "NotUsed_2" 12 "NotUsed_1" 11 "Button7_8and9_0" 10 "Button0" 9 "Button9_0or9" 8 "Button8" 7 "Button7_8or7" 6 "Button6" 5 "Button5_6or5" 4 "Button4" 3 "Button3_4or3" 2 "Button2" 1 "Button1_2or1" 0 "EndofString" ;
VAL_ 945 KeyPadCodeDgt5_D_Dsply 15 "NotUsed_4" 14 "NotUsed_3" 13 "NotUsed_2" 12 "NotUsed_1" 11 "Button7_8and9_0" 10 "Button0" 9 "Button9_0or9" 8 "Button8" 7 "Button7_8or7" 6 "Button6" 5 "Button5_6or5" 4 "Button4" 3 "Button3_4or3" 2 "Button2" 1 "Button1_2or1" 0 "EndofString" ;
VAL_ 945 KeyPadCodeDgt4_D_Dsply 15 "NotUsed_4" 14 "NotUsed_3" 13 "NotUsed_2" 12 "NotUsed_1" 11 "Button7_8and9_0" 10 "Button0" 9 "Button9_0or9" 8 "Button8" 7 "Button7_8or7" 6 "Button6" 5 "Button5_6or5" 4 "Button4" 3 "Button3_4or3" 2 "Button2" 1 "Button1_2or1" 0 "EndofString" ;
VAL_ 945 KeyPadCodeDgt3_D_Dsply 15 "NotUsed_4" 14 "NotUsed_3" 13 "NotUsed_2" 12 "NotUsed_1" 11 "Button7_8and9_0" 10 "Button0" 9 "Button9_0or9" 8 "Button8" 7 "Button7_8or7" 6 "Button6" 5 "Button5_6or5" 4 "Button4" 3 "Button3_4or3" 2 "Button2" 1 "Button1_2or1" 0 "EndofString" ;
VAL_ 945 KeyPadCodeDgt2_D_Dsply 15 "NotUsed_4" 14 "NotUsed_3" 13 "NotUsed_2" 12 "NotUsed_1" 11 "Button7_8and9_0" 10 "Button0" 9 "Button9_0or9" 8 "Button8" 7 "Button7_8or7" 6 "Button6" 5 "Button5_6or5" 4 "Button4" 3 "Button3_4or3" 2 "Button2" 1 "Button1_2or1" 0 "EndofString" ;
VAL_ 945 KeyPadCodeDgt1_D_Dsply 15 "NotUsed_4" 14 "NotUsed_3" 13 "NotUsed_2" 12 "NotUsed_1" 11 "Button7_8and9_0" 10 "Button0" 9 "Button9_0or9" 8 "Button8" 7 "Button7_8or7" 6 "Button6" 5 "Button5_6or5" 4 "Button4" 3 "Button3_4or3" 2 "Button2" 1 "Button1_2or1" 0 "EndofString" ;
VAL_ 945 KeyOffMde_D_Actl 15 "NotUsed_11" 14 "NotUsed_10" 13 "NotUsed_9" 12 "NotUsed_8" 11 "NotUsed_7" 10 "NotUsed_6" 9 "NotUsed_5" 8 "NotUsed_4" 7 "NotUsed_3" 6 "NotUsed_2" 5 "NotUsed_1" 4 "CriticalBattery" 3 "Hibernate" 2 "Transport" 1 "Factory" 0 "Normal" ;
VAL_ 945 PrkLckCtlLatch_B_Rq 1 "On" 0 "Off" ;
VAL_ 395 SelDrvMdeCnfm_D_Stat 3 "NotUsed" 2 "Accepted" 1 "NotAccepted" 0 "Null" ;
VAL_ 395 HudMde_D_Rq 7 "NotUsed3" 6 "NotUsed2" 5 "NotUsed1" 4 "Manual" 3 "Drag" 2 "RoadCourse" 1 "Tach" 0 "Off" ;
VAL_ 395 HudLedMde_D_Rq 3 "Not_Used" 2 "Flash" 1 "On" 0 "Off" ;
VAL_ 395 HudLed9On_B_Rq 1 "On" 0 "Off" ;
VAL_ 395 HudLed8On_B_Rq 1 "On" 0 "Off" ;
VAL_ 395 HudLed7On_B_Rq 1 "On" 0 "Off" ;
VAL_ 395 HudLed6On_B_Rq 1 "On" 0 "Off" ;
VAL_ 395 HudLed5On_B_Rq 1 "On" 0 "Off" ;
VAL_ 395 HudLed4On_B_Rq 1 "On" 0 "Off" ;
VAL_ 395 HudLed3On_B_Rq 1 "On" 0 "Off" ;
VAL_ 395 HudLed2On_B_Rq 1 "On" 0 "Off" ;
VAL_ 395 HudLed1On_B_Rq 1 "On" 0 "Off" ;
VAL_ 395 HudLed18On_B_Rq 1 "On" 0 "Off" ;
VAL_ 395 HudLed17On_B_Rq 1 "On" 0 "Off" ;
VAL_ 395 HudLed16On_B_Rq 1 "On" 0 "Off" ;
VAL_ 395 HudLed15On_B_Rq 1 "On" 0 "Off" ;
VAL_ 395 HudLed14On_B_Rq 1 "On" 0 "Off" ;
VAL_ 395 HudLed13On_B_Rq 1 "On" 0 "Off" ;
VAL_ 395 HudLed12On_B_Rq 1 "On" 0 "Off" ;
VAL_ 395 HudLed11On_B_Rq 1 "On" 0 "Off" ;
VAL_ 395 HudLed10On_B_Rq 1 "On" 0 "Off" ;
VAL_ 515 PtIgnSwtch_D_Stat 3 "Faulty" 2 "No_Data_Exists" 1 "On" 0 "Off" ;
VAL_ 982 LatCtlRampType_D_Rq 3 "Immediately" 2 "Fast" 1 "Medium" 0 "Slow" ;
VAL_ 982 LatCtl_D2_Rq 7 "NotUsed_5" 6 "NotUsed_4" 5 "NotUsed_3" 4 "LaneChange" 3 "SafeRampOut" 2 "PathFollowingExtendedMode" 1 "PathFollowingLimitedMode" 0 "NoLateralControl" ;
VAL_ 982 LatCtlPrecision_D_Rq 3 "NotUsed2" 2 "NotUsed1" 1 "Precise" 0 "Comfortable" ;
VAL_ 982 HandsOffCnfm_B_Rq 1 "Active" 0 "Inactive" ;
VAL_ 1104 DrvEngageLevel_D_Stat 7 "Faulty" 6 "NotUsed_2" 5 "NotUsed_1" 4 "Disengaged" 3 "Distracted" 2 "Attentive" 1 "Invalid" 0 "NotDetermined" ;
VAL_ 1104 DrvImpLvlConfid_D_Stat 7 "Faulty" 6 "NotUsed" 5 "High" 4 "MediumHigh" 3 "Medium" 2 "LowMedium" 1 "Low" 0 "NotDetermined" ;
VAL_ 1104 DrvImpairLvl_D_Stat 15 "Faulty" 14 "NotUsed_5" 13 "NotUsed_4" 12 "NotUsed_3" 11 "NotUsed_2" 10 "NotUsed_1" 9 "Incapacitated" 8 "Asleep" 7 "Microsleep" 6 "MostDrowsy" 5 "Drowsy_4" 4 "Drowsy_3" 3 "Drowsy_2" 2 "LeastDrowsy" 1 "Alert" 0 "NotDetermined" ;
VAL_ 1104 DrvEngLvlConfid_D_Stat 7 "Faulty" 6 "NotUsed" 5 "High" 4 "MediumHigh" 3 "Medium" 2 "LowMedium" 1 "Low" 0 "NotDetermined" ;
VAL_ 1104 DrvCamPassIR_D_Stat 3 "Faulty" 2 "Blocked" 1 "Ok" 0 "TemporaryUnavailable" ;
VAL_ 1104 DrvCamera_D_Stat 3 "Faulty" 2 "Blocked" 1 "Ok" 0 "TemporaryUnavailable" ;
VAL_ 1104 DrvCamDrvIR_D_Stat 3 "Faulty" 2 "Blocked" 1 "Ok" 0 "TemporaryUnavailable" ;
VAL_ 1104 DrvAttentZone_D_Stat 15 "Faulty" 14 "NotUsed_5" 13 "NotUsed_4" 12 "NotUsed_3" 11 "NotConfigured" 10 "DriverLap" 9 "PassengerSideWindow" 8 "DriverSideWindow" 7 "DriverSideMirror" 6 "RearviewMirror" 5 "PassengerSideMirror" 4 "Infotainment" 3 "Cluster" 2 "FrontWindshield" 1 "Other" 0 "NotDetermined" ;
VAL_ 1104 DrvAlertSt_D_Stat 3 "Faulty" 2 "EyesOffRoad" 1 "EyesOnRoad" 0 "NotDetermined" ;
SIG_GROUP_ 885 Profile1A_SigGroup_FD1_375 1 : BattULoChrg_D_RqOta VehStrtInhbt_T_Dsply VehStrtInhbt_D_Dsply OtaActv_D_Stat VehOn_D_RqCld VehOnRqstr_D_Stat VehStrtInhbt_D_RqCld CanMsg375_No_Cnt CanMsg375_No_Crc;
